[part 19 of 23: packages /Interfaces to /ComponentTypes]
AUTOSAR XML (schema 4-3-0)
package /Interfaces
  2014 x sender receiver interface:
    IF_AB_Abschaltanf_SIH_BF
      data DE_AB_Abschaltanf_SIH_BF: type=boolean
    IF_AB_Belegung_VB
      data DE_AB_Belegung_VB: type=uint8
    IF_AB_Belegung_VF
      data DE_AB_Belegung_VF: type=uint8
    IF_AB_Belegung_VF_ext
      data DE_AB_Belegung_VF_ext: type=uint8
    IF_AB_Crash_Int
      data DE_AB_Crash_Int: type=uint8
    IF_AB_Deaktivierung_HV
      data DE_AB_Deaktivierung_HV: type=uint8
    IF_AB_Gurtschloss_BF
      data DE_AB_Gurtschloss_BF: type=uint8
    IF_AB_Gurtschloss_FA
      data DE_AB_Gurtschloss_FA: type=uint8
    IF_AB_Gurtschloss_MI
      data DE_AB_Gurtschloss_MI: type=uint8
    IF_AB_Gurtschloss_Reihe2_BF
      data DE_AB_Gurtschloss_Reihe2_BF: type=uint8
    IF_AB_Gurtschloss_Reihe2_FA
      data DE_AB_Gurtschloss_Reihe2_FA: type=uint8
    IF_AB_Gurtschloss_Reihe2_MI
      data DE_AB_Gurtschloss_Reihe2_MI: type=uint8
    IF_AB_Gurtschloss_Reihe3_BF
      data DE_AB_Gurtschloss_Reihe3_BF: type=uint8
    IF_AB_Gurtschloss_Reihe3_FA
      data DE_AB_Gurtschloss_Reihe3_FA: type=uint8
    IF_AB_Gurtschloss_Reihe3_MI
      data DE_AB_Gurtschloss_Reihe3_MI: type=uint8
    IF_AB_Gurtwarn_Reihe2_BF
      data DE_AB_Gurtwarn_Reihe2_BF: type=uint8
    IF_AB_Gurtwarn_Reihe2_FA
      data DE_AB_Gurtwarn_Reihe2_FA: type=uint8
    IF_AB_Gurtwarn_Reihe2_MI
      data DE_AB_Gurtwarn_Reihe2_MI: type=uint8
    IF_AB_Gurtwarn_Reihe3_BF
      data DE_AB_Gurtwarn_Reihe3_BF: type=uint8
    IF_AB_Gurtwarn_Reihe3_FA
      data DE_AB_Gurtwarn_Reihe3_FA: type=uint8
    IF_AB_Gurtwarn_Reihe3_MI
      data DE_AB_Gurtwarn_Reihe3_MI: type=uint8
    IF_AB_Gurtwarn_VM
      data DE_AB_Gurtwarn_VM: type=boolean
    IF_AB_SBR_hinten_verbau
      data DE_AB_SBR_hinten_verbau: type=uint8
    IF_AB_Stellgliedtest
      data DE_AB_Stellgliedtest: type=boolean
    IF_ACT401_Adresse_Aktuator
      data DE_ACT401_Adresse_Aktuator: type=uint8
    IF_ACT401_Blockierung_aufgetreten
      data DE_ACT401_Blockierung_aufgetreten: type=uint8
    IF_ACT401_Drehrichtung
      data DE_ACT401_Drehrichtung: type=uint8
    IF_ACT401_Elektr_Defekt
      data DE_ACT401_Elektr_Defekt: type=uint8
    IF_ACT401_Freigabe_Blockiererkennung
      data DE_ACT401_Freigabe_Blockiererkennung: type=uint8
    IF_ACT401_Geschwindigkeitsstatus
      data DE_ACT401_Geschwindigkeitsstatus: type=uint8
    IF_ACT401_Ist_Position_Aktuator
      data DE_ACT401_Ist_Position_Aktuator: type=uint16
    IF_ACT401_Notlauf_aufgetreten
      data DE_ACT401_Notlauf_aufgetreten: type=uint8
    IF_ACT401_Notlauffreigabe
      data DE_ACT401_Notlauffreigabe: type=uint8
    IF_ACT401_Notlaufposition
      data DE_ACT401_Notlaufposition: type=uint8
    IF_ACT401_Positionsvorgabe_Status
      data DE_ACT401_Positionsvorgabe_Status: type=uint8
    IF_ACT401_Reset
      data DE_ACT401_Reset: type=uint8
    IF_ACT401_ResponseError
      data DE_ACT401_ResponseError: type=boolean
    IF_ACT401_Selbsthaltemoment
      data DE_ACT401_Selbsthaltemoment: type=uint8
    IF_ACT401_Sonderfunktionen
      data DE_ACT401_Sonderfunktionen: type=uint8
    IF_ACT401_Spulenbestromung
      data DE_ACT401_Spulenbestromung: type=uint8
    IF_ACT401_Stopmodus
      data DE_ACT401_Stopmodus: type=uint8
    IF_ACT401_Uebertemperatur
      data DE_ACT401_Uebertemperatur: type=uint8
    IF_ACT401_Variante
      data DE_ACT401_Variante: type=uint8
    IF_ACT401_Verfahrrichtung
      data DE_ACT401_Verfahrrichtung: type=uint8
    IF_ACT401_Versorgungsspannung
      data DE_ACT401_Versorgungsspannung: type=uint8
    IF_ACT402_Adresse_Aktuator
      data DE_ACT402_Adresse_Aktuator: type=uint8
    IF_ACT402_Blockierung_aufgetreten
      data DE_ACT402_Blockierung_aufgetreten: type=uint8
    IF_ACT402_Drehrichtung
      data DE_ACT402_Drehrichtung: type=uint8
    IF_ACT402_Elektr_Defekt
      data DE_ACT402_Elektr_Defekt: type=uint8
    IF_ACT402_Freigabe_Blockiererkennung
      data DE_ACT402_Freigabe_Blockiererkennung: type=uint8
    IF_ACT402_Geschwindigkeitsstatus
      data DE_ACT402_Geschwindigkeitsstatus: type=uint8
    IF_ACT402_Ist_Position_Aktuator
      data DE_ACT402_Ist_Position_Aktuator: type=uint16
    IF_ACT402_Notlauf_aufgetreten
      data DE_ACT402_Notlauf_aufgetreten: type=uint8
    IF_ACT402_Notlauffreigabe
      data DE_ACT402_Notlauffreigabe: type=uint8
    IF_ACT402_Notlaufposition
      data DE_ACT402_Notlaufposition: type=uint8
    IF_ACT402_Positionsvorgabe_Status
      data DE_ACT402_Positionsvorgabe_Status: type=uint8
    IF_ACT402_Reset
      data DE_ACT402_Reset: type=uint8
    IF_ACT402_ResponseError
      data DE_ACT402_ResponseError: type=boolean
    IF_ACT402_Selbsthaltemoment
      data DE_ACT402_Selbsthaltemoment: type=uint8
    IF_ACT402_Sonderfunktionen
      data DE_ACT402_Sonderfunktionen: type=uint8
    IF_ACT402_Spulenbestromung
      data DE_ACT402_Spulenbestromung: type=uint8
    IF_ACT402_Stopmodus
      data DE_ACT402_Stopmodus: type=uint8
    IF_ACT402_Uebertemperatur
      data DE_ACT402_Uebertemperatur: type=uint8
    IF_ACT402_Variante
      data DE_ACT402_Variante: type=uint8
    IF_ACT402_Verfahrrichtung
      data DE_ACT402_Verfahrrichtung: type=uint8
    IF_ACT402_Versorgungsspannung
      data DE_ACT402_Versorgungsspannung: type=uint8
    IF_ACT403_Adresse_Aktuator
      data DE_ACT403_Adresse_Aktuator: type=uint8
    IF_ACT403_Blockierung_aufgetreten
      data DE_ACT403_Blockierung_aufgetreten: type=uint8
    IF_ACT403_Drehrichtung
      data DE_ACT403_Drehrichtung: type=uint8
    IF_ACT403_Elektr_Defekt
      data DE_ACT403_Elektr_Defekt: type=uint8
    IF_ACT403_Freigabe_Blockiererkennung
      data DE_ACT403_Freigabe_Blockiererkennung: type=uint8
    IF_ACT403_Geschwindigkeitsstatus
      data DE_ACT403_Geschwindigkeitsstatus: type=uint8
    IF_ACT403_Ist_Position_Aktuator
      data DE_ACT403_Ist_Position_Aktuator: type=uint16
    IF_ACT403_Notlauf_aufgetreten
      data DE_ACT403_Notlauf_aufgetreten: type=uint8
    IF_ACT403_Notlauffreigabe
      data DE_ACT403_Notlauffreigabe: type=uint8
    IF_ACT403_Notlaufposition
      data DE_ACT403_Notlaufposition: type=uint8
    IF_ACT403_Positionsvorgabe_Status
      data DE_ACT403_Positionsvorgabe_Status: type=uint8
    IF_ACT403_Reset
      data DE_ACT403_Reset: type=uint8
    IF_ACT403_ResponseError
      data DE_ACT403_ResponseError: type=boolean
    IF_ACT403_Selbsthaltemoment
      data DE_ACT403_Selbsthaltemoment: type=uint8
    IF_ACT403_Sonderfunktionen
      data DE_ACT403_Sonderfunktionen: type=uint8
    IF_ACT403_Spulenbestromung
      data DE_ACT403_Spulenbestromung: type=uint8
    IF_ACT403_Stopmodus
      data DE_ACT403_Stopmodus: type=uint8
    IF_ACT403_Uebertemperatur
      data DE_ACT403_Uebertemperatur: type=uint8
    IF_ACT403_Variante
      data DE_ACT403_Variante: type=uint8
    IF_ACT403_Verfahrrichtung
      data DE_ACT403_Verfahrrichtung: type=uint8
    IF_ACT403_Versorgungsspannung
      data DE_ACT403_Versorgungsspannung: type=uint8
    IF_ACT404_Adresse_Aktuator
      data DE_ACT404_Adresse_Aktuator: type=uint8
    IF_ACT404_Blockierung_aufgetreten
      data DE_ACT404_Blockierung_aufgetreten: type=uint8
    IF_ACT404_Drehrichtung
      data DE_ACT404_Drehrichtung: type=uint8
    IF_ACT404_Elektr_Defekt
      data DE_ACT404_Elektr_Defekt: type=uint8
    IF_ACT404_Freigabe_Blockiererkennung
      data DE_ACT404_Freigabe_Blockiererkennung: type=uint8
    IF_ACT404_Geschwindigkeitsstatus
      data DE_ACT404_Geschwindigkeitsstatus: type=uint8
    IF_ACT404_Ist_Position_Aktuator
      data DE_ACT404_Ist_Position_Aktuator: type=uint16
    IF_ACT404_Notlauf_aufgetreten
      data DE_ACT404_Notlauf_aufgetreten: type=uint8
    IF_ACT404_Notlauffreigabe
      data DE_ACT404_Notlauffreigabe: type=uint8
    IF_ACT404_Notlaufposition
      data DE_ACT404_Notlaufposition: type=uint8
    IF_ACT404_Positionsvorgabe_Status
      data DE_ACT404_Positionsvorgabe_Status: type=uint8
    IF_ACT404_Reset
      data DE_ACT404_Reset: type=uint8
    IF_ACT404_ResponseError
      data DE_ACT404_ResponseError: type=boolean
    IF_ACT404_Selbsthaltemoment
      data DE_ACT404_Selbsthaltemoment: type=uint8
    IF_ACT404_Sonderfunktionen
      data DE_ACT404_Sonderfunktionen: type=uint8
    IF_ACT404_Spulenbestromung
      data DE_ACT404_Spulenbestromung: type=uint8
    IF_ACT404_Stopmodus
      data DE_ACT404_Stopmodus: type=uint8
    IF_ACT404_Uebertemperatur
      data DE_ACT404_Uebertemperatur: type=uint8
    IF_ACT404_Variante
      data DE_ACT404_Variante: type=uint8
    IF_ACT404_Verfahrrichtung
      data DE_ACT404_Verfahrrichtung: type=uint8
    IF_ACT404_Versorgungsspannung
      data DE_ACT404_Versorgungsspannung: type=uint8
    IF_ACT405_Adresse_Aktuator
      data DE_ACT405_Adresse_Aktuator: type=uint8
    IF_ACT405_Blockierung_aufgetreten
      data DE_ACT405_Blockierung_aufgetreten: type=uint8
    IF_ACT405_Drehrichtung
      data DE_ACT405_Drehrichtung: type=uint8
    IF_ACT405_Elektr_Defekt
      data DE_ACT405_Elektr_Defekt: type=uint8
    IF_ACT405_Freigabe_Blockiererkennung
      data DE_ACT405_Freigabe_Blockiererkennung: type=uint8
    IF_ACT405_Geschwindigkeitsstatus
      data DE_ACT405_Geschwindigkeitsstatus: type=uint8
    IF_ACT405_Ist_Position_Aktuator
      data DE_ACT405_Ist_Position_Aktuator: type=uint16
    IF_ACT405_Notlauf_aufgetreten
      data DE_ACT405_Notlauf_aufgetreten: type=uint8
    IF_ACT405_Notlauffreigabe
      data DE_ACT405_Notlauffreigabe: type=uint8
    IF_ACT405_Notlaufposition
      data DE_ACT405_Notlaufposition: type=uint8
    IF_ACT405_Positionsvorgabe_Status
      data DE_ACT405_Positionsvorgabe_Status: type=uint8
    IF_ACT405_Reset
      data DE_ACT405_Reset: type=uint8
    IF_ACT405_ResponseError
      data DE_ACT405_ResponseError: type=boolean
    IF_ACT405_Selbsthaltemoment
      data DE_ACT405_Selbsthaltemoment: type=uint8
    IF_ACT405_Sonderfunktionen
      data DE_ACT405_Sonderfunktionen: type=uint8
    IF_ACT405_Spulenbestromung
      data DE_ACT405_Spulenbestromung: type=uint8
    IF_ACT405_Stopmodus
      data DE_ACT405_Stopmodus: type=uint8
    IF_ACT405_Uebertemperatur
      data DE_ACT405_Uebertemperatur: type=uint8
    IF_ACT405_Variante
      data DE_ACT405_Variante: type=uint8
    IF_ACT405_Verfahrrichtung
      data DE_ACT405_Verfahrrichtung: type=uint8
    IF_ACT405_Versorgungsspannung
      data DE_ACT405_Versorgungsspannung: type=uint8
    IF_ACT406_Adresse_Aktuator
      data DE_ACT406_Adresse_Aktuator: type=uint8
    IF_ACT406_Blockierung_aufgetreten
      data DE_ACT406_Blockierung_aufgetreten: type=uint8
    IF_ACT406_Drehrichtung
      data DE_ACT406_Drehrichtung: type=uint8
    IF_ACT406_Elektr_Defekt
      data DE_ACT406_Elektr_Defekt: type=uint8
    IF_ACT406_Freigabe_Blockiererkennung
      data DE_ACT406_Freigabe_Blockiererkennung: type=uint8
    IF_ACT406_Geschwindigkeitsstatus
      data DE_ACT406_Geschwindigkeitsstatus: type=uint8
    IF_ACT406_Ist_Position_Aktuator
      data DE_ACT406_Ist_Position_Aktuator: type=uint16
    IF_ACT406_Notlauf_aufgetreten
      data DE_ACT406_Notlauf_aufgetreten: type=uint8
    IF_ACT406_Notlauffreigabe
      data DE_ACT406_Notlauffreigabe: type=uint8
    IF_ACT406_Notlaufposition
      data DE_ACT406_Notlaufposition: type=uint8
    IF_ACT406_Positionsvorgabe_Status
      data DE_ACT406_Positionsvorgabe_Status: type=uint8
    IF_ACT406_Reset
      data DE_ACT406_Reset: type=uint8
    IF_ACT406_ResponseError
      data DE_ACT406_ResponseError: type=boolean
    IF_ACT406_Selbsthaltemoment
      data DE_ACT406_Selbsthaltemoment: type=uint8
    IF_ACT406_Sonderfunktionen
      data DE_ACT406_Sonderfunktionen: type=uint8
    IF_ACT406_Spulenbestromung
      data DE_ACT406_Spulenbestromung: type=uint8
    IF_ACT406_Stopmodus
      data DE_ACT406_Stopmodus: type=uint8
    IF_ACT406_Uebertemperatur
      data DE_ACT406_Uebertemperatur: type=uint8
    IF_ACT406_Variante
      data DE_ACT406_Variante: type=uint8
    IF_ACT406_Verfahrrichtung
      data DE_ACT406_Verfahrrichtung: type=uint8
    IF_ACT406_Versorgungsspannung
      data DE_ACT406_Versorgungsspannung: type=uint8
    IF_ACT407_Adresse_Aktuator
      data DE_ACT407_Adresse_Aktuator: type=uint8
    IF_ACT407_Blockierung_aufgetreten
      data DE_ACT407_Blockierung_aufgetreten: type=uint8
    IF_ACT407_Drehrichtung
      data DE_ACT407_Drehrichtung: type=uint8
    IF_ACT407_Elektr_Defekt
      data DE_ACT407_Elektr_Defekt: type=uint8
    IF_ACT407_Freigabe_Blockiererkennung
      data DE_ACT407_Freigabe_Blockiererkennung: type=uint8
    IF_ACT407_Geschwindigkeitsstatus
      data DE_ACT407_Geschwindigkeitsstatus: type=uint8
    IF_ACT407_Ist_Position_Aktuator
      data DE_ACT407_Ist_Position_Aktuator: type=uint16
    IF_ACT407_Notlauf_aufgetreten
      data DE_ACT407_Notlauf_aufgetreten: type=uint8
    IF_ACT407_Notlauffreigabe
      data DE_ACT407_Notlauffreigabe: type=uint8
    IF_ACT407_Notlaufposition
      data DE_ACT407_Notlaufposition: type=uint8
    IF_ACT407_Positionsvorgabe_Status
      data DE_ACT407_Positionsvorgabe_Status: type=uint8
    IF_ACT407_Reset
      data DE_ACT407_Reset: type=uint8
    IF_ACT407_ResponseError
      data DE_ACT407_ResponseError: type=boolean
    IF_ACT407_Selbsthaltemoment
      data DE_ACT407_Selbsthaltemoment: type=uint8
    IF_ACT407_Sonderfunktionen
      data DE_ACT407_Sonderfunktionen: type=uint8
    IF_ACT407_Spulenbestromung
      data DE_ACT407_Spulenbestromung: type=uint8
    IF_ACT407_Stopmodus
      data DE_ACT407_Stopmodus: type=uint8
    IF_ACT407_Uebertemperatur
      data DE_ACT407_Uebertemperatur: type=uint8
    IF_ACT407_Variante
      data DE_ACT407_Variante: type=uint8
    IF_ACT407_Verfahrrichtung
      data DE_ACT407_Verfahrrichtung: type=uint8
    IF_ACT407_Versorgungsspannung
      data DE_ACT407_Versorgungsspannung: type=uint8
    IF_ACT408_Adresse_Aktuator
      data DE_ACT408_Adresse_Aktuator: type=uint8
    IF_ACT408_Blockierung_aufgetreten
      data DE_ACT408_Blockierung_aufgetreten: type=uint8
    IF_ACT408_Drehrichtung
      data DE_ACT408_Drehrichtung: type=uint8
    IF_ACT408_Elektr_Defekt
      data DE_ACT408_Elektr_Defekt: type=uint8
    IF_ACT408_Freigabe_Blockiererkennung
      data DE_ACT408_Freigabe_Blockiererkennung: type=uint8
    IF_ACT408_Geschwindigkeitsstatus
      data DE_ACT408_Geschwindigkeitsstatus: type=uint8
    IF_ACT408_Ist_Position_Aktuator
      data DE_ACT408_Ist_Position_Aktuator: type=uint16
    IF_ACT408_Notlauf_aufgetreten
      data DE_ACT408_Notlauf_aufgetreten: type=uint8
    IF_ACT408_Notlauffreigabe
      data DE_ACT408_Notlauffreigabe: type=uint8
    IF_ACT408_Notlaufposition
      data DE_ACT408_Notlaufposition: type=uint8
    IF_ACT408_Positionsvorgabe_Status
      data DE_ACT408_Positionsvorgabe_Status: type=uint8
    IF_ACT408_Reset
      data DE_ACT408_Reset: type=uint8
    IF_ACT408_ResponseError
      data DE_ACT408_ResponseError: type=boolean
    IF_ACT408_Selbsthaltemoment
      data DE_ACT408_Selbsthaltemoment: type=uint8
    IF_ACT408_Sonderfunktionen
      data DE_ACT408_Sonderfunktionen: type=uint8
    IF_ACT408_Spulenbestromung
      data DE_ACT408_Spulenbestromung: type=uint8
    IF_ACT408_Stopmodus
      data DE_ACT408_Stopmodus: type=uint8
    IF_ACT408_Uebertemperatur
      data DE_ACT408_Uebertemperatur: type=uint8
    IF_ACT408_Variante
      data DE_ACT408_Variante: type=uint8
    IF_ACT408_Verfahrrichtung
      data DE_ACT408_Verfahrrichtung: type=uint8
    IF_ACT408_Versorgungsspannung
      data DE_ACT408_Versorgungsspannung: type=uint8
    IF_ACT409_Adresse_Aktuator
      data DE_ACT409_Adresse_Aktuator: type=uint8
    IF_ACT409_Blockierung_aufgetreten
      data DE_ACT409_Blockierung_aufgetreten: type=uint8
    IF_ACT409_Drehrichtung
      data DE_ACT409_Drehrichtung: type=uint8
    IF_ACT409_Elektr_Defekt
      data DE_ACT409_Elektr_Defekt: type=uint8
    IF_ACT409_Freigabe_Blockiererkennung
      data DE_ACT409_Freigabe_Blockiererkennung: type=uint8
    IF_ACT409_Geschwindigkeitsstatus
      data DE_ACT409_Geschwindigkeitsstatus: type=uint8
    IF_ACT409_Ist_Position_Aktuator
      data DE_ACT409_Ist_Position_Aktuator: type=uint16
    IF_ACT409_Notlauf_aufgetreten
      data DE_ACT409_Notlauf_aufgetreten: type=uint8
    IF_ACT409_Notlauffreigabe
      data DE_ACT409_Notlauffreigabe: type=uint8
    IF_ACT409_Notlaufposition
      data DE_ACT409_Notlaufposition: type=uint8
    IF_ACT409_Positionsvorgabe_Status
      data DE_ACT409_Positionsvorgabe_Status: type=uint8
    IF_ACT409_Reset
      data DE_ACT409_Reset: type=uint8
    IF_ACT409_ResponseError
      data DE_ACT409_ResponseError: type=boolean
    IF_ACT409_Selbsthaltemoment
      data DE_ACT409_Selbsthaltemoment: type=uint8
    IF_ACT409_Sonderfunktionen
      data DE_ACT409_Sonderfunktionen: type=uint8
    IF_ACT409_Spulenbestromung
      data DE_ACT409_Spulenbestromung: type=uint8
    IF_ACT409_Stopmodus
      data DE_ACT409_Stopmodus: type=uint8
    IF_ACT409_Uebertemperatur
      data DE_ACT409_Uebertemperatur: type=uint8
    IF_ACT409_Variante
      data DE_ACT409_Variante: type=uint8
    IF_ACT409_Verfahrrichtung
      data DE_ACT409_Verfahrrichtung: type=uint8
    IF_ACT409_Versorgungsspannung
      data DE_ACT409_Versorgungsspannung: type=uint8
    IF_ACT410_Adresse_Aktuator
      data DE_ACT410_Adresse_Aktuator: type=uint8
    IF_ACT410_Blockierung_aufgetreten
      data DE_ACT410_Blockierung_aufgetreten: type=uint8
    IF_ACT410_Drehrichtung
      data DE_ACT410_Drehrichtung: type=uint8
    IF_ACT410_Elektr_Defekt
      data DE_ACT410_Elektr_Defekt: type=uint8
    IF_ACT410_Freigabe_Blockiererkennung
      data DE_ACT410_Freigabe_Blockiererkennung: type=uint8
    IF_ACT410_Geschwindigkeitsstatus
      data DE_ACT410_Geschwindigkeitsstatus: type=uint8
    IF_ACT410_Ist_Position_Aktuator
      data DE_ACT410_Ist_Position_Aktuator: type=uint16
    IF_ACT410_Notlauf_aufgetreten
      data DE_ACT410_Notlauf_aufgetreten: type=uint8
    IF_ACT410_Notlauffreigabe
      data DE_ACT410_Notlauffreigabe: type=uint8
    IF_ACT410_Notlaufposition
      data DE_ACT410_Notlaufposition: type=uint8
    IF_ACT410_Positionsvorgabe_Status
      data DE_ACT410_Positionsvorgabe_Status: type=uint8
    IF_ACT410_Reset
      data DE_ACT410_Reset: type=uint8
    IF_ACT410_ResponseError
      data DE_ACT410_ResponseError: type=boolean
    IF_ACT410_Selbsthaltemoment
      data DE_ACT410_Selbsthaltemoment: type=uint8
    IF_ACT410_Sonderfunktionen
      data DE_ACT410_Sonderfunktionen: type=uint8
    IF_ACT410_Spulenbestromung
      data DE_ACT410_Spulenbestromung: type=uint8
    IF_ACT410_Stopmodus
      data DE_ACT410_Stopmodus: type=uint8
    IF_ACT410_Uebertemperatur
      data DE_ACT410_Uebertemperatur: type=uint8
    IF_ACT410_Variante
      data DE_ACT410_Variante: type=uint8
    IF_ACT410_Verfahrrichtung
      data DE_ACT410_Verfahrrichtung: type=uint8
    IF_ACT410_Versorgungsspannung
      data DE_ACT410_Versorgungsspannung: type=uint8
    IF_ACT411_Adresse_Aktuator
      data DE_ACT411_Adresse_Aktuator: type=uint8
    IF_ACT411_Blockierung_aufgetreten
      data DE_ACT411_Blockierung_aufgetreten: type=uint8
    IF_ACT411_Drehrichtung
      data DE_ACT411_Drehrichtung: type=uint8
    IF_ACT411_Elektr_Defekt
      data DE_ACT411_Elektr_Defekt: type=uint8
    IF_ACT411_Freigabe_Blockiererkennung
      data DE_ACT411_Freigabe_Blockiererkennung: type=uint8
    IF_ACT411_Geschwindigkeitsstatus
      data DE_ACT411_Geschwindigkeitsstatus: type=uint8
    IF_ACT411_Ist_Position_Aktuator
      data DE_ACT411_Ist_Position_Aktuator: type=uint16
    IF_ACT411_Notlauf_aufgetreten
      data DE_ACT411_Notlauf_aufgetreten: type=uint8
    IF_ACT411_Notlauffreigabe
      data DE_ACT411_Notlauffreigabe: type=uint8
    IF_ACT411_Notlaufposition
      data DE_ACT411_Notlaufposition: type=uint8
    IF_ACT411_Positionsvorgabe_Status
      data DE_ACT411_Positionsvorgabe_Status: type=uint8
    IF_ACT411_Reset
      data DE_ACT411_Reset: type=uint8
    IF_ACT411_ResponseError
      data DE_ACT411_ResponseError: type=boolean
    IF_ACT411_Selbsthaltemoment
      data DE_ACT411_Selbsthaltemoment: type=uint8
    IF_ACT411_Sonderfunktionen
      data DE_ACT411_Sonderfunktionen: type=uint8
    IF_ACT411_Spulenbestromung
      data DE_ACT411_Spulenbestromung: type=uint8
    IF_ACT411_Stopmodus
      data DE_ACT411_Stopmodus: type=uint8
    IF_ACT411_Uebertemperatur
      data DE_ACT411_Uebertemperatur: type=uint8
    IF_ACT411_Variante
      data DE_ACT411_Variante: type=uint8
    IF_ACT411_Verfahrrichtung
      data DE_ACT411_Verfahrrichtung: type=uint8
    IF_ACT411_Versorgungsspannung
      data DE_ACT411_Versorgungsspannung: type=uint8
    IF_ACT412_Adresse_Aktuator
      data DE_ACT412_Adresse_Aktuator: type=uint8
    IF_ACT412_Blockierung_aufgetreten
      data DE_ACT412_Blockierung_aufgetreten: type=uint8
    IF_ACT412_Drehrichtung
      data DE_ACT412_Drehrichtung: type=uint8
    IF_ACT412_Elektr_Defekt
      data DE_ACT412_Elektr_Defekt: type=uint8
    IF_ACT412_Freigabe_Blockiererkennung
      data DE_ACT412_Freigabe_Blockiererkennung: type=uint8
    IF_ACT412_Geschwindigkeitsstatus
      data DE_ACT412_Geschwindigkeitsstatus: type=uint8
    IF_ACT412_Ist_Position_Aktuator
      data DE_ACT412_Ist_Position_Aktuator: type=uint16
    IF_ACT412_Notlauf_aufgetreten
      data DE_ACT412_Notlauf_aufgetreten: type=uint8
    IF_ACT412_Notlauffreigabe
      data DE_ACT412_Notlauffreigabe: type=uint8
    IF_ACT412_Notlaufposition
      data DE_ACT412_Notlaufposition: type=uint8
    IF_ACT412_Positionsvorgabe_Status
      data DE_ACT412_Positionsvorgabe_Status: type=uint8
    IF_ACT412_Reset
      data DE_ACT412_Reset: type=uint8
    IF_ACT412_ResponseError
      data DE_ACT412_ResponseError: type=boolean
    IF_ACT412_Selbsthaltemoment
      data DE_ACT412_Selbsthaltemoment: type=uint8
    IF_ACT412_Sonderfunktionen
      data DE_ACT412_Sonderfunktionen: type=uint8
    IF_ACT412_Spulenbestromung
      data DE_ACT412_Spulenbestromung: type=uint8
    IF_ACT412_Stopmodus
      data DE_ACT412_Stopmodus: type=uint8
    IF_ACT412_Uebertemperatur
      data DE_ACT412_Uebertemperatur: type=uint8
    IF_ACT412_Variante
      data DE_ACT412_Variante: type=uint8
    IF_ACT412_Verfahrrichtung
      data DE_ACT412_Verfahrrichtung: type=uint8
    IF_ACT412_Versorgungsspannung
      data DE_ACT412_Versorgungsspannung: type=uint8
    IF_Adresse_ION
      data DE_Adresse_ION: type=uint8
    IF_Adresse_PCU
      data DE_Adresse_PCU: type=uint8
    IF_Adressegment_ION
      data DE_Adressegment_ION: type=uint8
    IF_Anlernen_LLR_li
      data DE_Anlernen_LLR_li: type=boolean
    IF_Anlernen_LLR_re
      data DE_Anlernen_LLR_re: type=boolean
    IF_AQS_COBereich
      data DE_AQS_COBereich: type=uint8
    IF_AQS_COStatus
      data DE_AQS_COStatus: type=uint8
    IF_AQS_COWert
      data DE_AQS_COWert: type=uint16
    IF_AQS_HW
      data DE_AQS_HW: type=uint8
    IF_AQS_Luftguete
      data DE_AQS_Luftguete: type=uint8
    IF_AQS_NoxBereich
      data DE_AQS_NoxBereich: type=uint8
    IF_AQS_NoxStatus
      data DE_AQS_NoxStatus: type=uint8
    IF_AQS_NoxWert
      data DE_AQS_NoxWert: type=uint16
    IF_AQS_Parameter
      data DE_AQS_Parameter: type=uint16
    IF_AQS_ResponseError
      data DE_AQS_ResponseError: type=boolean
    IF_AQS_Sensorheizung
      data DE_AQS_Sensorheizung: type=boolean
    IF_AQS_Sensorheizung_Status
      data DE_AQS_Sensorheizung_Status: type=boolean
    IF_AQS_SW
      data DE_AQS_SW: type=uint8
    IF_AQS_Toggle
      data DE_AQS_Toggle: type=uint8
    IF_AQS_Traffic
      data DE_AQS_Traffic: type=uint8
    IF_Aussentemp_ungef
      data DE_Aussentemp_ungef: type=uint8
    IF_BCM1_Aussen_Temp_ungef
      data DE_BCM1_Aussen_Temp_ungef: type=uint8
    IF_BCM1_FStatus_Aussentemp_ungef
      data DE_BCM1_FStatus_Aussentemp_ungef: type=boolean
    IF_BCM1_OBD_FStatus_ATemp
      data DE_BCM1_OBD_FStatus_ATemp: type=uint8
    IF_BCM1_Rueckfahrlicht_Schalter
      data DE_BCM1_Rueckfahrlicht_Schalter: type=boolean
    IF_BCM_Remotestart_Betrieb
      data DE_BCM_Remotestart_Betrieb: type=boolean
    IF_BEM_Red_Innengeblaese
      data DE_BEM_Red_Innengeblaese: type=uint8
    IF_BLOWER1_HW
      data DE_BLOWER1_HW: type=uint8
    IF_BLOWER1_IBATT
      data DE_BLOWER1_IBATT: type=uint8
    IF_BLOWER1_IMAX_MAX
      data DE_BLOWER1_IMAX_MAX: type=uint8
    IF_BLOWER1_IMAX_MIN
      data DE_BLOWER1_IMAX_MIN: type=uint8
    IF_BLOWER1_RAMP
      data DE_BLOWER1_RAMP: type=uint8
    IF_BLOWER1_ResponseError
      data DE_BLOWER1_ResponseError: type=boolean
    IF_BLOWER1_RX_FREQUENCY
      data DE_BLOWER1_RX_FREQUENCY: type=uint16
    IF_BLOWER1_SAFETY_SPEED
      data DE_BLOWER1_SAFETY_SPEED: type=uint8
    IF_BLOWER1_SAFETYRUN_THRESHOLD
      data DE_BLOWER1_SAFETYRUN_THRESHOLD: type=uint8
    IF_BLOWER1_SELECT
      data DE_BLOWER1_SELECT: type=uint8
    IF_BLOWER1_SPEED
      data DE_BLOWER1_SPEED: type=uint8
    IF_BLOWER1_STATUS1
      data DE_BLOWER1_STATUS1: type=uint8
    IF_BLOWER1_STATUS2
      data DE_BLOWER1_STATUS2: type=uint8
    IF_BLOWER1_SUPPLIER
      data DE_BLOWER1_SUPPLIER: type=uint8
    IF_BLOWER1_SW
      data DE_BLOWER1_SW: type=uint8
    IF_BLOWER1_TEMPERATURE
      data DE_BLOWER1_TEMPERATURE: type=uint8
    IF_BLOWER1_U_KNEE
      data DE_BLOWER1_U_KNEE: type=uint8
    IF_BLOWER1_UBATT
      data DE_BLOWER1_UBATT: type=uint8
    IF_BLOWER1_UMOTOR
      data DE_BLOWER1_UMOTOR: type=uint8
    IF_BLOWER1b_HW
      data DE_BLOWER1b_HW: type=uint8
    IF_BLOWER1b_IBATT
      data DE_BLOWER1b_IBATT: type=uint8
    IF_BLOWER1b_IMAX_MAX
      data DE_BLOWER1b_IMAX_MAX: type=uint8
    IF_BLOWER1b_IMAX_MIN
      data DE_BLOWER1b_IMAX_MIN: type=uint8
    IF_BLOWER1b_RAMP
      data DE_BLOWER1b_RAMP: type=uint8
    IF_BLOWER1b_ResponseError
      data DE_BLOWER1b_ResponseError: type=boolean
    IF_BLOWER1b_RX_FREQUENCY
      data DE_BLOWER1b_RX_FREQUENCY: type=uint16
    IF_BLOWER1b_SAFETY_SPEED
      data DE_BLOWER1b_SAFETY_SPEED: type=uint8
    IF_BLOWER1b_SAFETYRUN_THRESHOLD
      data DE_BLOWER1b_SAFETYRUN_THRESHOLD: type=uint8
    IF_BLOWER1b_SELECT
      data DE_BLOWER1b_SELECT: type=uint8
    IF_BLOWER1b_SPEED
      data DE_BLOWER1b_SPEED: type=uint8
    IF_BLOWER1b_STATUS1
      data DE_BLOWER1b_STATUS1: type=uint8
    IF_BLOWER1b_STATUS2
      data DE_BLOWER1b_STATUS2: type=uint8
    IF_BLOWER1b_SUPPLIER
      data DE_BLOWER1b_SUPPLIER: type=uint8
    IF_BLOWER1b_SW
      data DE_BLOWER1b_SW: type=uint8
    IF_BLOWER1b_TEMPERATURE
      data DE_BLOWER1b_TEMPERATURE: type=uint8
    IF_BLOWER1b_U_KNEE
      data DE_BLOWER1b_U_KNEE: type=uint8
    IF_BLOWER1b_UBATT
      data DE_BLOWER1b_UBATT: type=uint8
    IF_BLOWER1b_UMOTOR
      data DE_BLOWER1b_UMOTOR: type=uint8
    IF_BLOWER1c_HW
      data DE_BLOWER1c_HW: type=uint8
    IF_BLOWER1c_IBATT
      data DE_BLOWER1c_IBATT: type=uint8
    IF_BLOWER1c_IMAX_MAX
      data DE_BLOWER1c_IMAX_MAX: type=uint8
    IF_BLOWER1c_IMAX_MIN
      data DE_BLOWER1c_IMAX_MIN: type=uint8
    IF_BLOWER1c_RAMP
      data DE_BLOWER1c_RAMP: type=uint8
    IF_BLOWER1c_ResponseError
      data DE_BLOWER1c_ResponseError: type=boolean
    IF_BLOWER1c_RX_FREQUENCY
      data DE_BLOWER1c_RX_FREQUENCY: type=uint16
    IF_BLOWER1c_SAFETY_SPEED
      data DE_BLOWER1c_SAFETY_SPEED: type=uint8
    IF_BLOWER1c_SAFETYRUN_THRESHOLD
      data DE_BLOWER1c_SAFETYRUN_THRESHOLD: type=uint8
    IF_BLOWER1c_SELECT
      data DE_BLOWER1c_SELECT: type=uint8
    IF_BLOWER1c_SPEED
      data DE_BLOWER1c_SPEED: type=uint8
    IF_BLOWER1c_STATUS1
      data DE_BLOWER1c_STATUS1: type=uint8
    IF_BLOWER1c_STATUS2
      data DE_BLOWER1c_STATUS2: type=uint8
    IF_BLOWER1c_SUPPLIER
      data DE_BLOWER1c_SUPPLIER: type=uint8
    IF_BLOWER1c_SW
      data DE_BLOWER1c_SW: type=uint8
    IF_BLOWER1c_TEMPERATURE
      data DE_BLOWER1c_TEMPERATURE: type=uint8
    IF_BLOWER1c_U_KNEE
      data DE_BLOWER1c_U_KNEE: type=uint8
    IF_BLOWER1c_UBATT
      data DE_BLOWER1c_UBATT: type=uint8
    IF_BLOWER1c_UMOTOR
      data DE_BLOWER1c_UMOTOR: type=uint8
    IF_BLOWER2_HW
      data DE_BLOWER2_HW: type=uint8
    IF_BLOWER2_IBATT
      data DE_BLOWER2_IBATT: type=uint8
    IF_BLOWER2_ResponseError
      data DE_BLOWER2_ResponseError: type=boolean
    IF_BLOWER2_STATUS1
      data DE_BLOWER2_STATUS1: type=uint8
    IF_BLOWER2_STATUS1_INVALID
      data DE_BLOWER2_STATUS1_INVALID: type=boolean
    IF_BLOWER2_STATUS2
      data DE_BLOWER2_STATUS2: type=uint8
    IF_BLOWER2_SUPPLIER
      data DE_BLOWER2_SUPPLIER: type=uint8
    IF_BLOWER2_SW
      data DE_BLOWER2_SW: type=uint8
    IF_BLOWER2_TEMPERATURE
      data DE_BLOWER2_TEMPERATURE: type=uint8
    IF_BLOWER2_UBATT
      data DE_BLOWER2_UBATT: type=uint8
    IF_BLOWER2_UMOTOR
      data DE_BLOWER2_UMOTOR: type=uint8
    IF_BLOWER2b_HW
      data DE_BLOWER2b_HW: type=uint8
    IF_BLOWER2b_IBATT
      data DE_BLOWER2b_IBATT: type=uint8
    IF_BLOWER2b_ResponseError
      data DE_BLOWER2b_ResponseError: type=boolean
    IF_BLOWER2b_STATUS1
      data DE_BLOWER2b_STATUS1: type=uint8
    IF_BLOWER2b_STATUS1_INVALID
      data DE_BLOWER2b_STATUS1_INVALID: type=boolean
    IF_BLOWER2b_STATUS2
      data DE_BLOWER2b_STATUS2: type=uint8
    IF_BLOWER2b_SUPPLIER
      data DE_BLOWER2b_SUPPLIER: type=uint8
    IF_BLOWER2b_SW
      data DE_BLOWER2b_SW: type=uint8
    IF_BLOWER2b_TEMPERATURE
      data DE_BLOWER2b_TEMPERATURE: type=uint8
    IF_BLOWER2b_UBATT
      data DE_BLOWER2b_UBATT: type=uint8
    IF_BLOWER2b_UMOTOR
      data DE_BLOWER2b_UMOTOR: type=uint8
    IF_BLOWER2be_IMAX_MAX
      data DE_BLOWER2be_IMAX_MAX: type=uint8
    IF_BLOWER2be_IMAX_MIN
      data DE_BLOWER2be_IMAX_MIN: type=uint8
    IF_BLOWER2be_RAMP
      data DE_BLOWER2be_RAMP: type=uint8
    IF_BLOWER2be_RX_FREQUENCY
      data DE_BLOWER2be_RX_FREQUENCY: type=uint16
    IF_BLOWER2be_SAFETY_SPEED
      data DE_BLOWER2be_SAFETY_SPEED: type=uint8
    IF_BLOWER2be_SAFETYRUN_THRESHOLD
      data DE_BLOWER2be_SAFETYRUN_THRESHOLD: type=uint8
    IF_BLOWER2be_SELECT
      data DE_BLOWER2be_SELECT: type=uint8
    IF_BLOWER2be_SPEED
      data DE_BLOWER2be_SPEED: type=uint8
    IF_BLOWER2be_U_KNEE
      data DE_BLOWER2be_U_KNEE: type=uint8
    IF_BLOWER2e_IMAX_MAX
      data DE_BLOWER2e_IMAX_MAX: type=uint8
    IF_BLOWER2e_IMAX_MIN
      data DE_BLOWER2e_IMAX_MIN: type=uint8
    IF_BLOWER2e_RAMP
      data DE_BLOWER2e_RAMP: type=uint8
    IF_BLOWER2e_RX_FREQUENCY
      data DE_BLOWER2e_RX_FREQUENCY: type=uint16
    IF_BLOWER2e_SAFETY_SPEED
      data DE_BLOWER2e_SAFETY_SPEED: type=uint8
    IF_BLOWER2e_SAFETYRUN_THRESHOLD
      data DE_BLOWER2e_SAFETYRUN_THRESHOLD: type=uint8
    IF_BLOWER2e_SELECT
      data DE_BLOWER2e_SELECT: type=uint8
    IF_BLOWER2e_SPEED
      data DE_BLOWER2e_SPEED: type=uint8
    IF_BLOWER2e_U_KNEE
      data DE_BLOWER2e_U_KNEE: type=uint8
    IF_BLOWER_DIAG_FLAG1
      data DE_BLOWER_DIAG_FLAG1: type=uint8
    IF_BLOWER_DIAG_FLAG2
      data DE_BLOWER_DIAG_FLAG2: type=uint8
    IF_BLOWER_IBATT
      data DE_BLOWER_IBATT: type=uint8
    IF_BLOWER_ResponseError
      data DE_BLOWER_ResponseError: type=boolean
    IF_BLOWER_ROTATION_SPEED
      data DE_BLOWER_ROTATION_SPEED: type=uint8
    IF_BLOWER_STATUS_MOTOR
      data DE_BLOWER_STATUS_MOTOR: type=uint8
    IF_BLOWER_SUPPLIER
      data DE_BLOWER_SUPPLIER: type=uint8
    IF_BLOWER_TEMPERATURE
      data DE_BLOWER_TEMPERATURE: type=uint8
    IF_BLOWER_TORQUE
      data DE_BLOWER_TORQUE: type=uint16
    IF_BLOWER_UBATT
      data DE_BLOWER_UBATT: type=uint8
    IF_BLOWER_UMOTOR
      data DE_BLOWER_UMOTOR: type=uint8
    IF_BMS_BattHeizung_Anf
      data DE_BMS_BattHeizung_Anf: type=uint8
    IF_BMS_DC_Ladeprofil
      data DE_BMS_DC_Ladeprofil: type=uint8
    IF_BMS_Fehler_NTKreis
      data DE_BMS_Fehler_NTKreis: type=boolean
    IF_BMS_Kuehlung_Anf
      data DE_BMS_Kuehlung_Anf: type=uint8
    IF_BMS_KundenWarnung
      data DE_BMS_KundenWarnung: type=uint8
    IF_BMS_Ladezustand
      data DE_BMS_Ladezustand: type=uint16
    IF_BMS_Pumpe1_Ansteuerung
      data DE_BMS_Pumpe1_Ansteuerung: type=uint8
    IF_BMS_Pumpe2_Ansteuerung
      data DE_BMS_Pumpe2_Ansteuerung: type=uint8
    IF_BMS_RuecklaufTemperatur
      data DE_BMS_RuecklaufTemperatur: type=uint8
    IF_BMS_SollVorlauftemperatur
      data DE_BMS_SollVorlauftemperatur: type=uint8
    IF_BMS_Spannung
      data DE_BMS_Spannung: type=uint16
    IF_BMS_Status_Ventil1
      data DE_BMS_Status_Ventil1: type=uint8
    IF_BMS_Status_Ventil2
      data DE_BMS_Status_Ventil2: type=uint8
    IF_BMS_Strom
      data DE_BMS_Strom: type=uint16
    IF_BMS_Temperatur
      data DE_BMS_Temperatur: type=uint8
    IF_BMS_Temperierung_Anf
      data DE_BMS_Temperierung_Anf: type=uint8
    IF_BMS_TMA_Betriebsart
      data DE_BMS_TMA_Betriebsart: type=uint8
    IF_BMS_TMA_Kuehlkreis_Status
      data DE_BMS_TMA_Kuehlkreis_Status: type=uint8
    IF_BMS_UBE_T
      data DE_BMS_UBE_T: type=uint16
    IF_BMS_VorlaufTemperatur
      data DE_BMS_VorlaufTemperatur: type=uint8
    IF_BT_FH_Oeffnung
      data DE_BT_FH_Oeffnung: type=uint8
    IF_BT_FH_Oeffnung_4Bit
      data DE_BT_FH_Oeffnung_4Bit: type=uint8
    IF_BT_Tuer_geoeffnet
      data DE_BT_Tuer_geoeffnet: type=boolean
    IF_CHA_Fahrer_Umschaltung
      data DE_CHA_Fahrer_Umschaltung: type=boolean
    IF_CHA_Ziel_FahrPr_KL
      data DE_CHA_Ziel_FahrPr_KL: type=uint8
    IF_DGN_Verlernzaehler
      data DE_DGN_Verlernzaehler: type=uint8
    IF_DI_KL_58xd
      data DE_DI_KL_58xd: type=uint8
    IF_DI_KL_58xs
      data DE_DI_KL_58xs: type=uint8
    IF_DiETa_Defrost_Taste
      data DE_DiETa_Defrost_Taste: type=uint8
    IF_DiETa_FSH_Taste
      data DE_DiETa_FSH_Taste: type=uint8
    IF_DiETa_HSH_Taste
      data DE_DiETa_HSH_Taste: type=uint8
    IF_DiETa_Klima
      data DE_DiETa_Klima: type=uint8
    IF_DS_BitError
      data DE_DS_BitError: type=boolean
    IF_DS_ChecksumError
      data DE_DS_ChecksumError: type=boolean
    IF_DS_DruckError
      data DE_DS_DruckError: type=boolean
    IF_DS_HW
      data DE_DS_HW: type=uint8
    IF_DS_Kaeltemittel_P
      data DE_DS_Kaeltemittel_P: type=uint16
    IF_DS_Kaeltemittel_P_WP
      data DE_DS_Kaeltemittel_P_WP: type=uint16
    IF_DS_Status
      data DE_DS_Status: type=uint8
    IF_DS_SW
      data DE_DS_SW: type=uint8
    IF_DS_TempError
      data DE_DS_TempError: type=boolean
    IF_DTS1_Fehler
      data DE_DTS1_Fehler: type=boolean
    IF_DTS1_interne_Sensor_T
      data DE_DTS1_interne_Sensor_T: type=uint16
    IF_DTS1_Kaeltemittel_p
      data DE_DTS1_Kaeltemittel_p: type=uint16
    IF_DTS1_Kaeltemittel_T
      data DE_DTS1_Kaeltemittel_T: type=uint16
    IF_DTS1_Kommunikation
      data DE_DTS1_Kommunikation: type=boolean
    IF_DTS1_R744_Fehler
      data DE_DTS1_R744_Fehler: type=boolean
    IF_DTS1_R744_interne_Sensor_T
      data DE_DTS1_R744_interne_Sensor_T: type=uint16
    IF_DTS1_R744_Kaeltemittel_p
      data DE_DTS1_R744_Kaeltemittel_p: type=uint16
    IF_DTS1_R744_Kaeltemittel_t
      data DE_DTS1_R744_Kaeltemittel_t: type=uint16
    IF_DTS1_R744_Kommunikation
      data DE_DTS1_R744_Kommunikation: type=boolean
    IF_DTS1_R744_ResponseError
      data DE_DTS1_R744_ResponseError: type=boolean
    IF_DTS1_R744_TNCTOC
      data DE_DTS1_R744_TNCTOC: type=boolean
    IF_DTS1_ResponseError
      data DE_DTS1_ResponseError: type=boolean
    IF_DTS1_TNCTOC
      data DE_DTS1_TNCTOC: type=boolean
    IF_DTS2_Fehler
      data DE_DTS2_Fehler: type=boolean
    IF_DTS2_interne_Sensor_T
      data DE_DTS2_interne_Sensor_T: type=uint16
    IF_DTS2_Kaeltemittel_p
      data DE_DTS2_Kaeltemittel_p: type=uint16
    IF_DTS2_Kaeltemittel_T
      data DE_DTS2_Kaeltemittel_T: type=uint16
    IF_DTS2_Kommunikation
      data DE_DTS2_Kommunikation: type=boolean
    IF_DTS2_R744_Fehler
      data DE_DTS2_R744_Fehler: type=boolean
    IF_DTS2_R744_interne_Sensor_T
      data DE_DTS2_R744_interne_Sensor_T: type=uint16
    IF_DTS2_R744_Kaeltemittel_p
      data DE_DTS2_R744_Kaeltemittel_p: type=uint16
    IF_DTS2_R744_Kaeltemittel_t
      data DE_DTS2_R744_Kaeltemittel_t: type=uint16
    IF_DTS2_R744_Kommunikation
      data DE_DTS2_R744_Kommunikation: type=boolean
    IF_DTS2_R744_ResponseError
      data DE_DTS2_R744_ResponseError: type=boolean
    IF_DTS2_R744_TNCTOC
      data DE_DTS2_R744_TNCTOC: type=boolean
    IF_DTS2_ResponseError
      data DE_DTS2_ResponseError: type=boolean
    IF_DTS2_TNCTOC
      data DE_DTS2_TNCTOC: type=boolean
    IF_DTS2b_R744_Fehler
      data DE_DTS2b_R744_Fehler: type=boolean
    IF_DTS2b_R744_interne_Sensor_T
      data DE_DTS2b_R744_interne_Sensor_T: type=uint16
    IF_DTS2b_R744_Kaeltemittel_p
      data DE_DTS2b_R744_Kaeltemittel_p: type=uint16
    IF_DTS2b_R744_Kaeltemittel_t
      data DE_DTS2b_R744_Kaeltemittel_t: type=uint16
    IF_DTS2b_R744_Kommunikation
      data DE_DTS2b_R744_Kommunikation: type=boolean
    IF_DTS2b_R744_ResponseError
      data DE_DTS2b_R744_ResponseError: type=boolean
    IF_DTS2b_R744_TNCTOC
      data DE_DTS2b_R744_TNCTOC: type=boolean
    IF_DTS2c_R744_Fehler
      data DE_DTS2c_R744_Fehler: type=boolean
    IF_DTS2c_R744_interne_Sensor_T
      data DE_DTS2c_R744_interne_Sensor_T: type=uint16
    IF_DTS2c_R744_Kaeltemittel_p
      data DE_DTS2c_R744_Kaeltemittel_p: type=uint16
    IF_DTS2c_R744_Kaeltemittel_t
      data DE_DTS2c_R744_Kaeltemittel_t: type=uint16
    IF_DTS2c_R744_Kommunikation
      data DE_DTS2c_R744_Kommunikation: type=boolean
    IF_DTS2c_R744_ResponseError
      data DE_DTS2c_R744_ResponseError: type=boolean
    IF_DTS2c_R744_TNCTOC
      data DE_DTS2c_R744_TNCTOC: type=boolean
    IF_DTS3_Fehler
      data DE_DTS3_Fehler: type=boolean
    IF_DTS3_interne_Sensor_T
      data DE_DTS3_interne_Sensor_T: type=uint16
    IF_DTS3_Kaeltemittel_p
      data DE_DTS3_Kaeltemittel_p: type=uint16
    IF_DTS3_Kaeltemittel_T
      data DE_DTS3_Kaeltemittel_T: type=uint16
    IF_DTS3_Kommunikation
      data DE_DTS3_Kommunikation: type=boolean
    IF_DTS3_R744_Fehler
      data DE_DTS3_R744_Fehler: type=boolean
    IF_DTS3_R744_interne_Sensor_T
      data DE_DTS3_R744_interne_Sensor_T: type=uint16
    IF_DTS3_R744_Kaeltemittel_p
      data DE_DTS3_R744_Kaeltemittel_p: type=uint16
    IF_DTS3_R744_Kaeltemittel_t
      data DE_DTS3_R744_Kaeltemittel_t: type=uint16
    IF_DTS3_R744_Kommunikation
      data DE_DTS3_R744_Kommunikation: type=boolean
    IF_DTS3_R744_ResponseError
      data DE_DTS3_R744_ResponseError: type=boolean
    IF_DTS3_R744_TNCTOC
      data DE_DTS3_R744_TNCTOC: type=boolean
    IF_DTS3_ResponseError
      data DE_DTS3_ResponseError: type=boolean
    IF_DTS3_TNCTOC
      data DE_DTS3_TNCTOC: type=boolean
    IF_DTS3b_R744_Fehler
      data DE_DTS3b_R744_Fehler: type=boolean
    IF_DTS3b_R744_interne_Sensor_T
      data DE_DTS3b_R744_interne_Sensor_T: type=uint16
    IF_DTS3b_R744_Kaeltemittel_p
      data DE_DTS3b_R744_Kaeltemittel_p: type=uint16
    IF_DTS3b_R744_Kaeltemittel_t
      data DE_DTS3b_R744_Kaeltemittel_t: type=uint16
    IF_DTS3b_R744_Kommunikation
      data DE_DTS3b_R744_Kommunikation: type=boolean
    IF_DTS3b_R744_ResponseError
      data DE_DTS3b_R744_ResponseError: type=boolean
    IF_DTS3b_R744_TNCTOC
      data DE_DTS3b_R744_TNCTOC: type=boolean
    IF_EASV1_Err_Blockierung_TF
      data DE_EASV1_Err_Blockierung_TF: type=boolean
    IF_EASV1_Err_Blockierung_TNCTOC
      data DE_EASV1_Err_Blockierung_TNCTOC: type=boolean
    IF_EASV1_Err_EDefekt_MoKomp_TF
      data DE_EASV1_Err_EDefekt_MoKomp_TF: type=boolean
    IF_EASV1_Err_EDefekt_MoKomp_TNCTOC
      data DE_EASV1_Err_EDefekt_MoKomp_TNCTOC: type=boolean
    IF_EASV1_Err_EDefekt_TSens_TF
      data DE_EASV1_Err_EDefekt_TSens_TF: type=boolean
    IF_EASV1_Err_EDefekt_TSens_TNCTOC
      data DE_EASV1_Err_EDefekt_TSens_TNCTOC: type=boolean
    IF_EASV1_Err_Notlaufpos_TF
      data DE_EASV1_Err_Notlaufpos_TF: type=boolean
    IF_EASV1_Err_Notlaufpos_TNCTOC
      data DE_EASV1_Err_Notlaufpos_TNCTOC: type=boolean
    IF_EASV1_Err_RAMROMNADChange_TF
      data DE_EASV1_Err_RAMROMNADChange_TF: type=boolean
    IF_EASV1_Err_RAMROMNADChange_TNCTOC
      data DE_EASV1_Err_RAMROMNADChange_TNCTOC: type=boolean
    IF_EASV1_Err_Ueberspannung_TF
      data DE_EASV1_Err_Ueberspannung_TF: type=boolean
    IF_EASV1_Err_Ueberspannung_TNCTOC
      data DE_EASV1_Err_Ueberspannung_TNCTOC: type=boolean
    IF_EASV1_Err_Uebertemperatur_TF
      data DE_EASV1_Err_Uebertemperatur_TF: type=boolean
    IF_EASV1_Err_Uebertemperatur_TNCTOC
      data DE_EASV1_Err_Uebertemperatur_TNCTOC: type=boolean
    IF_EASV1_Err_Unterspannung_TF
      data DE_EASV1_Err_Unterspannung_TF: type=boolean
    IF_EASV1_Err_Unterspannung_TNCTOC
      data DE_EASV1_Err_Unterspannung_TNCTOC: type=boolean
    IF_EASV1_ErrMem_State
      data DE_EASV1_ErrMem_State: type=uint8
    IF_EASV1_Geschwindigkeitsstatus
      data DE_EASV1_Geschwindigkeitsstatus: type=uint8
    IF_EASV1_Ist_Position_Aktuator
      data DE_EASV1_Ist_Position_Aktuator: type=uint16
    IF_EASV1_ResponseError
      data DE_EASV1_ResponseError: type=boolean
    IF_EASV1_ResponseError_TNCTOC
      data DE_EASV1_ResponseError_TNCTOC: type=boolean
    IF_EASV1_Spulenbestromung
      data DE_EASV1_Spulenbestromung: type=uint8
    IF_EASV1_Temp
      data DE_EASV1_Temp: type=uint8
    IF_EASV1_Temp_Warning
      data DE_EASV1_Temp_Warning: type=boolean
    IF_EASV2_Err_Blockierung_TF
      data DE_EASV2_Err_Blockierung_TF: type=boolean
    IF_EASV2_Err_Blockierung_TNCTOC
      data DE_EASV2_Err_Blockierung_TNCTOC: type=boolean
    IF_EASV2_Err_EDefekt_MoKomp_TF
      data DE_EASV2_Err_EDefekt_MoKomp_TF: type=boolean
    IF_EASV2_Err_EDefekt_MoKomp_TNCTOC
      data DE_EASV2_Err_EDefekt_MoKomp_TNCTOC: type=boolean
    IF_EASV2_Err_EDefekt_TSens_TF
      data DE_EASV2_Err_EDefekt_TSens_TF: type=boolean
    IF_EASV2_Err_EDefekt_TSens_TNCTOC
      data DE_EASV2_Err_EDefekt_TSens_TNCTOC: type=boolean
    IF_EASV2_Err_Notlaufpos_TF
      data DE_EASV2_Err_Notlaufpos_TF: type=boolean
    IF_EASV2_Err_Notlaufpos_TNCTOC
      data DE_EASV2_Err_Notlaufpos_TNCTOC: type=boolean
    IF_EASV2_Err_RAMROMNADChange_TF
      data DE_EASV2_Err_RAMROMNADChange_TF: type=boolean
    IF_EASV2_Err_RAMROMNADChange_TNCTOC
      data DE_EASV2_Err_RAMROMNADChange_TNCTOC: type=boolean
    IF_EASV2_Err_Ueberspannung_TF
      data DE_EASV2_Err_Ueberspannung_TF: type=boolean
    IF_EASV2_Err_Ueberspannung_TNCTOC
      data DE_EASV2_Err_Ueberspannung_TNCTOC: type=boolean
    IF_EASV2_Err_Uebertemperatur_TF
      data DE_EASV2_Err_Uebertemperatur_TF: type=boolean
    IF_EASV2_Err_Uebertemperatur_TNCTOC
      data DE_EASV2_Err_Uebertemperatur_TNCTOC: type=boolean
    IF_EASV2_Err_Unterspannung_TF
      data DE_EASV2_Err_Unterspannung_TF: type=boolean
    IF_EASV2_Err_Unterspannung_TNCTOC
      data DE_EASV2_Err_Unterspannung_TNCTOC: type=boolean
    IF_EASV2_ErrMem_State
      data DE_EASV2_ErrMem_State: type=uint8
    IF_EASV2_Geschwindigkeitsstatus
      data DE_EASV2_Geschwindigkeitsstatus: type=uint8
    IF_EASV2_Ist_Position_Aktuator
      data DE_EASV2_Ist_Position_Aktuator: type=uint16
    IF_EASV2_ResponseError
      data DE_EASV2_ResponseError: type=boolean
    IF_EASV2_ResponseError_TNCTOC
      data DE_EASV2_ResponseError_TNCTOC: type=boolean
    IF_EASV2_Spulenbestromung
      data DE_EASV2_Spulenbestromung: type=uint8
    IF_EASV2_Temp
      data DE_EASV2_Temp: type=uint8
    IF_EASV2_Temp_Warning
      data DE_EASV2_Temp_Warning: type=boolean
    IF_EASV3_Err_Blockierung_TF
      data DE_EASV3_Err_Blockierung_TF: type=boolean
    IF_EASV3_Err_Blockierung_TNCTOC
      data DE_EASV3_Err_Blockierung_TNCTOC: type=boolean
    IF_EASV3_Err_EDefekt_MoKomp_TF
      data DE_EASV3_Err_EDefekt_MoKomp_TF: type=boolean
    IF_EASV3_Err_EDefekt_MoKomp_TNCTOC
      data DE_EASV3_Err_EDefekt_MoKomp_TNCTOC: type=boolean
    IF_EASV3_Err_EDefekt_TSens_TF
      data DE_EASV3_Err_EDefekt_TSens_TF: type=boolean
    IF_EASV3_Err_EDefekt_TSens_TNCTOC
      data DE_EASV3_Err_EDefekt_TSens_TNCTOC: type=boolean
    IF_EASV3_Err_Notlaufpos_TF
      data DE_EASV3_Err_Notlaufpos_TF: type=boolean
    IF_EASV3_Err_Notlaufpos_TNCTOC
      data DE_EASV3_Err_Notlaufpos_TNCTOC: type=boolean
    IF_EASV3_Err_RAMROMNADChange_TF
      data DE_EASV3_Err_RAMROMNADChange_TF: type=boolean
    IF_EASV3_Err_RAMROMNADChange_TNCTOC
      data DE_EASV3_Err_RAMROMNADChange_TNCTOC: type=boolean
    IF_EASV3_Err_Ueberspannung_TF
      data DE_EASV3_Err_Ueberspannung_TF: type=boolean
    IF_EASV3_Err_Ueberspannung_TNCTOC
      data DE_EASV3_Err_Ueberspannung_TNCTOC: type=boolean
    IF_EASV3_Err_Uebertemperatur_TF
      data DE_EASV3_Err_Uebertemperatur_TF: type=boolean
    IF_EASV3_Err_Uebertemperatur_TNCTOC
      data DE_EASV3_Err_Uebertemperatur_TNCTOC: type=boolean
    IF_EASV3_Err_Unterspannung_TF
      data DE_EASV3_Err_Unterspannung_TF: type=boolean
    IF_EASV3_Err_Unterspannung_TNCTOC
      data DE_EASV3_Err_Unterspannung_TNCTOC: type=boolean
    IF_EASV3_ErrMem_State
      data DE_EASV3_ErrMem_State: type=uint8
    IF_EASV3_Geschwindigkeitsstatus
      data DE_EASV3_Geschwindigkeitsstatus: type=uint8
    IF_EASV3_Ist_Position_Aktuator
      data DE_EASV3_Ist_Position_Aktuator: type=uint16
    IF_EASV3_ResponseError
      data DE_EASV3_ResponseError: type=boolean
    IF_EASV3_ResponseError_TNCTOC
      data DE_EASV3_ResponseError_TNCTOC: type=boolean
    IF_EASV3_Spulenbestromung
      data DE_EASV3_Spulenbestromung: type=uint8
    IF_EASV3_Temp
      data DE_EASV3_Temp: type=uint8
    IF_EASV3_Temp_Warning
      data DE_EASV3_Temp_Warning: type=boolean
    IF_EASV4_Err_Blockierung_TF
      data DE_EASV4_Err_Blockierung_TF: type=boolean
    IF_EASV4_Err_Blockierung_TNCTOC
      data DE_EASV4_Err_Blockierung_TNCTOC: type=boolean
    IF_EASV4_Err_EDefekt_MoKomp_TF
      data DE_EASV4_Err_EDefekt_MoKomp_TF: type=boolean
    IF_EASV4_Err_EDefekt_MoKomp_TNCTOC
      data DE_EASV4_Err_EDefekt_MoKomp_TNCTOC: type=boolean
    IF_EASV4_Err_EDefekt_TSens_TF
      data DE_EASV4_Err_EDefekt_TSens_TF: type=boolean
    IF_EASV4_Err_EDefekt_TSens_TNCTOC
      data DE_EASV4_Err_EDefekt_TSens_TNCTOC: type=boolean
    IF_EASV4_Err_Notlaufpos_TF
      data DE_EASV4_Err_Notlaufpos_TF: type=boolean
    IF_EASV4_Err_Notlaufpos_TNCTOC
      data DE_EASV4_Err_Notlaufpos_TNCTOC: type=boolean
    IF_EASV4_Err_RAMROMNADChange_TF
      data DE_EASV4_Err_RAMROMNADChange_TF: type=boolean
    IF_EASV4_Err_RAMROMNADChange_TNCTOC
      data DE_EASV4_Err_RAMROMNADChange_TNCTOC: type=boolean
    IF_EASV4_Err_Ueberspannung_TF
      data DE_EASV4_Err_Ueberspannung_TF: type=boolean
    IF_EASV4_Err_Ueberspannung_TNCTOC
      data DE_EASV4_Err_Ueberspannung_TNCTOC: type=boolean
    IF_EASV4_Err_Uebertemperatur_TF
      data DE_EASV4_Err_Uebertemperatur_TF: type=boolean
    IF_EASV4_Err_Uebertemperatur_TNCTOC
      data DE_EASV4_Err_Uebertemperatur_TNCTOC: type=boolean
    IF_EASV4_Err_Unterspannung_TF
      data DE_EASV4_Err_Unterspannung_TF: type=boolean
    IF_EASV4_Err_Unterspannung_TNCTOC
      data DE_EASV4_Err_Unterspannung_TNCTOC: type=boolean
    IF_EASV4_ErrMem_State
      data DE_EASV4_ErrMem_State: type=uint8
    IF_EASV4_Geschwindigkeitsstatus
      data DE_EASV4_Geschwindigkeitsstatus: type=uint8
    IF_EASV4_Ist_Position_Aktuator
      data DE_EASV4_Ist_Position_Aktuator: type=uint16
    IF_EASV4_ResponseError
      data DE_EASV4_ResponseError: type=boolean
    IF_EASV4_ResponseError_TNCTOC
      data DE_EASV4_ResponseError_TNCTOC: type=boolean
    IF_EASV4_Spulenbestromung
      data DE_EASV4_Spulenbestromung: type=uint8
    IF_EASV4_Temp
      data DE_EASV4_Temp: type=uint8
    IF_EASV4_Temp_Warning
      data DE_EASV4_Temp_Warning: type=boolean
    IF_EASV5_Err_Blockierung_TF
      data DE_EASV5_Err_Blockierung_TF: type=boolean
    IF_EASV5_Err_Blockierung_TNCTOC
      data DE_EASV5_Err_Blockierung_TNCTOC: type=boolean
    IF_EASV5_Err_EDefekt_MoKomp_TF
      data DE_EASV5_Err_EDefekt_MoKomp_TF: type=boolean
    IF_EASV5_Err_EDefekt_MoKomp_TNCTOC
      data DE_EASV5_Err_EDefekt_MoKomp_TNCTOC: type=boolean
    IF_EASV5_Err_EDefekt_TSens_TF
      data DE_EASV5_Err_EDefekt_TSens_TF: type=boolean
    IF_EASV5_Err_EDefekt_TSens_TNCTOC
      data DE_EASV5_Err_EDefekt_TSens_TNCTOC: type=boolean
    IF_EASV5_Err_Notlaufpos_TF
      data DE_EASV5_Err_Notlaufpos_TF: type=boolean
    IF_EASV5_Err_Notlaufpos_TNCTOC
      data DE_EASV5_Err_Notlaufpos_TNCTOC: type=boolean
    IF_EASV5_Err_RAMROMNADChange_TF
      data DE_EASV5_Err_RAMROMNADChange_TF: type=boolean
    IF_EASV5_Err_RAMROMNADChange_TNCTOC
      data DE_EASV5_Err_RAMROMNADChange_TNCTOC: type=boolean
    IF_EASV5_Err_Ueberspannung_TF
      data DE_EASV5_Err_Ueberspannung_TF: type=boolean
    IF_EASV5_Err_Ueberspannung_TNCTOC
      data DE_EASV5_Err_Ueberspannung_TNCTOC: type=boolean
    IF_EASV5_Err_Uebertemperatur_TF
      data DE_EASV5_Err_Uebertemperatur_TF: type=boolean
    IF_EASV5_Err_Uebertemperatur_TNCTOC
      data DE_EASV5_Err_Uebertemperatur_TNCTOC: type=boolean
    IF_EASV5_Err_Unterspannung_TF
      data DE_EASV5_Err_Unterspannung_TF: type=boolean
    IF_EASV5_Err_Unterspannung_TNCTOC
      data DE_EASV5_Err_Unterspannung_TNCTOC: type=boolean
    IF_EASV5_ErrMem_State
      data DE_EASV5_ErrMem_State: type=uint8
    IF_EASV5_Geschwindigkeitsstatus
      data DE_EASV5_Geschwindigkeitsstatus: type=uint8
    IF_EASV5_Ist_Position_Aktuator
      data DE_EASV5_Ist_Position_Aktuator: type=uint16
    IF_EASV5_ResponseError
      data DE_EASV5_ResponseError: type=boolean
    IF_EASV5_ResponseError_TNCTOC
      data DE_EASV5_ResponseError_TNCTOC: type=boolean
    IF_EASV5_Spulenbestromung
      data DE_EASV5_Spulenbestromung: type=uint8
    IF_EASV5_temp
      data DE_EASV5_temp: type=uint8
    IF_EASV5_Temp_Warning
      data DE_EASV5_Temp_Warning: type=boolean
    IF_eCall_Funktionsstatus_02
      data DE_eCall_Funktionsstatus_02: type=uint8
    IF_EKK4_Comp_Error_Mask_Nr
      data DE_EKK4_Comp_Error_Mask_Nr: type=uint8
    IF_EKK4_COMP_SPEED
      data DE_EKK4_COMP_SPEED: type=uint16
    IF_EKK4_COMP_ST
      data DE_EKK4_COMP_ST: type=uint8
    IF_EKK4_Err_Ind_Nr_1_8_15_22
      data DE_EKK4_Err_Ind_Nr_1_8_15_22: type=uint8
    IF_EKK4_Err_Ind_Nr_2_9_16_23
      data DE_EKK4_Err_Ind_Nr_2_9_16_23: type=uint8
    IF_EKK4_Err_Ind_Nr_3_10_17_24
      data DE_EKK4_Err_Ind_Nr_3_10_17_24: type=uint8
    IF_EKK4_Err_Ind_Nr_4_11_18_25
      data DE_EKK4_Err_Ind_Nr_4_11_18_25: type=uint8
    IF_EKK4_Err_Ind_Nr_5_12_19_26
      data DE_EKK4_Err_Ind_Nr_5_12_19_26: type=uint8
    IF_EKK4_Err_Ind_Nr_6_13_20_27
      data DE_EKK4_Err_Ind_Nr_6_13_20_27: type=uint8
    IF_EKK4_Err_Ind_Nr_7_14_21_28
      data DE_EKK4_Err_Ind_Nr_7_14_21_28: type=uint8
    IF_EKK4_Err_Ind_TF_1_7
      data DE_EKK4_Err_Ind_TF_1_7: type=uint8
    IF_EKK4_Err_Ind_TF_2_8
      data DE_EKK4_Err_Ind_TF_2_8: type=uint8
    IF_EKK4_Err_Ind_TF_3_9
      data DE_EKK4_Err_Ind_TF_3_9: type=uint8
    IF_EKK4_Err_Ind_TF_4_10
      data DE_EKK4_Err_Ind_TF_4_10: type=uint8
    IF_EKK4_Err_Ind_TF_5_11
      data DE_EKK4_Err_Ind_TF_5_11: type=uint8
    IF_EKK4_Err_Ind_TF_6_12
      data DE_EKK4_Err_Ind_TF_6_12: type=uint8
    IF_EKK4_ErrMem_State
      data DE_EKK4_ErrMem_State: type=uint8
    IF_EKK4_Fehler_AE
      data DE_EKK4_Fehler_AE: type=uint8
    IF_EKK4_HIGH_VOLTAGE
      data DE_EKK4_HIGH_VOLTAGE: type=uint16
    IF_EKK4_INPUT_CURRENT
      data DE_EKK4_INPUT_CURRENT: type=uint8
    IF_EKK4_INV_TEMP
      data DE_EKK4_INV_TEMP: type=uint8
    IF_EKK4_Level_Rsp
      data DE_EKK4_Level_Rsp: type=boolean
    IF_EKK4_Match
      data DE_EKK4_Match: type=uint8
    IF_EKK4_MUX_Err_Ind
      data DE_EKK4_MUX_Err_Ind: type=uint8
    IF_EKK4_Number_of_Err_Ind_TF
      data DE_EKK4_Number_of_Err_Ind_TF: type=uint8
    IF_EKK4_ParameterChange
      data DE_EKK4_ParameterChange: type=boolean
    IF_EKK4_Q_High_Voltage
      data DE_EKK4_Q_High_Voltage: type=boolean
    IF_EKK4_Reason_Err_Ind_TF_1_7
      data DE_EKK4_Reason_Err_Ind_TF_1_7: type=uint8
    IF_EKK4_Reason_Err_Ind_TF_2_8
      data DE_EKK4_Reason_Err_Ind_TF_2_8: type=uint8
    IF_EKK4_Reason_Err_Ind_TF_3_9
      data DE_EKK4_Reason_Err_Ind_TF_3_9: type=uint8
    IF_EKK4_Reason_Err_Ind_TF_4_10
      data DE_EKK4_Reason_Err_Ind_TF_4_10: type=uint8
    IF_EKK4_Reason_Err_Ind_TF_5_11
      data DE_EKK4_Reason_Err_Ind_TF_5_11: type=uint8
    IF_EKK4_Reason_Err_Ind_TF_6_12
      data DE_EKK4_Reason_Err_Ind_TF_6_12: type=uint8
    IF_EKK4_ResponseError
      data DE_EKK4_ResponseError: type=boolean
    IF_EKK4_TF_Change
      data DE_EKK4_TF_Change: type=boolean
    IF_EKK_Active_Discharge
      data DE_EKK_Active_Discharge: type=uint8
    IF_EKK_ENB_COMP
      data DE_EKK_ENB_COMP: type=uint8
    IF_EKK_HV_ST
      data DE_EKK_HV_ST: type=uint8
    IF_EKK_KL_15_Status
      data DE_EKK_KL_15_Status: type=uint8
    IF_EKK_REQ_COMP_SPEED
      data DE_EKK_REQ_COMP_SPEED: type=uint8
    IF_EKK_REQ_COMP_SPEED_HiRes
      data DE_EKK_REQ_COMP_SPEED_HiRes: type=uint16
    IF_EKKe_Error_Mask_Nr
      data DE_EKKe_Error_Mask_Nr: type=uint8
    IF_EKKe_Level_REQ
      data DE_EKKe_Level_REQ: type=boolean
    IF_EKKe_Q_Mask
      data DE_EKKe_Q_Mask: type=boolean
    IF_EM1_MinVorlauftemperatur
      data DE_EM1_MinVorlauftemperatur: type=uint8
    IF_Empfindlichkeit_AQS
      data DE_Empfindlichkeit_AQS: type=uint8
    IF_ESC_Anf_KV
      data DE_ESC_Anf_KV: type=boolean
    IF_ESC_Anf_Mindestreku
      data DE_ESC_Anf_Mindestreku: type=boolean
    IF_ESP_QBit_v_Signal
      data DE_ESP_QBit_v_Signal: type=boolean
    IF_ESP_v_Signal
      data DE_ESP_v_Signal: type=uint16
    IF_ESP_v_Signal_8Bit
      data DE_ESP_v_Signal_8Bit: type=uint8
    IF_eTM_Batterieheizen_Anf
      data DE_eTM_Batterieheizen_Anf: type=uint8
    IF_eTM_BMS_Pumpe1_Befuellung
      data DE_eTM_BMS_Pumpe1_Befuellung: type=boolean
    IF_eTM_BMS_Pumpe1_SollAnsteuerung
      data DE_eTM_BMS_Pumpe1_SollAnsteuerung: type=uint8
    IF_eTM_BMS_ThermischeIstLeistung
      data DE_eTM_BMS_ThermischeIstLeistung: type=uint16
    IF_eTM_BMS_Ventil1_Befuellung
      data DE_eTM_BMS_Ventil1_Befuellung: type=boolean
    IF_eTM_BMS_Ventil2_Befuellung
      data DE_eTM_BMS_Ventil2_Befuellung: type=boolean
    IF_eTM_HVBatt_IstVolumenstrom
      data DE_eTM_HVBatt_IstVolumenstrom: type=uint16
    IF_eTM_HWT_IstVolumenstrom
      data DE_eTM_HWT_IstVolumenstrom: type=uint8
    IF_eTM_Ist_rLM
      data DE_eTM_Ist_rLM: type=uint8
    IF_eTM_Kuehlung_Status
      data DE_eTM_Kuehlung_Status: type=uint32
    IF_eTM_Pumpe1_Status
      data DE_eTM_Pumpe1_Status: type=uint8
    IF_eTM_Pumpe1_Volumenstrom
      data DE_eTM_Pumpe1_Volumenstrom: type=uint8
    IF_eTM_Pumpe2_Status
      data DE_eTM_Pumpe2_Status: type=uint8
    IF_eTM_Pumpe2_Volumenstrom
      data DE_eTM_Pumpe2_Volumenstrom: type=uint8
    IF_eTM_PumpeAntrieb_Ansteuerung
      data DE_eTM_PumpeAntrieb_Ansteuerung: type=uint8
    IF_eTM_PumpeBat_Ansteuerung
      data DE_eTM_PumpeBat_Ansteuerung: type=uint8
    IF_eTM_PumpeHWT_Ansteuerung
      data DE_eTM_PumpeHWT_Ansteuerung: type=uint8
    IF_eTM_PV1_Ansteuerung
      data DE_eTM_PV1_Ansteuerung: type=uint8
    IF_eTM_PV2_Ansteuerung
      data DE_eTM_PV2_Ansteuerung: type=uint8
    IF_eTM_PWR_MinVorlaufTemp
      data DE_eTM_PWR_MinVorlaufTemp: type=uint16
    IF_eTM_Temperatur_1
      data DE_eTM_Temperatur_1: type=uint8
    IF_eTM_Temperatur_2
      data DE_eTM_Temperatur_2: type=uint8
    IF_eTM_Ventil1_Status
      data DE_eTM_Ventil1_Status: type=uint8
    IF_eTM_Ventil2_Status
      data DE_eTM_Ventil2_Status: type=uint8
    IF_eTM_Ventil3_Status
      data DE_eTM_Ventil3_Status: type=uint8
    IF_eTM_Wasserheizer_IstVolumenstrom
      data DE_eTM_Wasserheizer_IstVolumenstrom: type=uint16
    IF_eTM_Wasserheizer_SollTemp_Ausgng
      data DE_eTM_Wasserheizer_SollTemp_Ausgng: type=uint16
    IF_EXV1_Err_Blockierung_TF
      data DE_EXV1_Err_Blockierung_TF: type=boolean
    IF_EXV1_Err_Blockierung_TNCTOC
      data DE_EXV1_Err_Blockierung_TNCTOC: type=boolean
    IF_EXV1_Err_EDefekt_MoKomp_TF
      data DE_EXV1_Err_EDefekt_MoKomp_TF: type=boolean
    IF_EXV1_Err_EDefekt_MoKomp_TNCTOC
      data DE_EXV1_Err_EDefekt_MoKomp_TNCTOC: type=boolean
    IF_EXV1_Err_EDefekt_TSens_TF
      data DE_EXV1_Err_EDefekt_TSens_TF: type=boolean
    IF_EXV1_Err_EDefekt_TSens_TNCTOC
      data DE_EXV1_Err_EDefekt_TSens_TNCTOC: type=boolean
    IF_EXV1_Err_Notlaufpos_TF
      data DE_EXV1_Err_Notlaufpos_TF: type=boolean
    IF_EXV1_Err_Notlaufpos_TNCTOC
      data DE_EXV1_Err_Notlaufpos_TNCTOC: type=boolean
    IF_EXV1_Err_RAMROMNADChange_TF
      data DE_EXV1_Err_RAMROMNADChange_TF: type=boolean
    IF_EXV1_Err_RAMROMNADChange_TNCTOC
      data DE_EXV1_Err_RAMROMNADChange_TNCTOC: type=boolean
    IF_EXV1_Err_Ueberspannung_TF
      data DE_EXV1_Err_Ueberspannung_TF: type=boolean
    IF_EXV1_Err_Ueberspannung_TNCTOC
      data DE_EXV1_Err_Ueberspannung_TNCTOC: type=boolean
    IF_EXV1_Err_Uebertemperatur_TF
      data DE_EXV1_Err_Uebertemperatur_TF: type=boolean
    IF_EXV1_Err_Uebertemperatur_TNCTOC
      data DE_EXV1_Err_Uebertemperatur_TNCTOC: type=boolean
    IF_EXV1_Err_Unterspannung_TF
      data DE_EXV1_Err_Unterspannung_TF: type=boolean
    IF_EXV1_Err_Unterspannung_TNCTOC
      data DE_EXV1_Err_Unterspannung_TNCTOC: type=boolean
    IF_EXV1_ErrMem_State
      data DE_EXV1_ErrMem_State: type=uint8
    IF_EXV1_Geschwindigkeitsstatus
      data DE_EXV1_Geschwindigkeitsstatus: type=uint8
    IF_EXV1_Ist_Position_Aktuator
      data DE_EXV1_Ist_Position_Aktuator: type=uint16
    IF_EXV1_ResponseError
      data DE_EXV1_ResponseError: type=boolean
    IF_EXV1_ResponseError_TNCTOC
      data DE_EXV1_ResponseError_TNCTOC: type=boolean
    IF_EXV1_Spulenbestromung
      data DE_EXV1_Spulenbestromung: type=uint8
    IF_EXV1_Temp
      data DE_EXV1_Temp: type=uint8
    IF_EXV1_Temp_Warning
      data DE_EXV1_Temp_Warning: type=boolean
    IF_EXV2_Err_Blockierung_TF
      data DE_EXV2_Err_Blockierung_TF: type=boolean
    IF_EXV2_Err_Blockierung_TNCTOC
      data DE_EXV2_Err_Blockierung_TNCTOC: type=boolean
    IF_EXV2_Err_EDefekt_MoKomp_TF
      data DE_EXV2_Err_EDefekt_MoKomp_TF: type=boolean
    IF_EXV2_Err_EDefekt_MoKomp_TNCTOC
      data DE_EXV2_Err_EDefekt_MoKomp_TNCTOC: type=boolean
    IF_EXV2_Err_EDefekt_TSens_TF
      data DE_EXV2_Err_EDefekt_TSens_TF: type=boolean
    IF_EXV2_Err_EDefekt_TSens_TNCTOC
      data DE_EXV2_Err_EDefekt_TSens_TNCTOC: type=boolean
    IF_EXV2_Err_Notlaufpos_TF
      data DE_EXV2_Err_Notlaufpos_TF: type=boolean
    IF_EXV2_Err_Notlaufpos_TNCTOC
      data DE_EXV2_Err_Notlaufpos_TNCTOC: type=boolean
    IF_EXV2_Err_RAMROMNADChange_TF
      data DE_EXV2_Err_RAMROMNADChange_TF: type=boolean
    IF_EXV2_Err_RAMROMNADChange_TNCTOC
      data DE_EXV2_Err_RAMROMNADChange_TNCTOC: type=boolean
    IF_EXV2_Err_Ueberspannung_TF
      data DE_EXV2_Err_Ueberspannung_TF: type=boolean
    IF_EXV2_Err_Ueberspannung_TNCTOC
      data DE_EXV2_Err_Ueberspannung_TNCTOC: type=boolean
    IF_EXV2_Err_Uebertemperatur_TF
      data DE_EXV2_Err_Uebertemperatur_TF: type=boolean
    IF_EXV2_Err_Uebertemperatur_TNCTOC
      data DE_EXV2_Err_Uebertemperatur_TNCTOC: type=boolean
    IF_EXV2_Err_Unterspannung_TF
      data DE_EXV2_Err_Unterspannung_TF: type=boolean
    IF_EXV2_Err_Unterspannung_TNCTOC
      data DE_EXV2_Err_Unterspannung_TNCTOC: type=boolean
    IF_EXV2_ErrMem_State
      data DE_EXV2_ErrMem_State: type=uint8
    IF_EXV2_Geschwindigkeitsstatus
      data DE_EXV2_Geschwindigkeitsstatus: type=uint8
    IF_EXV2_Ist_Position_Aktuator
      data DE_EXV2_Ist_Position_Aktuator: type=uint16
    IF_EXV2_ResponseError
      data DE_EXV2_ResponseError: type=boolean
    IF_EXV2_ResponseError_TNCTOC
      data DE_EXV2_ResponseError_TNCTOC: type=boolean
    IF_EXV2_Spulenbestromung
      data DE_EXV2_Spulenbestromung: type=uint8
    IF_EXV2_Temp
      data DE_EXV2_Temp: type=uint8
    IF_EXV2_Temp_Warning
      data DE_EXV2_Temp_Warning: type=boolean
    IF_EXV3_Err_Blockierung_TF
      data DE_EXV3_Err_Blockierung_TF: type=boolean
    IF_EXV3_Err_Blockierung_TNCTOC
      data DE_EXV3_Err_Blockierung_TNCTOC: type=boolean
    IF_EXV3_Err_EDefekt_MoKomp_TF
      data DE_EXV3_Err_EDefekt_MoKomp_TF: type=boolean
    IF_EXV3_Err_EDefekt_MoKomp_TNCTOC
      data DE_EXV3_Err_EDefekt_MoKomp_TNCTOC: type=boolean
    IF_EXV3_Err_EDefekt_TSens_TF
      data DE_EXV3_Err_EDefekt_TSens_TF: type=boolean
    IF_EXV3_Err_EDefekt_TSens_TNCTOC
      data DE_EXV3_Err_EDefekt_TSens_TNCTOC: type=boolean
    IF_EXV3_Err_Notlaufpos_TF
      data DE_EXV3_Err_Notlaufpos_TF: type=boolean
    IF_EXV3_Err_Notlaufpos_TNCTOC
      data DE_EXV3_Err_Notlaufpos_TNCTOC: type=boolean
    IF_EXV3_Err_RAMROMNADChange_TF
      data DE_EXV3_Err_RAMROMNADChange_TF: type=boolean
    IF_EXV3_Err_RAMROMNADChange_TNCTOC
      data DE_EXV3_Err_RAMROMNADChange_TNCTOC: type=boolean
    IF_EXV3_Err_Ueberspannung_TF
      data DE_EXV3_Err_Ueberspannung_TF: type=boolean
    IF_EXV3_Err_Ueberspannung_TNCTOC
      data DE_EXV3_Err_Ueberspannung_TNCTOC: type=boolean
    IF_EXV3_Err_Uebertemperatur_TF
      data DE_EXV3_Err_Uebertemperatur_TF: type=boolean
    IF_EXV3_Err_Uebertemperatur_TNCTOC
      data DE_EXV3_Err_Uebertemperatur_TNCTOC: type=boolean
    IF_EXV3_Err_Unterspannung_TF
      data DE_EXV3_Err_Unterspannung_TF: type=boolean
    IF_EXV3_Err_Unterspannung_TNCTOC
      data DE_EXV3_Err_Unterspannung_TNCTOC: type=boolean
    IF_EXV3_ErrMem_State
      data DE_EXV3_ErrMem_State: type=uint8
    IF_EXV3_Geschwindigkeitsstatus
      data DE_EXV3_Geschwindigkeitsstatus: type=uint8
    IF_EXV3_Ist_Position_Aktuator
      data DE_EXV3_Ist_Position_Aktuator: type=uint16
    IF_EXV3_ResponseError
      data DE_EXV3_ResponseError: type=boolean
    IF_EXV3_ResponseError_TNCTOC
      data DE_EXV3_ResponseError_TNCTOC: type=boolean
    IF_EXV3_Spulenbestromung
      data DE_EXV3_Spulenbestromung: type=uint8
    IF_EXV3_Temp
      data DE_EXV3_Temp: type=uint8
    IF_EXV3_Temp_Warning
      data DE_EXV3_Temp_Warning: type=boolean
    IF_EXV4_Err_Blockierung_TF
      data DE_EXV4_Err_Blockierung_TF: type=boolean
    IF_EXV4_Err_Blockierung_TNCTOC
      data DE_EXV4_Err_Blockierung_TNCTOC: type=boolean
    IF_EXV4_Err_EDefekt_MoKomp_TF
      data DE_EXV4_Err_EDefekt_MoKomp_TF: type=boolean
    IF_EXV4_Err_EDefekt_MoKomp_TNCTOC
      data DE_EXV4_Err_EDefekt_MoKomp_TNCTOC: type=boolean
    IF_EXV4_Err_EDefekt_TSens_TF
      data DE_EXV4_Err_EDefekt_TSens_TF: type=boolean
    IF_EXV4_Err_EDefekt_TSens_TNCTOC
      data DE_EXV4_Err_EDefekt_TSens_TNCTOC: type=boolean
    IF_EXV4_Err_Notlaufpos_TF
      data DE_EXV4_Err_Notlaufpos_TF: type=boolean
    IF_EXV4_Err_Notlaufpos_TNCTOC
      data DE_EXV4_Err_Notlaufpos_TNCTOC: type=boolean
    IF_EXV4_Err_RAMROMNADChange_TF
      data DE_EXV4_Err_RAMROMNADChange_TF: type=boolean
    IF_EXV4_Err_RAMROMNADChange_TNCTOC
      data DE_EXV4_Err_RAMROMNADChange_TNCTOC: type=boolean
    IF_EXV4_Err_Ueberspannung_TF
      data DE_EXV4_Err_Ueberspannung_TF: type=boolean
    IF_EXV4_Err_Ueberspannung_TNCTOC
      data DE_EXV4_Err_Ueberspannung_TNCTOC: type=boolean
    IF_EXV4_Err_Uebertemperatur_TF
      data DE_EXV4_Err_Uebertemperatur_TF: type=boolean
    IF_EXV4_Err_Uebertemperatur_TNCTOC
      data DE_EXV4_Err_Uebertemperatur_TNCTOC: type=boolean
    IF_EXV4_Err_Unterspannung_TF
      data DE_EXV4_Err_Unterspannung_TF: type=boolean
    IF_EXV4_Err_Unterspannung_TNCTOC
      data DE_EXV4_Err_Unterspannung_TNCTOC: type=boolean
    IF_EXV4_ErrMem_State
      data DE_EXV4_ErrMem_State: type=uint8
    IF_EXV4_Geschwindigkeitsstatus
      data DE_EXV4_Geschwindigkeitsstatus: type=uint8
    IF_EXV4_Ist_Position_Aktuator
      data DE_EXV4_Ist_Position_Aktuator: type=uint16
    IF_EXV4_ResponseError
      data DE_EXV4_ResponseError: type=boolean
    IF_EXV4_ResponseError_TNCTOC
      data DE_EXV4_ResponseError_TNCTOC: type=boolean
    IF_EXV4_Spulenbestromung
      data DE_EXV4_Spulenbestromung: type=uint8
    IF_EXV4_Temp
      data DE_EXV4_Temp: type=uint8
    IF_EXV4_Temp_Warning
      data DE_EXV4_Temp_Warning: type=boolean
    IF_FCM_01_alt
      data DE_FCM_01_alt: type=boolean
    IF_FoD_Transmission_Info
      data DE_FoD_Transmission_Info: type=uint8
    IF_FRS_active_container
      data DE_FRS_active_container: type=uint8
    IF_FRS_ChannelSelect
      data DE_FRS_ChannelSelect: type=uint8
    IF_FRS_CurrentIntensity
      data DE_FRS_CurrentIntensity: type=uint8
    IF_FRS_Expiry_Container_1
      data DE_FRS_Expiry_Container_1: type=boolean
    IF_FRS_Expiry_Container_2
      data DE_FRS_Expiry_Container_2: type=boolean
    IF_FRS_Expiry_Container_3
      data DE_FRS_Expiry_Container_3: type=boolean
    IF_FRS_Fan_status
      data DE_FRS_Fan_status: type=boolean
    IF_FRS_FragranceID_Container_1
      data DE_FRS_FragranceID_Container_1: type=uint8
    IF_FRS_FragranceID_Container_2
      data DE_FRS_FragranceID_Container_2: type=uint8
    IF_FRS_FragranceID_Container_3
      data DE_FRS_FragranceID_Container_3: type=uint8
    IF_FRS_IntensityReq
      data DE_FRS_IntensityReq: type=uint8
    IF_FRS_Level_Container_1
      data DE_FRS_Level_Container_1: type=uint8
    IF_FRS_Level_Container_2
      data DE_FRS_Level_Container_2: type=uint8
    IF_FRS_Level_Container_3
      data DE_FRS_Level_Container_3: type=uint8
    IF_FRS_ResponseError
      data DE_FRS_ResponseError: type=boolean
    IF_FRS_Status
      data DE_FRS_Status: type=boolean
    IF_FRS_Status_Car
      data DE_FRS_Status_Car: type=uint8
    IF_FRS_Status_UBatt
      data DE_FRS_Status_UBatt: type=uint8
    IF_FRS_Stepper_Status
      data DE_FRS_Stepper_Status: type=boolean
    IF_FS_Luftfeuchte_rel
      data DE_FS_Luftfeuchte_rel: type=uint8
    IF_FS_ResponseError
      data DE_FS_ResponseError: type=boolean
    IF_FS_Taupunkt
      data DE_FS_Taupunkt: type=uint16
    IF_FS_Temp_Scheibe
      data DE_FS_Temp_Scheibe: type=uint16
    IF_FS_Temp_Sensor
      data DE_FS_Temp_Sensor: type=uint8
    IF_FSA_HW
      data DE_FSA_HW: type=uint8
    IF_FSA_Luftfeuchte_rel
      data DE_FSA_Luftfeuchte_rel: type=uint8
    IF_FSA_ResponseError
      data DE_FSA_ResponseError: type=boolean
    IF_FSA_Sensorheizung_Status
      data DE_FSA_Sensorheizung_Status: type=boolean
    IF_FSA_SW
      data DE_FSA_SW: type=uint8
    IF_FSA_Taupunkt
      data DE_FSA_Taupunkt: type=uint16
    IF_FSA_Taupunkt_PMS
      data DE_FSA_Taupunkt_PMS: type=uint16
    IF_FSA_Temp_Luft
      data DE_FSA_Temp_Luft: type=uint16
    IF_FSA_Temp_Sensor
      data DE_FSA_Temp_Sensor: type=uint16
    IF_FSH_Status
      data DE_FSH_Status: type=uint8
    IF_FSH_Taster
      data DE_FSH_Taster: type=boolean
    IF_FT_FH_Oeffnung
      data DE_FT_FH_Oeffnung: type=uint8
    IF_FT_FH_Oeffnung_4Bit
      data DE_FT_FH_Oeffnung_4Bit: type=uint8
    IF_FT_Tuer_geoeffnet
      data DE_FT_Tuer_geoeffnet: type=boolean
    IF_Geblaesestufe
      data DE_Geblaesestufe: type=uint8
    IF_GNSS_Breite_Ortung
      data DE_GNSS_Breite_Ortung: type=uint32
    IF_GNSS_DR_Breite_Ortung
      data DE_GNSS_DR_Breite_Ortung: type=uint32
    IF_GNSS_DR_Laenge_Ortung
      data DE_GNSS_DR_Laenge_Ortung: type=uint32
    IF_GNSS_DR_Ortung_Ausrichtung
      data DE_GNSS_DR_Ortung_Ausrichtung: type=uint16
    IF_GNSS_DR_Ortung_Hoehe
      data DE_GNSS_DR_Ortung_Hoehe: type=uint16
    IF_GNSS_DR_Richtung_Breite_Ortung
      data DE_GNSS_DR_Richtung_Breite_Ortung: type=boolean
    IF_GNSS_DR_Richtung_Laenge_Ortung
      data DE_GNSS_DR_Richtung_Laenge_Ortung: type=boolean
    IF_GNSS_DR_UTC_Zeit
      data DE_GNSS_DR_UTC_Zeit: type=uint32
    IF_GNSS_Laenge_Ortung
      data DE_GNSS_Laenge_Ortung: type=uint32
    IF_GNSS_Ortung_Ausrichtung
      data DE_GNSS_Ortung_Ausrichtung: type=uint16
    IF_GNSS_Ortung_Hoehe
      data DE_GNSS_Ortung_Hoehe: type=uint16
    IF_GNSS_Richtung_Breite_Ortung
      data DE_GNSS_Richtung_Breite_Ortung: type=boolean
    IF_GNSS_Richtung_Laenge_Ortung
      data DE_GNSS_Richtung_Laenge_Ortung: type=boolean
    IF_GNSS_UTC_Zeit
      data DE_GNSS_UTC_Zeit: type=uint32
    IF_HBFS_FH_Oeffnung
      data DE_HBFS_FH_Oeffnung: type=uint8
    IF_HBFS_FH_Oeffnung_4Bit
      data DE_HBFS_FH_Oeffnung_4Bit: type=uint8
    IF_HBFS_Tuer_geoeffnet
      data DE_HBFS_Tuer_geoeffnet: type=boolean
    IF_HDSG_Anf_Umluftklappe
      data DE_HDSG_Anf_Umluftklappe: type=boolean
    IF_HFS_FH_Oeffnung
      data DE_HFS_FH_Oeffnung: type=uint8
    IF_HFS_FH_Oeffnung_4Bit
      data DE_HFS_FH_Oeffnung_4Bit: type=uint8
    IF_HFS_Tuer_geoeffnet
      data DE_HFS_Tuer_geoeffnet: type=boolean
    IF_HLR_FSH_Freigabe
      data DE_HLR_FSH_Freigabe: type=uint8
    IF_HLR_HSH_Freigabe
      data DE_HLR_HSH_Freigabe: type=boolean
    IF_HLR_LRH_Freigabe
      data DE_HLR_LRH_Freigabe: type=boolean
    IF_HLR_SIH_Freigabe_Fond
      data DE_HLR_SIH_Freigabe_Fond: type=boolean
    IF_HLR_SIH_Freigabe_HL
      data DE_HLR_SIH_Freigabe_HL: type=uint8
    IF_HLR_SIH_Freigabe_HR
      data DE_HLR_SIH_Freigabe_HR: type=uint8
    IF_HLR_SIH_Freigabe_VL
      data DE_HLR_SIH_Freigabe_VL: type=uint8
    IF_HLR_SIH_Freigabe_VR
      data DE_HLR_SIH_Freigabe_VR: type=uint8
    IF_HLR_SIL_Freigabe_HL
      data DE_HLR_SIL_Freigabe_HL: type=uint8
    IF_HLR_SIL_Freigabe_HR
      data DE_HLR_SIL_Freigabe_HR: type=uint8
    IF_HLR_SIL_Freigabe_VL
      data DE_HLR_SIL_Freigabe_VL: type=uint8
    IF_HLR_SIL_Freigabe_VR
      data DE_HLR_SIL_Freigabe_VR: type=uint8
    IF_HSH_Relais_Anf
      data DE_HSH_Relais_Anf: type=boolean
    IF_HSH_Status
      data DE_HSH_Status: type=uint8
    IF_HSH_Taster
      data DE_HSH_Taster: type=uint8
    IF_HV_Bordnetz_aktiv
      data DE_HV_Bordnetz_aktiv: type=boolean
    IF_HV_Bordnetz_Fehler
      data DE_HV_Bordnetz_Fehler: type=boolean
    IF_HV_H3_Err_intern
      data DE_HV_H3_Err_intern: type=boolean
    IF_HV_H3_Err_Leckagestrom
      data DE_HV_H3_Err_Leckagestrom: type=boolean
    IF_HV_H3_Err_Temperaturschutz
      data DE_HV_H3_Err_Temperaturschutz: type=boolean
    IF_HV_H3_Err_Ueberstromabschaltung
      data DE_HV_H3_Err_Ueberstromabschaltung: type=boolean
    IF_HV_H3_HIGH_VOLTAGE
      data DE_HV_H3_HIGH_VOLTAGE: type=uint8
    IF_HV_H3_HIGH_VOLTAGE_ERR
      data DE_HV_H3_HIGH_VOLTAGE_ERR: type=uint8
    IF_HV_H3_I_ist
      data DE_HV_H3_I_ist: type=uint8
    IF_HV_H3_ResponseError
      data DE_HV_H3_ResponseError: type=boolean
    IF_HV_H3_Status_Heizer
      data DE_HV_H3_Status_Heizer: type=uint8
    IF_HV_H3_Status_Heizkreis_1
      data DE_HV_H3_Status_Heizkreis_1: type=uint8
    IF_HV_H3_Status_Heizkreis_2
      data DE_HV_H3_Status_Heizkreis_2: type=uint8
    IF_HV_H3_Status_Heizkreis_3
      data DE_HV_H3_Status_Heizkreis_3: type=uint8
    IF_HV_H3_Status_Heizkreis_4
      data DE_HV_H3_Status_Heizkreis_4: type=uint8
    IF_HV_H3_Status_UBatt_NV
      data DE_HV_H3_Status_UBatt_NV: type=uint8
    IF_HV_H3_Temp_PCB
      data DE_HV_H3_Temp_PCB: type=uint8
    IF_HV_H3_TimeOut_Fehler
      data DE_HV_H3_TimeOut_Fehler: type=boolean
    IF_HV_H3_UBatt_NV
      data DE_HV_H3_UBatt_NV: type=uint8
    IF_HV_H3b_Err_intern
      data DE_HV_H3b_Err_intern: type=boolean
    IF_HV_H3b_Err_Leckagestrom
      data DE_HV_H3b_Err_Leckagestrom: type=boolean
    IF_HV_H3b_Err_Temperaturschutz
      data DE_HV_H3b_Err_Temperaturschutz: type=boolean
    IF_HV_H3b_Err_Ueberstromabschaltung
      data DE_HV_H3b_Err_Ueberstromabschaltung: type=boolean
    IF_HV_H3b_HIGH_VOLTAGE
      data DE_HV_H3b_HIGH_VOLTAGE: type=uint8
    IF_HV_H3b_HIGH_VOLTAGE_ERR
      data DE_HV_H3b_HIGH_VOLTAGE_ERR: type=uint8
    IF_HV_H3b_I_ist
      data DE_HV_H3b_I_ist: type=uint8
    IF_HV_H3b_ResponseError
      data DE_HV_H3b_ResponseError: type=boolean
    IF_HV_H3b_Status_Heizer
      data DE_HV_H3b_Status_Heizer: type=uint8
    IF_HV_H3b_Status_Heizkreis_1
      data DE_HV_H3b_Status_Heizkreis_1: type=uint8
    IF_HV_H3b_Status_Heizkreis_2
      data DE_HV_H3b_Status_Heizkreis_2: type=uint8
    IF_HV_H3b_Status_Heizkreis_3
      data DE_HV_H3b_Status_Heizkreis_3: type=uint8
    IF_HV_H3b_Status_Heizkreis_4
      data DE_HV_H3b_Status_Heizkreis_4: type=uint8
    IF_HV_H3b_Status_UBatt_NV
      data DE_HV_H3b_Status_UBatt_NV: type=uint8
    IF_HV_H3b_Temp_PCB
      data DE_HV_H3b_Temp_PCB: type=uint8
    IF_HV_H3b_TimeOut_Fehler
      data DE_HV_H3b_TimeOut_Fehler: type=boolean
    IF_HV_H3b_UBatt_NV
      data DE_HV_H3b_UBatt_NV: type=uint8
    IF_HV_H3be_Geblaesedrehzahl
      data DE_HV_H3be_Geblaesedrehzahl: type=uint8
    IF_HV_H3be_Heizer_ein
      data DE_HV_H3be_Heizer_ein: type=boolean
    IF_HV_H3be_Heizer_links_soll
      data DE_HV_H3be_Heizer_links_soll: type=uint8
    IF_HV_H3be_Heizer_Mitte_soll
      data DE_HV_H3be_Heizer_Mitte_soll: type=uint8
    IF_HV_H3be_Heizer_rechts_soll
      data DE_HV_H3be_Heizer_rechts_soll: type=uint8
    IF_HV_H3be_Heizgaskuehler
      data DE_HV_H3be_Heizgaskuehler: type=boolean
    IF_HV_H3be_Heizsystem
      data DE_HV_H3be_Heizsystem: type=uint8
    IF_HV_H3be_PTC_Zonenanzahl
      data DE_HV_H3be_PTC_Zonenanzahl: type=uint8
    IF_HV_H3be_Tempklappenwinkel_li
      data DE_HV_H3be_Tempklappenwinkel_li: type=uint8
    IF_HV_H3be_Tempklappenwinkel_mi
      data DE_HV_H3be_Tempklappenwinkel_mi: type=uint8
    IF_HV_H3be_Tempklappenwinkel_re
      data DE_HV_H3be_Tempklappenwinkel_re: type=uint8
    IF_HV_H3be_Verdampfertemp_Delta
      data DE_HV_H3be_Verdampfertemp_Delta: type=uint8
    IF_HV_H3be_Verdampfertemp_min
      data DE_HV_H3be_Verdampfertemp_min: type=uint8
    IF_HV_H3e_Geblaesedrehzahl
      data DE_HV_H3e_Geblaesedrehzahl: type=uint8
    IF_HV_H3e_Heizer_ein
      data DE_HV_H3e_Heizer_ein: type=boolean
    IF_HV_H3e_Heizer_links_soll
      data DE_HV_H3e_Heizer_links_soll: type=uint8
    IF_HV_H3e_Heizer_Mitte_soll
      data DE_HV_H3e_Heizer_Mitte_soll: type=uint8
    IF_HV_H3e_Heizer_rechts_soll
      data DE_HV_H3e_Heizer_rechts_soll: type=uint8
    IF_HV_H3e_Heizgaskuehler
      data DE_HV_H3e_Heizgaskuehler: type=boolean
    IF_HV_H3e_Heizsystem
      data DE_HV_H3e_Heizsystem: type=uint8
    IF_HV_H3e_PTC_Zonenanzahl
      data DE_HV_H3e_PTC_Zonenanzahl: type=uint8
    IF_HV_H3e_Tempklappenwinkel_li
      data DE_HV_H3e_Tempklappenwinkel_li: type=uint8
    IF_HV_H3e_Tempklappenwinkel_mi
      data DE_HV_H3e_Tempklappenwinkel_mi: type=uint8
    IF_HV_H3e_Tempklappenwinkel_re
      data DE_HV_H3e_Tempklappenwinkel_re: type=uint8
    IF_HV_H3e_Verdampfertemp_Delta
      data DE_HV_H3e_Verdampfertemp_Delta: type=uint8
    IF_HV_H3e_Verdampfertemp_min
      data DE_HV_H3e_Verdampfertemp_min: type=uint8
    IF_HV_H6_aktive_Entladung_Status
      data DE_HV_H6_aktive_Entladung_Status: type=uint8
    IF_HV_H6_Err_Leckagestrom
      data DE_HV_H6_Err_Leckagestrom: type=boolean
    IF_HV_H6_Error_HVH
      data DE_HV_H6_Error_HVH: type=uint8
    IF_HV_H6_Heizmedium_Sensor_1
      data DE_HV_H6_Heizmedium_Sensor_1: type=uint8
    IF_HV_H6_Heizmedium_Sensor_2
      data DE_HV_H6_Heizmedium_Sensor_2: type=uint8
    IF_HV_H6_High_Voltage
      data DE_HV_H6_High_Voltage: type=uint16
    IF_HV_H6_HV_ERR
      data DE_HV_H6_HV_ERR: type=uint8
    IF_HV_H6_I_ist
      data DE_HV_H6_I_ist: type=uint8
    IF_HV_H6_PTC_ResponseError
      data DE_HV_H6_PTC_ResponseError: type=boolean
    IF_HV_H6_Status_HVH
      data DE_HV_H6_Status_HVH: type=uint8
    IF_HV_H6_Status_UBatt
      data DE_HV_H6_Status_UBatt: type=uint8
    IF_HV_H6_Temp_PCB
      data DE_HV_H6_Temp_PCB: type=uint8
    IF_HV_H6_UBatt
      data DE_HV_H6_UBatt: type=uint8
    IF_HVEM_Energie_Klima_Vorgabe
      data DE_HVEM_Energie_Klima_Vorgabe: type=uint8
    IF_HVEM_Energie_Klima_Vorgabe_HighR
      data DE_HVEM_Energie_Klima_Vorgabe_HighR: type=uint8
    IF_HVEM_FreigabeBattHeizung
      data DE_HVEM_FreigabeBattHeizung: type=uint8
    IF_HVEM_FreigabeKlimatisierung
      data DE_HVEM_FreigabeKlimatisierung: type=uint8
    IF_HVEM_HV_Anf
      data DE_HVEM_HV_Anf: type=boolean
    IF_HVEM_Leistung_Bat_Kond_Vorgabe
      data DE_HVEM_Leistung_Bat_Kond_Vorgabe: type=uint8
    IF_HVEM_Leistung_Klima_Vorgabe
      data DE_HVEM_Leistung_Klima_Vorgabe: type=uint8
    IF_HVEM_Nutzbare_Energie
      data DE_HVEM_Nutzbare_Energie: type=uint16
    IF_HVH2_Err_Heizkreis_1
      data DE_HVH2_Err_Heizkreis_1: type=boolean
    IF_HVH2_Err_Heizkreis_2
      data DE_HVH2_Err_Heizkreis_2: type=boolean
    IF_HVH2_Err_Heizkreis_3
      data DE_HVH2_Err_Heizkreis_3: type=boolean
    IF_HVH2_Err_intern
      data DE_HVH2_Err_intern: type=boolean
    IF_HVH2_Err_Leckagestrom
      data DE_HVH2_Err_Leckagestrom: type=boolean
    IF_HVH2_Err_Temperaturschutz
      data DE_HVH2_Err_Temperaturschutz: type=boolean
    IF_HVH2_Err_Ueberstromabschaltung
      data DE_HVH2_Err_Ueberstromabschaltung: type=boolean
    IF_HVH2_Heizmedium_Sensor_1
      data DE_HVH2_Heizmedium_Sensor_1: type=uint8
    IF_HVH2_Heizmedium_Sensor_2
      data DE_HVH2_Heizmedium_Sensor_2: type=uint8
    IF_HVH2_High_Voltage
      data DE_HVH2_High_Voltage: type=uint8
    IF_HVH2_HV_ERR
      data DE_HVH2_HV_ERR: type=uint8
    IF_HVH2_I_ist
      data DE_HVH2_I_ist: type=uint8
    IF_HVH2_ResponseError
      data DE_HVH2_ResponseError: type=boolean
    IF_HVH2_Status_HVH
      data DE_HVH2_Status_HVH: type=uint8
    IF_HVH2_Status_UBatt
      data DE_HVH2_Status_UBatt: type=uint8
    IF_HVH2_Temp_PCB
      data DE_HVH2_Temp_PCB: type=uint8
    IF_HVH2_Timeout_Fehler
      data DE_HVH2_Timeout_Fehler: type=boolean
    IF_HVH2_UBatt
      data DE_HVH2_UBatt: type=uint8
    IF_HVH_ErrMem_State
      data DE_HVH_ErrMem_State: type=uint8
    IF_HVH_HV_Ilock_Status
      data DE_HVH_HV_Ilock_Status: type=uint8
    IF_HVH_HV_Voltage
      data DE_HVH_HV_Voltage: type=uint16
    IF_HVH_HV_Voltage_Offset
      data DE_HVH_HV_Voltage_Offset: type=uint8
    IF_HVH_HVb_Ilock_Status
      data DE_HVH_HVb_Ilock_Status: type=uint8
    IF_HVH_HVb_Voltage
      data DE_HVH_HVb_Voltage: type=uint16
    IF_HVH_HVb_Voltage_Offset
      data DE_HVH_HVb_Voltage_Offset: type=uint8
    IF_HVH_ParameterChange
      data DE_HVH_ParameterChange: type=boolean
    IF_HVHb_ErrMem_State
      data DE_HVHb_ErrMem_State: type=uint8
    IF_HVHb_ParameterChange
      data DE_HVHb_ParameterChange: type=boolean
    IF_HVK_AktiveEntladung_Anf
      data DE_HVK_AktiveEntladung_Anf: type=boolean
    IF_HVK_HV_Netz_Warnungen
      data DE_HVK_HV_Netz_Warnungen: type=uint8
    IF_HVK_Iso_Messung_Start
      data DE_HVK_Iso_Messung_Start: type=uint8
    IF_HVK_Notabschaltung_Anf
      data DE_HVK_Notabschaltung_Anf: type=uint8
    IF_HVK_Vorladung_aktiv
      data DE_HVK_Vorladung_aktiv: type=boolean
    IF_HVLM_DCBoostLaden_Anf
      data DE_HVLM_DCBoostLaden_Anf: type=uint8
    IF_IAA_Active_User_ID
      data DE_IAA_Active_User_ID: type=uint8
    IF_IAA_Identified_User_ID
      data DE_IAA_Identified_User_ID: type=uint8
    IF_IAA_PSO_wake_up
      data DE_IAA_PSO_wake_up: type=boolean
    IF_ICO2_Alarm
      data DE_ICO2_Alarm: type=uint8
    IF_ICO2_BZ
      data DE_ICO2_BZ: type=uint8
    IF_ICO2_CO2_Wert
      data DE_ICO2_CO2_Wert: type=uint16
    IF_ICO2_defekt
      data DE_ICO2_defekt: type=boolean
    IF_ICO2_Gradient
      data DE_ICO2_Gradient: type=uint16
    IF_ICO2_Laufzeit
      data DE_ICO2_Laufzeit: type=uint16
    IF_ICO2_Luftdruck
      data DE_ICO2_Luftdruck: type=uint16
    IF_ICO2_Luftdruck_2
      data DE_ICO2_Luftdruck_2: type=uint16
    IF_ICO2_Messvorgabe
      data DE_ICO2_Messvorgabe: type=uint8
    IF_ICO2_Messzyklus1
      data DE_ICO2_Messzyklus1: type=uint8
    IF_ICO2_Messzyklus2
      data DE_ICO2_Messzyklus2: type=uint8
    IF_ICO2_ResponseError
      data DE_ICO2_ResponseError: type=boolean
    IF_ICO2_Status_Kabine
      data DE_ICO2_Status_Kabine: type=uint8
    IF_ICO2b_Alarm
      data DE_ICO2b_Alarm: type=uint8
    IF_ICO2b_BZ
      data DE_ICO2b_BZ: type=uint8
    IF_ICO2b_CO2_Wert
      data DE_ICO2b_CO2_Wert: type=uint16
    IF_ICO2b_defekt
      data DE_ICO2b_defekt: type=boolean
    IF_ICO2b_Gradient
      data DE_ICO2b_Gradient: type=uint16
    IF_ICO2b_Laufzeit
      data DE_ICO2b_Laufzeit: type=uint16
    IF_ICO2b_Luftdruck
      data DE_ICO2b_Luftdruck: type=uint16
    IF_ICO2b_Luftdruck_2
      data DE_ICO2b_Luftdruck_2: type=uint16
    IF_ICO2b_Messvorgabe
      data DE_ICO2b_Messvorgabe: type=uint8
    IF_ICO2b_Messzyklus1
      data DE_ICO2b_Messzyklus1: type=uint8
    IF_ICO2b_Messzyklus2
      data DE_ICO2b_Messzyklus2: type=uint8
    IF_ICO2b_ResponseError
      data DE_ICO2b_ResponseError: type=boolean
    IF_ICO2b_Status_Kabine
      data DE_ICO2b_Status_Kabine: type=uint8
    IF_ION_0e_Dummy
      data DE_ION_0e_Dummy: type=uint8
    IF_ION_0s_Dummy
      data DE_ION_0s_Dummy: type=uint8
    IF_ION_Adressegment
      data DE_ION_Adressegment: type=uint8
    IF_ION_Adressinhalt
      data DE_ION_Adressinhalt: type=uint8
    IF_ION_BZ
      data DE_ION_BZ: type=uint8
    IF_ION_Fehler_Emitter
      data DE_ION_Fehler_Emitter: type=uint8
    IF_ION_Fehler_Emitter_2
      data DE_ION_Fehler_Emitter_2: type=uint8
    IF_ION_Fehler_Intern
      data DE_ION_Fehler_Intern: type=uint8
    IF_ION_Fehler_LED
      data DE_ION_Fehler_LED: type=uint8
    IF_ION_Fehler_Taster
      data DE_ION_Fehler_Taster: type=boolean
    IF_ION_FehlerGueltigkeit
      data DE_ION_FehlerGueltigkeit: type=boolean
    IF_ION_HW
      data DE_ION_HW: type=uint8
    IF_ION_ResponseError
      data DE_ION_ResponseError: type=boolean
    IF_ION_Status
      data DE_ION_Status: type=uint8
    IF_ION_Status_LED
      data DE_ION_Status_LED: type=boolean
    IF_ION_Status_Taster
      data DE_ION_Status_Taster: type=boolean
    IF_ION_SW
      data DE_ION_SW: type=uint8
    IF_ISOALLReqB0
      data DE_ISOALLReqB0: type=uint8
    IF_ISOALLReqB1
      data DE_ISOALLReqB1: type=uint8
    IF_ISOALLReqB2
      data DE_ISOALLReqB2: type=uint8
    IF_ISOALLReqB3
      data DE_ISOALLReqB3: type=uint8
    IF_ISOALLReqB4
      data DE_ISOALLReqB4: type=uint8
    IF_ISOALLReqB5
      data DE_ISOALLReqB5: type=uint8
    IF_ISOALLReqB6
      data DE_ISOALLReqB6: type=uint8
    IF_ISOALLReqB7
      data DE_ISOALLReqB7: type=uint8
    IF_KBF_defekt
      data DE_KBF_defekt: type=boolean
    IF_KBF_Einheiten
      data DE_KBF_Einheiten: type=boolean
    IF_KBF_ResponseError
      data DE_KBF_ResponseError: type=boolean
    IF_KBF_SIH_Diag
      data DE_KBF_SIH_Diag: type=uint8
    IF_KBF_SIH_hl_Status
      data DE_KBF_SIH_hl_Status: type=uint8
    IF_KBF_SIH_hr_Status
      data DE_KBF_SIH_hr_Status: type=uint8
    IF_KBF_Strom_SIH_hl
      data DE_KBF_Strom_SIH_hl: type=uint8
    IF_KBF_Strom_SIH_hr
      data DE_KBF_Strom_SIH_hr: type=uint8
    IF_KBF_Tasten_Fehler
      data DE_KBF_Tasten_Fehler: type=boolean
    IF_KBF_Temp_Fuss_Fond
      data DE_KBF_Temp_Fuss_Fond: type=uint8
    IF_KBF_Temp_MA_Fond
      data DE_KBF_Temp_MA_Fond: type=uint8
    IF_KBF_Temp_SIH_hl
      data DE_KBF_Temp_SIH_hl: type=uint8
    IF_KBF_Temp_SIH_hr
      data DE_KBF_Temp_SIH_hr: type=uint8
    IF_KBI_Aussen_Temp_gef
      data DE_KBI_Aussen_Temp_gef: type=uint8
    IF_KBI_Einheit_Temp
      data DE_KBI_Einheit_Temp: type=boolean
    IF_KBI_Kilometerstand
      data DE_KBI_Kilometerstand: type=uint32
    IF_KBI_QBit_Aussen_Temp_gef
      data DE_KBI_QBit_Aussen_Temp_gef: type=boolean
    IF_KBT_CODE_VEHICLE
      data DE_KBT_CODE_VEHICLE: type=uint8
    IF_KBT_Defrost_aktiv
      data DE_KBT_Defrost_aktiv: type=boolean
    IF_KBT_RAMP
      data DE_KBT_RAMP: type=uint8
    IF_KBT_RX_FREQUENCY
      data DE_KBT_RX_FREQUENCY: type=uint16
    IF_KBT_SAFETY_SPEED
      data DE_KBT_SAFETY_SPEED: type=uint8
    IF_KBT_SPEED
      data DE_KBT_SPEED: type=uint8
    IF_KL_AC_Schalter
      data DE_KL_AC_Schalter: type=boolean
    IF_KL_ActiveDischarge
      data DE_KL_ActiveDischarge: type=boolean
    IF_KL_AirCleaner_aktiv
      data DE_KL_AirCleaner_aktiv: type=boolean
    IF_KL_Ak_Verd_hi_li
      data DE_KL_Ak_Verd_hi_li: type=uint8
    IF_KL_Ak_Verd_hi_re
      data DE_KL_Ak_Verd_hi_re: type=uint8
    IF_KL_Ak_Verd_hinten
      data DE_KL_Ak_Verd_hinten: type=uint8
    IF_KL_Ak_Verd_links
      data DE_KL_Ak_Verd_links: type=uint8
    IF_KL_Ak_Verd_rechts
      data DE_KL_Ak_Verd_rechts: type=uint8
    IF_KL_Ak_Verd_vo_li
      data DE_KL_Ak_Verd_vo_li: type=uint8
    IF_KL_Ak_Verd_vo_re
      data DE_KL_Ak_Verd_vo_re: type=uint8
    IF_KL_Ak_Verd_vorne
      data DE_KL_Ak_Verd_vorne: type=uint8
    IF_KL_AL_HL_Anf
      data DE_KL_AL_HL_Anf: type=uint8
    IF_KL_AL_HR_Anf
      data DE_KL_AL_HR_Anf: type=uint8
    IF_KL_AL_VL_Anf
      data DE_KL_AL_VL_Anf: type=uint8
    IF_KL_AL_VR_Anf
      data DE_KL_AL_VR_Anf: type=uint8
    IF_KL_Anf_AussenspiegelHzg
      data DE_KL_Anf_AussenspiegelHzg: type=boolean
    IF_KL_Anf_KL
      data DE_KL_Anf_KL: type=uint8
    IF_KL_Anf_KV
      data DE_KL_Anf_KV: type=uint8
    IF_KL_Anf_rLM
      data DE_KL_Anf_rLM: type=uint8
    IF_KL_Anz_auto_hl
      data DE_KL_Anz_auto_hl: type=boolean
    IF_KL_Anz_Geblaese_hl
      data DE_KL_Anz_Geblaese_hl: type=uint8
    IF_KL_Anz_mitte_hl
      data DE_KL_Anz_mitte_hl: type=boolean
    IF_KL_Anz_oben_hl
      data DE_KL_Anz_oben_hl: type=boolean
    IF_KL_Anz_seite_defog_hl
      data DE_KL_Anz_seite_defog_hl: type=boolean
    IF_KL_Anz_seite_hl
      data DE_KL_Anz_seite_hl: type=boolean
    IF_KL_Anz_Temp_Einheit
      data DE_KL_Anz_Temp_Einheit: type=uint8
    IF_KL_Anz_Temp_hl
      data DE_KL_Anz_Temp_hl: type=uint8
    IF_KL_Anz_Temp_hr
      data DE_KL_Anz_Temp_hr: type=uint8
    IF_KL_Anz_unten_hl
      data DE_KL_Anz_unten_hl: type=boolean
    IF_KL_AQI_Innenraum
      data DE_KL_AQI_Innenraum: type=uint8
    IF_KL_Ausstattung_Klima
      data DE_KL_Ausstattung_Klima: type=uint8
    IF_KL_Batterieheizen_Freigabe
      data DE_KL_Batterieheizen_Freigabe: type=uint8
    IF_KL_BattKond_WaPu_DZMax
      data DE_KL_BattKond_WaPu_DZMax: type=uint8
    IF_KL_BCmE_Livetip_Freigabe
      data DE_KL_BCmE_Livetip_Freigabe: type=boolean
    IF_KL_Beschlagsgefahr
      data DE_KL_Beschlagsgefahr: type=boolean
    IF_KL_Charisma_FahrPr
      data DE_KL_Charisma_FahrPr: type=uint8
    IF_KL_Charisma_Status
      data DE_KL_Charisma_Status: type=uint8
    IF_KL_Defrost_LED
      data DE_KL_Defrost_LED: type=boolean
    IF_KL_Drehz_Anh
      data DE_KL_Drehz_Anh: type=boolean
    IF_KL_Einheiten
      data DE_KL_Einheiten: type=boolean
    IF_KL_EKK_Strom
      data DE_KL_EKK_Strom: type=uint8
    IF_KL_el_Zuheizer_Stufe
      data DE_KL_el_Zuheizer_Stufe: type=uint8
    IF_KL_Enteisung_Anf
      data DE_KL_Enteisung_Anf: type=uint8
    IF_KL_ErwVK_Anf
      data DE_KL_ErwVK_Anf: type=boolean
    IF_KL_ErwVK_Beifahrerzone
      data DE_KL_ErwVK_Beifahrerzone: type=boolean
    IF_KL_ErwVK_Fahrerzone
      data DE_KL_ErwVK_Fahrerzone: type=boolean
    IF_KL_ErwVK_Heckzone_links
      data DE_KL_ErwVK_Heckzone_links: type=boolean
    IF_Kl_ErwVK_Heckzone_rechts
      data DE_Kl_ErwVK_Heckzone_rechts: type=boolean
    IF_KL_ErwVK_Scheibenheizung
      data DE_KL_ErwVK_Scheibenheizung: type=boolean
    IF_KL_ErwVK_Status
      data DE_KL_ErwVK_Status: type=uint8
    IF_KL_eTM_SollVolumenstrom
      data DE_KL_eTM_SollVolumenstrom: type=uint8
    IF_KL_Fehler_HV_EKK
      data DE_KL_Fehler_HV_EKK: type=uint8
    IF_KL_Fehler_HV_Heizer
      data DE_KL_Fehler_HV_Heizer: type=uint8
    IF_KL_Fehler_NTKreis
      data DE_KL_Fehler_NTKreis: type=boolean
    IF_KL_Fond_Status
      data DE_KL_Fond_Status: type=boolean
    IF_KL_Fondbedienung_aktiv
      data DE_KL_Fondbedienung_aktiv: type=boolean
    IF_KL_Freilauf_Info
      data DE_KL_Freilauf_Info: type=uint8
    IF_KL_FSH_Automatikbetrieb
      data DE_KL_FSH_Automatikbetrieb: type=boolean
    IF_KL_FSH_LED
      data DE_KL_FSH_LED: type=boolean
    IF_KL_FSH_Soll
      data DE_KL_FSH_Soll: type=boolean
    IF_KL_Geblaese_Fond_Status
      data DE_KL_Geblaese_Fond_Status: type=uint8
    IF_KL_Geblaese_Status
      data DE_KL_Geblaese_Status: type=uint8
    IF_KL_Geblspng_Fond_Soll
      data DE_KL_Geblspng_Fond_Soll: type=uint8
    IF_KL_Geblspng_Soll
      data DE_KL_Geblspng_Soll: type=uint8
    IF_KL_HBT_Geblaesestufe_anzeigen
      data DE_KL_HBT_Geblaesestufe_anzeigen: type=uint8
    IF_KL_HBT_Verbausituation
      data DE_KL_HBT_Verbausituation: type=uint8
    IF_KL_Heizbedarf
      data DE_KL_Heizbedarf: type=uint16
    IF_KL_Heizbedarf_Anf
      data DE_KL_Heizbedarf_Anf: type=uint8
    IF_KL_Heizen_Status
      data DE_KL_Heizen_Status: type=uint8
    IF_KL_Heizkreisventilstellung
      data DE_KL_Heizkreisventilstellung: type=uint8
    IF_KL_Heizstufe_LSH
      data DE_KL_Heizstufe_LSH: type=uint8
    IF_KL_Hinweis_Kuehlmodus
      data DE_KL_Hinweis_Kuehlmodus: type=uint8
    IF_KL_HSH_LED
      data DE_KL_HSH_LED: type=boolean
    IF_KL_HSH_Soll
      data DE_KL_HSH_Soll: type=boolean
    IF_KL_HUP_aktiv
      data DE_KL_HUP_aktiv: type=boolean
    IF_KL_HV_Energie_Anf
      data DE_KL_HV_Energie_Anf: type=uint8
    IF_KL_HV_H6_aktive_Entladung
      data DE_KL_HV_H6_aktive_Entladung: type=boolean
    IF_KL_HV_H6_Durchflussrichtung
      data DE_KL_HV_H6_Durchflussrichtung: type=boolean
    IF_KL_HV_H6_ein
      data DE_KL_HV_H6_ein: type=boolean
    IF_KL_HV_H6_soll
      data DE_KL_HV_H6_soll: type=uint8
    IF_KL_HV_Hb_ein
      data DE_KL_HV_Hb_ein: type=boolean
    IF_KL_HV_Hb_soll
      data DE_KL_HV_Hb_soll: type=uint8
    IF_KL_HV_Heizer_Strom
      data DE_KL_HV_Heizer_Strom: type=uint8
    IF_KL_HV_PTC_ein
      data DE_KL_HV_PTC_ein: type=boolean
    IF_KL_HV_PTC_soll
      data DE_KL_HV_PTC_soll: type=uint8
    IF_KL_HVH_1_VerbautStatus
      data DE_KL_HVH_1_VerbautStatus: type=boolean
    IF_KL_HVH_2_Status_Spgfreiheit
      data DE_KL_HVH_2_Status_Spgfreiheit: type=uint8
    IF_KL_HVH_2_VerbautStatus
      data DE_KL_HVH_2_VerbautStatus: type=boolean
    IF_KL_HVH_3_VerbautStatus
      data DE_KL_HVH_3_VerbautStatus: type=boolean
    IF_KL_HVHeizer2_ein
      data DE_KL_HVHeizer2_ein: type=boolean
    IF_KL_HVHeizer2_soll
      data DE_KL_HVHeizer2_soll: type=uint8
    IF_KL_HWT_Sollvolumenstrom
      data DE_KL_HWT_Sollvolumenstrom: type=uint8
    IF_KL_I_Geblaese
      data DE_KL_I_Geblaese: type=uint8
    IF_KL_I_Geblaese_Fond
      data DE_KL_I_Geblaese_Fond: type=uint8
    IF_KL_Innen_Temp
      data DE_KL_Innen_Temp: type=uint8
    IF_KL_Innentemp_KBT_Sensor
      data DE_KL_Innentemp_KBT_Sensor: type=uint16
    IF_KL_Ionisator
      data DE_KL_Ionisator: type=uint8
    IF_KL_IstLeistung
      data DE_KL_IstLeistung: type=uint8
    IF_KL_K_Status
      data DE_KL_K_Status: type=uint8
    IF_KL_KBF_Sync
      data DE_KL_KBF_Sync: type=uint8
    IF_KL_KD_Fehler
      data DE_KL_KD_Fehler: type=boolean
    IF_KL_Kennlinie
      data DE_KL_Kennlinie: type=uint8
    IF_KL_Klappe_Status
      data DE_KL_Klappe_Status: type=uint8
    IF_KL_KLE_Fehler_Anf
      data DE_KL_KLE_Fehler_Anf: type=boolean
    IF_KL_KLh_aus
      data DE_KL_KLh_aus: type=boolean
    IF_KL_KLh_LastMode
      data DE_KL_KLh_LastMode: type=uint8
    IF_KL_KLh_lock
      data DE_KL_KLh_lock: type=boolean
    IF_Kl_Klima_Aktiv
      data DE_Kl_Klima_Aktiv: type=boolean
    IF_KL_Klimastandzeit
      data DE_KL_Klimastandzeit: type=uint16
    IF_KL_KM_ASV_01_Status
      data DE_KL_KM_ASV_01_Status: type=uint8
    IF_KL_KM_ASV_02_Status
      data DE_KL_KM_ASV_02_Status: type=uint8
    IF_KL_Komp_Moment_alt
      data DE_KL_Komp_Moment_alt: type=boolean
    IF_KL_Kompressorstrom_soll
      data DE_KL_Kompressorstrom_soll: type=uint16
    IF_KL_Kuehlungs_Status
      data DE_KL_Kuehlungs_Status: type=uint8
    IF_KL_Kundenwunsch_Kuehlen
      data DE_KL_Kundenwunsch_Kuehlen: type=boolean
    IF_KL_Last_Kompr
      data DE_KL_Last_Kompr: type=uint8
    IF_KL_Leistung_BattHeizung
      data DE_KL_Leistung_BattHeizung: type=uint8
    IF_KL_Leistung_Klima_Anf
      data DE_KL_Leistung_Klima_Anf: type=uint8
    IF_KL_LRH_FoD_Status
      data DE_KL_LRH_FoD_Status: type=uint8
    IF_KL_LRH_PWM
      data DE_KL_LRH_PWM: type=uint8
    IF_KL_LRH_Soll
      data DE_KL_LRH_Soll: type=boolean
    IF_KL_LRH_Stufe
      data DE_KL_LRH_Stufe: type=uint8
    IF_KL_LRH_Taster
      data DE_KL_LRH_Taster: type=boolean
    IF_KL_LSH_Ansteuerung
      data DE_KL_LSH_Ansteuerung: type=uint8
    IF_KL_LSH_Betriebsdauer
      data DE_KL_LSH_Betriebsdauer: type=uint8
    IF_KL_LSH_DBetr_Bestaet
      data DE_KL_LSH_DBetr_Bestaet: type=boolean
    IF_KL_LSH_DBetr_Ein
      data DE_KL_LSH_DBetr_Ein: type=boolean
    IF_KL_Magnetventil
      data DE_KL_Magnetventil: type=boolean
    IF_KL_Meldung_Status
      data DE_KL_Meldung_Status: type=uint8
    IF_Kl_Meldung_Status2
      data DE_Kl_Meldung_Status2: type=uint8
    IF_KL_nachtr_Stopp_Anf
      data DE_KL_nachtr_Stopp_Anf: type=boolean
    IF_KL_OBD_Status
      data DE_KL_OBD_Status: type=boolean
    IF_KL_OBD_Status_Auth
      data DE_KL_OBD_Status_Auth: type=boolean
    IF_KL_PTC_ein
      data DE_KL_PTC_ein: type=boolean
    IF_KL_PTC_Rampe
      data DE_KL_PTC_Rampe: type=uint8
    IF_KL_PTC_soll
      data DE_KL_PTC_soll: type=uint8
    IF_KL_PTC_Verbauinfo
      data DE_KL_PTC_Verbauinfo: type=uint8
    IF_KL_Pumpe_02_Soll
      data DE_KL_Pumpe_02_Soll: type=uint8
    IF_KL_Reheat_Innenraum
      data DE_KL_Reheat_Innenraum: type=uint8
    IF_KL_Restwaerme_aktiv
      data DE_KL_Restwaerme_aktiv: type=boolean
    IF_KL_Scheibe_Typ
      data DE_KL_Scheibe_Typ: type=uint8
    IF_KL_SDA_AQS_COBereich
      data DE_KL_SDA_AQS_COBereich: type=uint8
    IF_KL_SDA_AQS_COStatus
      data DE_KL_SDA_AQS_COStatus: type=uint8
    IF_KL_SDA_AQS_NoxBereich
      data DE_KL_SDA_AQS_NoxBereich: type=uint8
    IF_KL_SDA_AQS_NoxStatus
      data DE_KL_SDA_AQS_NoxStatus: type=uint8
    IF_KL_SDA_AQS_Traffic
      data DE_KL_SDA_AQS_Traffic: type=uint8
    IF_KL_SDA_AQS_VOZBereich
      data DE_KL_SDA_AQS_VOZBereich: type=uint8
    IF_KL_SDA_AQS_VOZStatus
      data DE_KL_SDA_AQS_VOZStatus: type=uint8
    IF_KL_SDA_Klima_Automatik
      data DE_KL_SDA_Klima_Automatik: type=boolean
    IF_KL_SDA_Luft_Feinstaub
      data DE_KL_SDA_Luft_Feinstaub: type=uint8
    IF_KL_SDA_Luft_Qualitaet
      data DE_KL_SDA_Luft_Qualitaet: type=uint8
    IF_KL_SDA_Luftverteilung_Person
      data DE_KL_SDA_Luftverteilung_Person: type=boolean
    IF_KL_SDA_Luftverteilung_Scheibe
      data DE_KL_SDA_Luftverteilung_Scheibe: type=boolean
    IF_KL_SDA_Luftverteilung_Unten
      data DE_KL_SDA_Luftverteilung_Unten: type=boolean
    IF_KL_SDA_Menutaste
      data DE_KL_SDA_Menutaste: type=boolean
    IF_KL_SDA_Sitzheizung_VL
      data DE_KL_SDA_Sitzheizung_VL: type=uint8
    IF_KL_SDA_Sitzheizung_VR
      data DE_KL_SDA_Sitzheizung_VR: type=uint8
    IF_KL_SDA_Sitzlueftung_VL
      data DE_KL_SDA_Sitzlueftung_VL: type=uint8
    IF_KL_SDA_Sitzlueftung_VR
      data DE_KL_SDA_Sitzlueftung_VR: type=uint8
    IF_KL_SDA_Sonderfkt_AirCare
      data DE_KL_SDA_Sonderfkt_AirCare: type=boolean
    IF_KL_SDA_Sonderfkt_HSH
      data DE_KL_SDA_Sonderfkt_HSH: type=boolean
    IF_KL_SDA_Sonderfkt_MaxAC
      data DE_KL_SDA_Sonderfkt_MaxAC: type=boolean
    IF_KL_SDA_Sonderfkt_MaxDefrost
      data DE_KL_SDA_Sonderfkt_MaxDefrost: type=boolean
    IF_KL_SDA_Sonderfunktionen_Sprache
      data DE_KL_SDA_Sonderfunktionen_Sprache: type=uint8
    IF_KL_SDA_Temp_Kundenwunsch_2
      data DE_KL_SDA_Temp_Kundenwunsch_2: type=uint8
    IF_KL_SDA_Temp_Kundenwunsch_3
      data DE_KL_SDA_Temp_Kundenwunsch_3: type=uint8
    IF_KL_SH_Soll_hl
      data DE_KL_SH_Soll_hl: type=uint8
    IF_KL_SH_Soll_hr
      data DE_KL_SH_Soll_hr: type=uint8
    IF_KL_SIH_Anforderung_hl
      data DE_KL_SIH_Anforderung_hl: type=uint8
    IF_KL_SIH_Anforderung_hr
      data DE_KL_SIH_Anforderung_hr: type=uint8
    IF_KL_SIH_hl_Leistung
      data DE_KL_SIH_hl_Leistung: type=uint8
    IF_KL_SIH_hl_Temp_aus
      data DE_KL_SIH_hl_Temp_aus: type=uint8
    IF_KL_SIH_hl_Temp_ein
      data DE_KL_SIH_hl_Temp_ein: type=uint8
    IF_KL_SIH_hl_Vorgabe
      data DE_KL_SIH_hl_Vorgabe: type=uint8
    IF_KL_SIH_hr_Leistung
      data DE_KL_SIH_hr_Leistung: type=uint8
    IF_KL_SIH_hr_Temp_aus
      data DE_KL_SIH_hr_Temp_aus: type=uint8
    IF_KL_SIH_hr_Temp_ein
      data DE_KL_SIH_hr_Temp_ein: type=uint8
    IF_KL_SIH_hr_Vorgabe
      data DE_KL_SIH_hr_Vorgabe: type=uint8
    IF_KL_SIH_LEL_Verteilung_VL
      data DE_KL_SIH_LEL_Verteilung_VL: type=uint8
    IF_KL_SIH_LEL_Verteilung_VR
      data DE_KL_SIH_LEL_Verteilung_VR: type=uint8
    IF_KL_SIH_Soll_li
      data DE_KL_SIH_Soll_li: type=uint8
    IF_KL_SIH_Soll_re
      data DE_KL_SIH_Soll_re: type=uint8
    IF_KL_SIL_Soll_li
      data DE_KL_SIL_Soll_li: type=uint8
    IF_KL_SIL_Soll_re
      data DE_KL_SIL_Soll_re: type=uint8
    IF_KL_Sitzkennlinie_Heck
      data DE_KL_Sitzkennlinie_Heck: type=uint8
    IF_KL_SL_Soll_hl
      data DE_KL_SL_Soll_hl: type=uint8
    IF_KL_SL_Soll_hr
      data DE_KL_SL_Soll_hr: type=uint8
    IF_KL_SMod_SIH_Stufe_LED_hl
      data DE_KL_SMod_SIH_Stufe_LED_hl: type=uint8
    IF_KL_SMod_SIH_Stufe_LED_hr
      data DE_KL_SMod_SIH_Stufe_LED_hr: type=uint8
    IF_KL_SMod_SIL_Stufe_LED_hl
      data DE_KL_SMod_SIL_Stufe_LED_hl: type=uint8
    IF_KL_SMod_SIL_Stufe_LED_hr
      data DE_KL_SMod_SIL_Stufe_LED_hr: type=uint8
    IF_KL_SoSe_Intensitaet_BFS
      data DE_KL_SoSe_Intensitaet_BFS: type=uint8
    IF_KL_SoSe_Intensitaet_FS
      data DE_KL_SoSe_Intensitaet_FS: type=uint8
    IF_KL_Spannungs_Anf
      data DE_KL_Spannungs_Anf: type=uint8
    IF_KL_Standklima_RemoteModus
      data DE_KL_Standklima_RemoteModus: type=uint8
    IF_KL_Standklima_Status_02
      data DE_KL_Standklima_Status_02: type=uint8
    IF_KL_Standklima_Status_03
      data DE_KL_Standklima_Status_03: type=uint8
    IF_KL_StartStopp_Info
      data DE_KL_StartStopp_Info: type=uint8
    IF_KL_Status_Battkuehlung
      data DE_KL_Status_Battkuehlung: type=uint8
    IF_KL_Status_EoHVL_EKK
      data DE_KL_Status_EoHVL_EKK: type=uint8
    IF_KL_Status_EoHVL_Heizer
      data DE_KL_Status_EoHVL_Heizer: type=uint8
    IF_KL_Status_EoHVL_Heizer_2
      data DE_KL_Status_EoHVL_Heizer_2: type=uint8
    IF_KL_Status_EoHVL_Heizer_3
      data DE_KL_Status_EoHVL_Heizer_3: type=uint8
    IF_KL_Status_Soll
      data DE_KL_Status_Soll: type=boolean
    IF_KL_StellgliedtestINV_Heck
      data DE_KL_StellgliedtestINV_Heck: type=boolean
    IF_KL_STH_aktiv
      data DE_KL_STH_aktiv: type=boolean
    IF_KL_STH_Ansteuerung
      data DE_KL_STH_Ansteuerung: type=uint8
    IF_KL_STH_Betriebsdauer
      data DE_KL_STH_Betriebsdauer: type=uint8
    IF_KL_STH_Betriebsdauer_lang
      data DE_KL_STH_Betriebsdauer_lang: type=uint8
    IF_KL_STL_aktiv
      data DE_KL_STL_aktiv: type=boolean
    IF_KL_Stopp_Wiederstart_Anz_01
      data DE_KL_Stopp_Wiederstart_Anz_01: type=boolean
    IF_KL_Stopp_Wiederstart_Anz_02
      data DE_KL_Stopp_Wiederstart_Anz_02: type=boolean
    IF_KL_Stopp_Wiederstart_Anz_03
      data DE_KL_Stopp_Wiederstart_Anz_03: type=boolean
    IF_KL_Stopp_Wiederstart_Anz_04
      data DE_KL_Stopp_Wiederstart_Anz_04: type=boolean
    IF_KL_Stopp_Wiederstart_Anz_05
      data DE_KL_Stopp_Wiederstart_Anz_05: type=boolean
    IF_KL_Stopp_Wiederstart_Anz_06
      data DE_KL_Stopp_Wiederstart_Anz_06: type=boolean
    IF_KL_Stopp_Wiederstart_Anz_07
      data DE_KL_Stopp_Wiederstart_Anz_07: type=boolean
    IF_KL_Stopp_Wiederstart_Anz_08
      data DE_KL_Stopp_Wiederstart_Anz_08: type=boolean
    IF_KL_Stopp_Wiederstart_Anz_09
      data DE_KL_Stopp_Wiederstart_Anz_09: type=boolean
    IF_KL_Stopp_Wiederstart_Anz_Std1
      data DE_KL_Stopp_Wiederstart_Anz_Std1: type=boolean
    IF_KL_Stopp_Wiederstart_Anz_Std2
      data DE_KL_Stopp_Wiederstart_Anz_Std2: type=boolean
    IF_KL_T_Charge
      data DE_KL_T_Charge: type=boolean
    IF_KL_Temp_hl
      data DE_KL_Temp_hl: type=uint8
    IF_KL_Temp_HL_Soll
      data DE_KL_Temp_HL_Soll: type=uint8
    IF_KL_Temp_Kundenwunsch
      data DE_KL_Temp_Kundenwunsch: type=uint8
    IF_KL_Temp_Status_hl
      data DE_KL_Temp_Status_hl: type=uint8
    IF_KL_Temp_vor_NTK
      data DE_KL_Temp_vor_NTK: type=uint8
    IF_KL_Temp_ZH_Soll
      data DE_KL_Temp_ZH_Soll: type=uint8
    IF_KL_Thermomanagement
      data DE_KL_Thermomanagement: type=uint8
    IF_KL_UIF_Parametersatz
      data DE_KL_UIF_Parametersatz: type=uint8
    IF_KL_Umluft_Taste
      data DE_KL_Umluft_Taste: type=boolean
    IF_KL_Umluftklappe_Status
      data DE_KL_Umluftklappe_Status: type=uint8
    IF_KL_Variante_Standheizung
      data DE_KL_Variante_Standheizung: type=uint8
    IF_KL_Ventil_03_Soll
      data DE_KL_Ventil_03_Soll: type=boolean
    IF_KL_Verdeckstatus
      data DE_KL_Verdeckstatus: type=boolean
    IF_KL_VK_Anf
      data DE_KL_VK_Anf: type=uint8
    IF_KL_VK_Betriebsdauer
      data DE_KL_VK_Betriebsdauer: type=uint8
    IF_KL_VoKo_LED
      data DE_KL_VoKo_LED: type=boolean
    IF_KL_Voko_Status
      data DE_KL_Voko_Status: type=uint8
    IF_KL_Vorkond_Strategie
      data DE_KL_Vorkond_Strategie: type=uint8
    IF_KL_Vorwarn_HVHeizer_Leistung
      data DE_KL_Vorwarn_HVHeizer_Leistung: type=uint8
    IF_KL_Vorwarn_Komp_ein
      data DE_KL_Vorwarn_Komp_ein: type=boolean
    IF_KL_Vorwarn_Zuheizer_ein
      data DE_KL_Vorwarn_Zuheizer_ein: type=boolean
    IF_KL_WaPu
      data DE_KL_WaPu: type=boolean
    IF_KL_Wasserheizer_Ansteuerung
      data DE_KL_Wasserheizer_Ansteuerung: type=uint8
    IF_KL_Wasserheizer_IstTemp_Ausgang
      data DE_KL_Wasserheizer_IstTemp_Ausgang: type=uint8
    IF_KL_Wasserheizer_IstTemp_Eingang
      data DE_KL_Wasserheizer_IstTemp_Eingang: type=uint8
    IF_KL_Wasserheizer_SollTemp_Ausgang
      data DE_KL_Wasserheizer_SollTemp_Ausgang: type=uint8
    IF_KL_Wasserheizer_Status
      data DE_KL_Wasserheizer_Status: type=uint8
    IF_KL_ZR_Anforderung
      data DE_KL_ZR_Anforderung: type=uint8
    IF_KL_Zuheizer_Freigabe
      data DE_KL_Zuheizer_Freigabe: type=boolean
    IF_KL_Zustand
      data DE_KL_Zustand: type=boolean
    IF_KL_ZZ_Betriebsmodus
      data DE_KL_ZZ_Betriebsmodus: type=uint8
    IF_KL_ZZ_Minute
      data DE_KL_ZZ_Minute: type=uint8
    IF_KL_ZZ_Monat
      data DE_KL_ZZ_Monat: type=uint8
    IF_KL_ZZ_Status_Timer
      data DE_KL_ZZ_Status_Timer: type=uint8
    IF_KL_ZZ_Stunde
      data DE_KL_ZZ_Stunde: type=uint8
    IF_KL_ZZ_Tag
      data DE_KL_ZZ_Tag: type=uint8
    IF_Klemme_15
      data DE_Klemme_15: type=boolean
    IF_KLh_aus
      data DE_KLh_aus: type=boolean
    IF_KLh_Ausstattung_KlimaHeck
      data DE_KLh_Ausstattung_KlimaHeck: type=uint8
    IF_KLh_Fehler1
      data DE_KLh_Fehler1: type=boolean
    IF_KLh_Fehler2
      data DE_KLh_Fehler2: type=boolean
    IF_KLh_Fehler3
      data DE_KLh_Fehler3: type=boolean
    IF_KLh_Fehler4
      data DE_KLh_Fehler4: type=boolean
    IF_KLh_Fehler5
      data DE_KLh_Fehler5: type=boolean
    IF_KLh_Fehler6
      data DE_KLh_Fehler6: type=boolean
    IF_KLh_Fehler7
      data DE_KLh_Fehler7: type=boolean
    IF_KLh_Fehler8
      data DE_KLh_Fehler8: type=boolean
    IF_KLh_Seite_defog_hl
      data DE_KLh_Seite_defog_hl: type=boolean
    IF_KLh_SIH_Last_defekt_hl
      data DE_KLh_SIH_Last_defekt_hl: type=uint8
    IF_KLh_SIH_Last_defekt_hr
      data DE_KLh_SIH_Last_defekt_hr: type=uint8
    IF_KLh_SIH_NTC_defekt_hl
      data DE_KLh_SIH_NTC_defekt_hl: type=uint8
    IF_KLh_SIH_NTC_defekt_hr
      data DE_KLh_SIH_NTC_defekt_hr: type=uint8
    IF_KLh_SIH_Stufe_hl
      data DE_KLh_SIH_Stufe_hl: type=uint8
    IF_KLh_SIH_Stufe_hr
      data DE_KLh_SIH_Stufe_hr: type=uint8
    IF_KLh_toggle_LVT
      data DE_KLh_toggle_LVT: type=uint8
    IF_KLhl_GeblaeseSoll
      data DE_KLhl_GeblaeseSoll: type=uint8
    IF_KLhl_Luft_auto
      data DE_KLhl_Luft_auto: type=boolean
    IF_KLhl_Luft_mitte
      data DE_KLhl_Luft_mitte: type=boolean
    IF_KLhl_Luft_oben
      data DE_KLhl_Luft_oben: type=boolean
    IF_KLhl_Luft_seite
      data DE_KLhl_Luft_seite: type=boolean
    IF_KLhl_Luft_unten
      data DE_KLhl_Luft_unten: type=boolean
    IF_KLhl_ResponseError
      data DE_KLhl_ResponseError: type=boolean
    IF_KLhl_TempSoll
      data DE_KLhl_TempSoll: type=uint8
    IF_KLhr_TempSoll
      data DE_KLhr_TempSoll: type=uint8
    IF_KLhs_02_alt
      data DE_KLhs_02_alt: type=boolean
    IF_Klima_Abschaltstufe
      data DE_Klima_Abschaltstufe: type=boolean
    IF_Klima_Nachlauftyp
      data DE_Klima_Nachlauftyp: type=uint8
    IF_Klima_Transport_Mode
      data DE_Klima_Transport_Mode: type=boolean
    IF_KN_KL_DiagPfad
      data DE_KN_KL_DiagPfad: type=boolean
    IF_KompressorModus
      data DE_KompressorModus: type=boolean
    IF_KPV_AC
      data DE_KPV_AC: type=boolean
    IF_KPV_AC_max
      data DE_KPV_AC_max: type=boolean
    IF_KPV_AC_Taste
      data DE_KPV_AC_Taste: type=uint8
    IF_KPV_Auto_li
      data DE_KPV_Auto_li: type=boolean
    IF_KPV_Auto_Taste
      data DE_KPV_Auto_Taste: type=uint8
    IF_KPV_AutoSiKli_li
      data DE_KPV_AutoSiKli_li: type=boolean
    IF_KPV_AutoSiKli_re
      data DE_KPV_AutoSiKli_re: type=boolean
    IF_KPV_AutoUmluft
      data DE_KPV_AutoUmluft: type=boolean
    IF_KPV_Beduftung
      data DE_KPV_Beduftung: type=boolean
    IF_KPV_Defrost
      data DE_KPV_Defrost: type=boolean
    IF_KPV_DefrostMAX_Taste
      data DE_KPV_DefrostMAX_Taste: type=uint8
    IF_KPV_ECO
      data DE_KPV_ECO: type=boolean
    IF_KPV_FSH
      data DE_KPV_FSH: type=boolean
    IF_KPV_Geblaese_Auto_li
      data DE_KPV_Geblaese_Auto_li: type=boolean
    IF_KPV_Geblaese_Stufe_li
      data DE_KPV_Geblaese_Stufe_li: type=uint8
    IF_KPV_HSH
      data DE_KPV_HSH: type=boolean
    IF_KPV_HSH_Taste
      data DE_KPV_HSH_Taste: type=uint8
    IF_KPV_Init
      data DE_KPV_Init: type=boolean
    IF_KPV_Init_2
      data DE_KPV_Init_2: type=boolean
    IF_KPV_Ionisator
      data DE_KPV_Ionisator: type=boolean
    IF_KPV_Joker_Taste
      data DE_KPV_Joker_Taste: type=boolean
    IF_KPV_Klima_Menue_MMI
      data DE_KPV_Klima_Menue_MMI: type=boolean
    IF_KPV_Konditionierung_Taste
      data DE_KPV_Konditionierung_Taste: type=boolean
    IF_KPV_Kopfraumheizung_li
      data DE_KPV_Kopfraumheizung_li: type=boolean
    IF_KPV_Kopfraumheizung_re
      data DE_KPV_Kopfraumheizung_re: type=boolean
    IF_KPV_Lokalaktiv
      data DE_KPV_Lokalaktiv: type=boolean
    IF_KPV_Luftverteilung_Auto_li
      data DE_KPV_Luftverteilung_Auto_li: type=boolean
    IF_KPV_Luftverteilung_Mitte_li
      data DE_KPV_Luftverteilung_Mitte_li: type=boolean
    IF_KPV_Luftverteilung_Oben_li
      data DE_KPV_Luftverteilung_Oben_li: type=boolean
    IF_KPV_Luftverteilung_Unten_li
      data DE_KPV_Luftverteilung_Unten_li: type=boolean
    IF_KPV_OBD
      data DE_KPV_OBD: type=uint8
    IF_KPV_OBD_Gruppe
      data DE_KPV_OBD_Gruppe: type=uint8
    IF_KPV_Off
      data DE_KPV_Off: type=boolean
    IF_KPV_Panel_Error
      data DE_KPV_Panel_Error: type=uint8
    IF_KPV_Popup_Content_ZL1R
      data DE_KPV_Popup_Content_ZL1R: type=uint8
    IF_KPV_Popup_Content_ZR1R
      data DE_KPV_Popup_Content_ZR1R: type=uint8
    IF_KPV_PureAir
      data DE_KPV_PureAir: type=boolean
    IF_KPV_Rear
      data DE_KPV_Rear: type=boolean
    IF_KPV_ResponseError
      data DE_KPV_ResponseError: type=boolean
    IF_KPV_Restwaerme
      data DE_KPV_Restwaerme: type=boolean
    IF_KPV_Sitzheizung_li
      data DE_KPV_Sitzheizung_li: type=uint8
    IF_KPV_Sitzheizung_re
      data DE_KPV_Sitzheizung_re: type=uint8
    IF_KPV_Sitzlueftung_li
      data DE_KPV_Sitzlueftung_li: type=uint8
    IF_KPV_Sitzlueftung_re
      data DE_KPV_Sitzlueftung_re: type=uint8
    IF_KPV_Status_Spannung
      data DE_KPV_Status_Spannung: type=uint8
    IF_KPV_Sync
      data DE_KPV_Sync: type=boolean
    IF_KPV_Tasten_Fehler
      data DE_KPV_Tasten_Fehler: type=boolean
    IF_KPV_Temp_li
      data DE_KPV_Temp_li: type=uint8
    IF_KPV_Temp_Platine
      data DE_KPV_Temp_Platine: type=uint8
    IF_KPV_Temp_re
      data DE_KPV_Temp_re: type=uint8
    IF_KPV_Umluft
      data DE_KPV_Umluft: type=boolean
    IF_KPV_Zustand_Off
      data DE_KPV_Zustand_Off: type=boolean
    IF_KPVe_Auto_Toggle
      data DE_KPVe_Auto_Toggle: type=boolean
    IF_KPVe_Einheit
      data DE_KPVe_Einheit: type=boolean
    IF_KPVe_Funktion_AC
      data DE_KPVe_Funktion_AC: type=boolean
    IF_KPVe_Funktion_AC_max
      data DE_KPVe_Funktion_AC_max: type=boolean
    IF_KPVe_Funktion_Auto_li
      data DE_KPVe_Funktion_Auto_li: type=boolean
    IF_KPVe_Funktion_AutoSiKli_li
      data DE_KPVe_Funktion_AutoSiKli_li: type=boolean
    IF_KPVe_Funktion_AutoSiKli_re
      data DE_KPVe_Funktion_AutoSiKli_re: type=boolean
    IF_KPVe_Funktion_AutoUmluft
      data DE_KPVe_Funktion_AutoUmluft: type=boolean
    IF_KPVe_Funktion_Beduftung
      data DE_KPVe_Funktion_Beduftung: type=boolean
    IF_KPVe_Funktion_Defrost
      data DE_KPVe_Funktion_Defrost: type=boolean
    IF_KPVe_Funktion_ECO
      data DE_KPVe_Funktion_ECO: type=boolean
    IF_KPVe_Funktion_ECO_Zone
      data DE_KPVe_Funktion_ECO_Zone: type=boolean
    IF_KPVe_Funktion_FSH
      data DE_KPVe_Funktion_FSH: type=boolean
    IF_KPVe_Funktion_HSH
      data DE_KPVe_Funktion_HSH: type=boolean
    IF_KPVe_Funktion_Ionisator
      data DE_KPVe_Funktion_Ionisator: type=boolean
    IF_KPVe_Funktion_Joker_Taste
      data DE_KPVe_Funktion_Joker_Taste: type=boolean
    IF_KPVe_Funktion_Klima_Menue_MMI
      data DE_KPVe_Funktion_Klima_Menue_MMI: type=boolean
    IF_KPVe_Funktion_Konditionierung
      data DE_KPVe_Funktion_Konditionierung: type=uint8
    IF_KPVe_Funktion_Locked
      data DE_KPVe_Funktion_Locked: type=boolean
    IF_KPVe_Funktion_OBD
      data DE_KPVe_Funktion_OBD: type=uint8
    IF_KPVe_Funktion_Off
      data DE_KPVe_Funktion_Off: type=boolean
    IF_KPVe_Funktion_PureAir
      data DE_KPVe_Funktion_PureAir: type=boolean
    IF_KPVe_Funktion_Rear
      data DE_KPVe_Funktion_Rear: type=boolean
    IF_KPVe_Funktion_Restwaerme
      data DE_KPVe_Funktion_Restwaerme: type=boolean
    IF_KPVe_Funktion_Sync
      data DE_KPVe_Funktion_Sync: type=boolean
    IF_KPVe_Funktion_Umluft
      data DE_KPVe_Funktion_Umluft: type=boolean
    IF_KPVe_Funktionsbeleuchtung
      data DE_KPVe_Funktionsbeleuchtung: type=boolean
    IF_KPVe_Geblaese_Auto_li
      data DE_KPVe_Geblaese_Auto_li: type=boolean
    IF_KPVe_Geblaese_Begrenzung
      data DE_KPVe_Geblaese_Begrenzung: type=boolean
    IF_KPVe_Geblaese_Stufe_li
      data DE_KPVe_Geblaese_Stufe_li: type=uint8
    IF_KPVe_Kopfraumheizung_li
      data DE_KPVe_Kopfraumheizung_li: type=uint8
    IF_KPVe_Kopfraumheizung_re
      data DE_KPVe_Kopfraumheizung_re: type=uint8
    IF_KPVe_LCD
      data DE_KPVe_LCD: type=boolean
    IF_KPVe_Lenker_Position
      data DE_KPVe_Lenker_Position: type=boolean
    IF_KPVe_Luftverteilung_Auto_li
      data DE_KPVe_Luftverteilung_Auto_li: type=boolean
    IF_KPVe_Luftverteilung_Mitte_li
      data DE_KPVe_Luftverteilung_Mitte_li: type=boolean
    IF_KPVe_Luftverteilung_Oben_li
      data DE_KPVe_Luftverteilung_Oben_li: type=boolean
    IF_KPVe_Luftverteilung_Unten_li
      data DE_KPVe_Luftverteilung_Unten_li: type=boolean
    IF_KPVe_OBD_Gruppe
      data DE_KPVe_OBD_Gruppe: type=uint8
    IF_KPVe_Sitzheizung_li
      data DE_KPVe_Sitzheizung_li: type=uint8
    IF_KPVe_Sitzheizung_re
      data DE_KPVe_Sitzheizung_re: type=uint8
    IF_KPVe_Sitzlueftung_li
      data DE_KPVe_Sitzlueftung_li: type=uint8
    IF_KPVe_Sitzlueftung_re
      data DE_KPVe_Sitzlueftung_re: type=uint8
    IF_KPVe_Suchbeleuchtung
      data DE_KPVe_Suchbeleuchtung: type=boolean
    IF_KPVe_Symbol_Luftmenge_li
      data DE_KPVe_Symbol_Luftmenge_li: type=boolean
    IF_KPVe_Symbol_Luftverteilung_li
      data DE_KPVe_Symbol_Luftverteilung_li: type=boolean
    IF_KPVe_Temp_li
      data DE_KPVe_Temp_li: type=uint8
    IF_KPVe_Temp_re
      data DE_KPVe_Temp_re: type=uint8
    IF_KPVe_Verbau_AutoSikli
      data DE_KPVe_Verbau_AutoSikli: type=boolean
    IF_KRH_Soll_li
      data DE_KRH_Soll_li: type=uint8
    IF_KRH_Soll_re
      data DE_KRH_Soll_re: type=uint8
    IF_KST_Sonderzustand_Status
      data DE_KST_Sonderzustand_Status: type=uint8
    IF_KVA_Ist_Pos
      data DE_KVA_Ist_Pos: type=uint8
    IF_Ladezustand_02
      data DE_Ladezustand_02: type=uint8
    IF_LHR_01_FnAbbruch_Heizkreis_A
      data DE_LHR_01_FnAbbruch_Heizkreis_A: type=boolean
    IF_LHR_01_FnAbbruch_Heizkreis_B
      data DE_LHR_01_FnAbbruch_Heizkreis_B: type=boolean
    IF_LHR_01_NTC_Temperatur_A
      data DE_LHR_01_NTC_Temperatur_A: type=uint8
    IF_LHR_01_NTC_Temperatur_B
      data DE_LHR_01_NTC_Temperatur_B: type=uint8
    IF_LHR_01_ResponseError
      data DE_LHR_01_ResponseError: type=boolean
    IF_LHR_01_SG_defekt
      data DE_LHR_01_SG_defekt: type=boolean
    IF_LHR_01_Status_Ausgang_A_02
      data DE_LHR_01_Status_Ausgang_A_02: type=uint8
    IF_LHR_01_Status_Ausgang_B_02
      data DE_LHR_01_Status_Ausgang_B_02: type=uint8
    IF_LHR_01_Status_CodierPins
      data DE_LHR_01_Status_CodierPins: type=boolean
    IF_LHR_01_Status_PCB_Uebertemp
      data DE_LHR_01_Status_PCB_Uebertemp: type=boolean
    IF_LHR_01_Status_Taster_A
      data DE_LHR_01_Status_Taster_A: type=uint8
    IF_LHR_01_Status_Taster_B
      data DE_LHR_01_Status_Taster_B: type=uint8
    IF_LHRe_01_AnsteuerVorgabe_A
      data DE_LHRe_01_AnsteuerVorgabe_A: type=uint8
    IF_LHRe_01_AnsteuerVorgabe_B
      data DE_LHRe_01_AnsteuerVorgabe_B: type=uint8
    IF_LHRe_01_Config_NTC_A
      data DE_LHRe_01_Config_NTC_A: type=boolean
    IF_LHRe_01_Config_NTC_B
      data DE_LHRe_01_Config_NTC_B: type=boolean
    IF_LHRe_Global_Unterbrechen_Inv
      data DE_LHRe_Global_Unterbrechen_Inv: type=boolean
    IF_LiSi_Defrost_Taste
      data DE_LiSi_Defrost_Taste: type=uint8
    IF_LiSi_FSH_Taste
      data DE_LiSi_FSH_Taste: type=uint8
    IF_LiSi_HSH_Taste
      data DE_LiSi_HSH_Taste: type=uint8
    IF_LLR_LL1_Blockierung
      data DE_LLR_LL1_Blockierung: type=boolean
    IF_LLR_LL1_CodierPinError
      data DE_LLR_LL1_CodierPinError: type=boolean
    IF_LLR_LL1_Feuchte01
      data DE_LLR_LL1_Feuchte01: type=uint16
    IF_LLR_LL1_Feuchte02
      data DE_LLR_LL1_Feuchte02: type=uint16
    IF_LLR_LL1_Feuchtesensor_01_defekt
      data DE_LLR_LL1_Feuchtesensor_01_defekt: type=boolean
    IF_LLR_LL1_Feuchtesensor_02_defekt
      data DE_LLR_LL1_Feuchtesensor_02_defekt: type=boolean
    IF_LLR_LL1_Ist_Drehzahl
      data DE_LLR_LL1_Ist_Drehzahl: type=uint8
    IF_LLR_LL1_Lokalaktiv
      data DE_LLR_LL1_Lokalaktiv: type=boolean
    IF_LLR_LL1_Luefter_defekt
      data DE_LLR_LL1_Luefter_defekt: type=boolean
    IF_LLR_LL1_ResponseError
      data DE_LLR_LL1_ResponseError: type=boolean
    IF_LLR_LL1_Temperatur_01
      data DE_LLR_LL1_Temperatur_01: type=uint16
    IF_LLR_LL1_Temperatur_02
      data DE_LLR_LL1_Temperatur_02: type=uint16
    IF_LLR_LL1_Ueberspannung
      data DE_LLR_LL1_Ueberspannung: type=boolean
    IF_LLR_LL1_Uebertemperatur
      data DE_LLR_LL1_Uebertemperatur: type=boolean
    IF_LLR_LL1_Unterspannung
      data DE_LLR_LL1_Unterspannung: type=boolean
    IF_LLR_LS1_Blockierung
      data DE_LLR_LS1_Blockierung: type=boolean
    IF_LLR_LS1_CodierPinError
      data DE_LLR_LS1_CodierPinError: type=boolean
    IF_LLR_LS1_Feuchte01
      data DE_LLR_LS1_Feuchte01: type=uint16
    IF_LLR_LS1_Feuchte02
      data DE_LLR_LS1_Feuchte02: type=uint16
    IF_LLR_LS1_Feuchtesensor_01_defekt
      data DE_LLR_LS1_Feuchtesensor_01_defekt: type=boolean
    IF_LLR_LS1_Feuchtesensor_02_defekt
      data DE_LLR_LS1_Feuchtesensor_02_defekt: type=boolean
    IF_LLR_LS1_Ist_Drehzahl
      data DE_LLR_LS1_Ist_Drehzahl: type=uint8
    IF_LLR_LS1_Lokalaktiv
      data DE_LLR_LS1_Lokalaktiv: type=boolean
    IF_LLR_LS1_Luefter_defekt
      data DE_LLR_LS1_Luefter_defekt: type=boolean
    IF_LLR_LS1_ResponseError
      data DE_LLR_LS1_ResponseError: type=boolean
    IF_LLR_LS1_Temperatur_01
      data DE_LLR_LS1_Temperatur_01: type=uint16
    IF_LLR_LS1_Temperatur_02
      data DE_LLR_LS1_Temperatur_02: type=uint16
    IF_LLR_LS1_Ueberspannung
      data DE_LLR_LS1_Ueberspannung: type=boolean
    IF_LLR_LS1_Uebertemperatur
      data DE_LLR_LS1_Uebertemperatur: type=boolean
    IF_LLR_LS1_Unterspannung
      data DE_LLR_LS1_Unterspannung: type=boolean
    IF_LLR_LS2_Blockierung
      data DE_LLR_LS2_Blockierung: type=boolean
    IF_LLR_LS2_CodierPinError
      data DE_LLR_LS2_CodierPinError: type=boolean
    IF_LLR_LS2_Ist_Drehzahl
      data DE_LLR_LS2_Ist_Drehzahl: type=uint8
    IF_LLR_LS2_Lokalaktiv
      data DE_LLR_LS2_Lokalaktiv: type=boolean
    IF_LLR_LS2_Luefter_defekt
      data DE_LLR_LS2_Luefter_defekt: type=boolean
    IF_LLR_LS2_ResponseError
      data DE_LLR_LS2_ResponseError: type=boolean
    IF_LLR_LS2_Ueberspannung
      data DE_LLR_LS2_Ueberspannung: type=boolean
    IF_LLR_LS2_Uebertemperatur
      data DE_LLR_LS2_Uebertemperatur: type=boolean
    IF_LLR_LS2_Unterspannung
      data DE_LLR_LS2_Unterspannung: type=boolean
    IF_LLR_RL1_Blockierung
      data DE_LLR_RL1_Blockierung: type=boolean
    IF_LLR_RL1_CodierPinError
      data DE_LLR_RL1_CodierPinError: type=boolean
    IF_LLR_RL1_Feuchte01
      data DE_LLR_RL1_Feuchte01: type=uint16
    IF_LLR_RL1_Feuchte02
      data DE_LLR_RL1_Feuchte02: type=uint16
    IF_LLR_RL1_Feuchtesensor_01_defekt
      data DE_LLR_RL1_Feuchtesensor_01_defekt: type=boolean
    IF_LLR_RL1_Feuchtesensor_02_defekt
      data DE_LLR_RL1_Feuchtesensor_02_defekt: type=boolean
    IF_LLR_RL1_Ist_Drehzahl
      data DE_LLR_RL1_Ist_Drehzahl: type=uint8
    IF_LLR_RL1_Lokalaktiv
      data DE_LLR_RL1_Lokalaktiv: type=boolean
    IF_LLR_RL1_Luefter_defekt
      data DE_LLR_RL1_Luefter_defekt: type=boolean
    IF_LLR_RL1_ResponseError
      data DE_LLR_RL1_ResponseError: type=boolean
    IF_LLR_RL1_Temperatur_01
      data DE_LLR_RL1_Temperatur_01: type=uint16
    IF_LLR_RL1_Temperatur_02
      data DE_LLR_RL1_Temperatur_02: type=uint16
    IF_LLR_RL1_Ueberspannung
      data DE_LLR_RL1_Ueberspannung: type=boolean
    IF_LLR_RL1_Uebertemperatur
      data DE_LLR_RL1_Uebertemperatur: type=boolean
    IF_LLR_RL1_Unterspannung
      data DE_LLR_RL1_Unterspannung: type=boolean
    IF_LLR_RS1_Blockierung
      data DE_LLR_RS1_Blockierung: type=boolean
    IF_LLR_RS1_CodierPinError
      data DE_LLR_RS1_CodierPinError: type=boolean
    IF_LLR_RS1_Feuchte01
      data DE_LLR_RS1_Feuchte01: type=uint16
    IF_LLR_RS1_Feuchte02
      data DE_LLR_RS1_Feuchte02: type=uint16
    IF_LLR_RS1_Feuchtesensor_01_defekt
      data DE_LLR_RS1_Feuchtesensor_01_defekt: type=boolean
    IF_LLR_RS1_Feuchtesensor_02_defekt
      data DE_LLR_RS1_Feuchtesensor_02_defekt: type=boolean
    IF_LLR_RS1_Ist_Drehzahl
      data DE_LLR_RS1_Ist_Drehzahl: type=uint8
    IF_LLR_RS1_Lokalaktiv
      data DE_LLR_RS1_Lokalaktiv: type=boolean
    IF_LLR_RS1_Luefter_defekt
      data DE_LLR_RS1_Luefter_defekt: type=boolean
    IF_LLR_RS1_ResponseError
      data DE_LLR_RS1_ResponseError: type=boolean
    IF_LLR_RS1_Temperatur_01
      data DE_LLR_RS1_Temperatur_01: type=uint16
    IF_LLR_RS1_Temperatur_02
      data DE_LLR_RS1_Temperatur_02: type=uint16
    IF_LLR_RS1_Ueberspannung
      data DE_LLR_RS1_Ueberspannung: type=boolean
    IF_LLR_RS1_Uebertemperatur
      data DE_LLR_RS1_Uebertemperatur: type=boolean
    IF_LLR_RS1_Unterspannung
      data DE_LLR_RS1_Unterspannung: type=boolean
    IF_LLR_RS2_Blockierung
      data DE_LLR_RS2_Blockierung: type=boolean
    IF_LLR_RS2_CodierPinError
      data DE_LLR_RS2_CodierPinError: type=boolean
    IF_LLR_RS2_Ist_Drehzahl
      data DE_LLR_RS2_Ist_Drehzahl: type=uint8
    IF_LLR_RS2_Lokalaktiv
      data DE_LLR_RS2_Lokalaktiv: type=boolean
    IF_LLR_RS2_Luefter_defekt
      data DE_LLR_RS2_Luefter_defekt: type=boolean
    IF_LLR_RS2_ResponseError
      data DE_LLR_RS2_ResponseError: type=boolean
    IF_LLR_RS2_Ueberspannung
      data DE_LLR_RS2_Ueberspannung: type=boolean
    IF_LLR_RS2_Uebertemperatur
      data DE_LLR_RS2_Uebertemperatur: type=boolean
    IF_LLR_RS2_Unterspannung
      data DE_LLR_RS2_Unterspannung: type=boolean
    IF_LR_HZG_Konfiguration
      data DE_LR_HZG_Konfiguration: type=uint8
    IF_LR_HZG_Temp_Sensor
      data DE_LR_HZG_Temp_Sensor: type=uint8
    IF_LRH_On_Off
      data DE_LRH_On_Off: type=uint8
    IF_LS_Helligkeit_IR
      data DE_LS_Helligkeit_IR: type=uint8
    IF_Luftmenge_Innenraum_PMS
      data DE_Luftmenge_Innenraum_PMS: type=uint8
    IF_MD1_Lage
      data DE_MD1_Lage: type=boolean
    IF_MD1_Position
      data DE_MD1_Position: type=uint8
    IF_MD1_Position_4Bit
      data DE_MD1_Position_4Bit: type=uint8
    IF_MD3_Lage
      data DE_MD3_Lage: type=boolean
    IF_Messung_Enable_PMS
      data DE_Messung_Enable_PMS: type=boolean
    IF_MFL_Eventcode_1
      data DE_MFL_Eventcode_1: type=uint8
    IF_MFL_Eventcode_2
      data DE_MFL_Eventcode_2: type=uint8
    IF_MFL_Tastencode_1
      data DE_MFL_Tastencode_1: type=uint8
    IF_MFL_Tastencode_2
      data DE_MFL_Tastencode_2: type=uint8
    IF_MFL_Variante
      data DE_MFL_Variante: type=uint8
    IF_MIK_PetsMode_state
      data DE_MIK_PetsMode_state: type=boolean
    IF_MO_FSA_Sensorheizung
      data DE_MO_FSA_Sensorheizung: type=boolean
    IF_MO_HVEM_MaxLeistung
      data DE_MO_HVEM_MaxLeistung: type=uint16
    IF_MO_HYB_Fahrbereitschaft
      data DE_MO_HYB_Fahrbereitschaft: type=boolean
    IF_MO_Hybridfahrzeug
      data DE_MO_Hybridfahrzeug: type=uint8
    IF_MO_Klima_Regelmodus
      data DE_MO_Klima_Regelmodus: type=uint8
    IF_MO_Kuehlerluefter_1
      data DE_MO_Kuehlerluefter_1: type=uint8
    IF_MO_Kuehlerluefter_2
      data DE_MO_Kuehlerluefter_2: type=uint8
    IF_MO_Kuehlerluefter_MUX
      data DE_MO_Kuehlerluefter_MUX: type=boolean
    IF_MO_OBD_Typ
      data DE_MO_OBD_Typ: type=uint8
    IF_MO_QBit_Aussen_Temp
      data DE_MO_QBit_Aussen_Temp: type=boolean
    IF_MO_RedFahrleistung_Lampe
      data DE_MO_RedFahrleistung_Lampe: type=boolean
    IF_MRollo_Lage
      data DE_MRollo_Lage: type=boolean
    IF_MRollo_Position
      data DE_MRollo_Position: type=uint8
    IF_MRollo_Position_4Bit
      data DE_MRollo_Position_4Bit: type=uint8
    IF_Navigationsattribute
      data DE_Navigationsattribute: type=uint8
    IF_ND_PSD_Tunnel_Status
      data DE_ND_PSD_Tunnel_Status: type=uint8
    IF_NM_DCDC_NV_NM_State
      data DE_NM_DCDC_NV_NM_State: type=uint8
    IF_NM_Gateway_NM_State
      data DE_NM_Gateway_NM_State: type=uint8
    IF_NM_Hybrid_01_NM_State
      data DE_NM_Hybrid_01_NM_State: type=uint8
    IF_NM_Klima_CBV_AWB
      data DE_NM_Klima_CBV_AWB: type=boolean
    IF_NM_Klima_CBV_CRI
      data DE_NM_Klima_CBV_CRI: type=boolean
    IF_NM_Klima_NM_aktiv_Diagnose
      data DE_NM_Klima_NM_aktiv_Diagnose: type=boolean
    IF_NM_Klima_NM_aktiv_KL15
      data DE_NM_Klima_NM_aktiv_KL15: type=boolean
    IF_NM_Klima_NM_aktiv_Tmin
      data DE_NM_Klima_NM_aktiv_Tmin: type=boolean
    IF_NM_Klima_NM_State
      data DE_NM_Klima_NM_State: type=uint8
    IF_NM_Klima_UDS_CC
      data DE_NM_Klima_UDS_CC: type=boolean
    IF_NM_Klima_Wakeup
      data DE_NM_Klima_Wakeup: type=uint8
    IF_NM_Ladegeraet_NM_State
      data DE_NM_Ladegeraet_NM_State: type=uint8
    IF_NVEM_Abschaltstufe
      data DE_NVEM_Abschaltstufe: type=uint8
    IF_NVEM_Last_Anf
      data DE_NVEM_Last_Anf: type=uint8
    IF_OBD_Abs_Load_Val
      data DE_OBD_Abs_Load_Val: type=uint16
    IF_OBD_Abs_Pedal_Pos
      data DE_OBD_Abs_Pedal_Pos: type=uint8
    IF_OBD_Abs_Throttle_Pos
      data DE_OBD_Abs_Throttle_Pos: type=uint8
    IF_OBD_Calc_Load_Val
      data DE_OBD_Calc_Load_Val: type=uint8
    IF_OBD_Driving_Cycle
      data DE_OBD_Driving_Cycle: type=boolean
    IF_OBD_Eng_Cool_Temp
      data DE_OBD_Eng_Cool_Temp: type=uint8
    IF_OBD_Kaltstart_Denominator
      data DE_OBD_Kaltstart_Denominator: type=boolean
    IF_OBD_Minimum_Trip
      data DE_OBD_Minimum_Trip: type=boolean
    IF_OBD_Normed_Trip
      data DE_OBD_Normed_Trip: type=boolean
    IF_OBD_Sperrung_IUMPR
      data DE_OBD_Sperrung_IUMPR: type=boolean
    IF_OBD_Warm_Up_Cycle
      data DE_OBD_Warm_Up_Cycle: type=boolean
    IF_OBDProtocol_Klima
      data DE_OBDProtocol_Klima: type=uint8
    IF_OBDProtocol_req
      data DE_OBDProtocol_req: type=uint8
    IF_OPS_ComfortReadyStatus
      data DE_OPS_ComfortReadyStatus: type=uint8
    IF_OPS_DriverPresenceStatus
      data DE_OPS_DriverPresenceStatus: type=uint8
    IF_OPS_OccupantPresenceStatus
      data DE_OPS_OccupantPresenceStatus: type=uint8
    IF_OPS_QBit_DriverPresence
      data DE_OPS_QBit_DriverPresence: type=boolean
    IF_ORU_AP_Mode
      data DE_ORU_AP_Mode: type=uint8
    IF_ORU_EM_Anfrage_Flashdauer
      data DE_ORU_EM_Anfrage_Flashdauer: type=uint16
    IF_ORU_EM_Anfrage_freigegebeneNetze
      data DE_ORU_EM_Anfrage_freigegebeneNetze: type=uint8
    IF_ORU_EM_Anfrage_Stromaufnahme
      data DE_ORU_EM_Anfrage_Stromaufnahme: type=uint16
    IF_ORU_Status
      data DE_ORU_Status: type=uint8
    IF_PCU_Adressinhalt
      data DE_PCU_Adressinhalt: type=uint8
    IF_PCU_Aussentemp_gef
      data DE_PCU_Aussentemp_gef: type=uint8
    IF_PCU_Betriebsstunden
      data DE_PCU_Betriebsstunden: type=uint16
    IF_PCU_Defekt
      data DE_PCU_Defekt: type=boolean
    IF_PCU_Ein
      data DE_PCU_Ein: type=uint8
    IF_PCU_Fehler_Emitter
      data DE_PCU_Fehler_Emitter: type=uint8
    IF_PCU_Fehler_Intern
      data DE_PCU_Fehler_Intern: type=uint8
    IF_PCU_FS_Luftfeuchte_rel
      data DE_PCU_FS_Luftfeuchte_rel: type=uint8
    IF_PCU_FSA_Luftfeuchte_rel
      data DE_PCU_FSA_Luftfeuchte_rel: type=uint8
    IF_PCU_Funktionstest
      data DE_PCU_Funktionstest: type=uint8
    IF_PCU_Geblaese_Status
      data DE_PCU_Geblaese_Status: type=uint8
    IF_PCU_I_Sec
      data DE_PCU_I_Sec: type=uint8
    IF_PCU_Innen_Temp
      data DE_PCU_Innen_Temp: type=uint8
    IF_PCU_Kennlinie
      data DE_PCU_Kennlinie: type=uint8
    IF_PCU_Polarisation
      data DE_PCU_Polarisation: type=boolean
    IF_PCU_ResponseError
      data DE_PCU_ResponseError: type=boolean
    IF_PCU_State_Polarisation
      data DE_PCU_State_Polarisation: type=boolean
    IF_PCU_Status
      data DE_PCU_Status: type=uint8
    IF_PCU_Status_LED
      data DE_PCU_Status_LED: type=boolean
    IF_PCU_Temp_PCB
      data DE_PCU_Temp_PCB: type=uint8
    IF_PCU_U_Sec
      data DE_PCU_U_Sec: type=uint16
    IF_PCU_Umluftklappe_Status
      data DE_PCU_Umluftklappe_Status: type=uint8
    IF_Perso_Aktiv
      data DE_Perso_Aktiv: type=boolean
    IF_Perso_Bedienstelle
      data DE_Perso_Bedienstelle: type=uint8
    IF_Perso_Fahrernummer
      data DE_Perso_Fahrernummer: type=uint8
    IF_Perso_Freigabe_Verstellung
      data DE_Perso_Freigabe_Verstellung: type=uint8
    IF_Perso_Kontonummer
      data DE_Perso_Kontonummer: type=uint8
    IF_Perso_Schreibschutz
      data DE_Perso_Schreibschutz: type=uint8
    IF_Perso_Status
      data DE_Perso_Status: type=uint8
    IF_Perso_Steuerung
      data DE_Perso_Steuerung: type=uint8
    IF_Perso_Steuerungsparameter
      data DE_Perso_Steuerungsparameter: type=uint8
    IF_PMS1_Partikel
      data DE_PMS1_Partikel: type=uint16
    IF_PMS1_ResponseError
      data DE_PMS1_ResponseError: type=boolean
    IF_PMS1_Status
      data DE_PMS1_Status: type=uint8
    IF_PSD_06_Mux
      data DE_PSD_06_Mux: type=uint8
    IF_PSD_Abzweigerichtung
      data DE_PSD_Abzweigerichtung: type=boolean
    IF_PSD_Abzweigewinkel
      data DE_PSD_Abzweigewinkel: type=uint8
    IF_PSD_ADAS_Qualitaet
      data DE_PSD_ADAS_Qualitaet: type=boolean
    IF_PSD_Anfangskruemmung
      data DE_PSD_Anfangskruemmung: type=uint8
    IF_PSD_Anfangskruemmung_Vorz
      data DE_PSD_Anfangskruemmung_Vorz: type=boolean
    IF_PSD_Attribut_1_ID
      data DE_PSD_Attribut_1_ID: type=uint8
    IF_PSD_Attribut_1_Offset
      data DE_PSD_Attribut_1_Offset: type=uint8
    IF_PSD_Attribut_1_Wert
      data DE_PSD_Attribut_1_Wert: type=uint8
    IF_PSD_Attribut_2_ID
      data DE_PSD_Attribut_2_ID: type=uint8
    IF_PSD_Attribut_2_Offset
      data DE_PSD_Attribut_2_Offset: type=uint8
    IF_PSD_Attribut_2_Wert
      data DE_PSD_Attribut_2_Wert: type=uint8
    IF_PSD_Attribut_3_ID
      data DE_PSD_Attribut_3_ID: type=uint8
    IF_PSD_Attribut_3_Offset
      data DE_PSD_Attribut_3_Offset: type=uint8
    IF_PSD_Attribut_3_Wert
      data DE_PSD_Attribut_3_Wert: type=uint8
    IF_PSD_Attribut_4_ID
      data DE_PSD_Attribut_4_ID: type=uint8
    IF_PSD_Attribut_4_Offset
      data DE_PSD_Attribut_4_Offset: type=uint8
    IF_PSD_Attribut_4_Wert
      data DE_PSD_Attribut_4_Wert: type=uint8
    IF_PSD_Attribut_5_ID
      data DE_PSD_Attribut_5_ID: type=uint8
    IF_PSD_Attribut_5_Offset
      data DE_PSD_Attribut_5_Offset: type=uint8
    IF_PSD_Attribut_5_Wert
      data DE_PSD_Attribut_5_Wert: type=uint8
    IF_PSD_Attribut_Segment_ID
      data DE_PSD_Attribut_Segment_ID: type=uint8
    IF_PSD_Attribut_Segment_ID_05
      data DE_PSD_Attribut_Segment_ID_05: type=uint8
    IF_PSD_Attribute_Komplett_05
      data DE_PSD_Attribute_Komplett_05: type=boolean
    IF_PSD_Attribute_Komplett_06
      data DE_PSD_Attribute_Komplett_06: type=boolean
    IF_PSD_Baum_Ausrichtung
      data DE_PSD_Baum_Ausrichtung: type=uint16
    IF_PSD_Baum_Breite_VZ
      data DE_PSD_Baum_Breite_VZ: type=boolean
    IF_PSD_Baum_Laenge
      data DE_PSD_Baum_Laenge: type=uint32
    IF_PSD_Baum_Laenge_VZ
      data DE_PSD_Baum_Laenge_VZ: type=boolean
    IF_PSD_Bebauung
      data DE_PSD_Bebauung: type=boolean
    IF_PSD_Endkruemmung
      data DE_PSD_Endkruemmung: type=uint8
    IF_PSD_Endkruemmung_Vorz
      data DE_PSD_Endkruemmung_Vorz: type=boolean
    IF_PSD_Fahrspuren_Anzahl
      data DE_PSD_Fahrspuren_Anzahl: type=uint8
    IF_PSD_Geradester_Pfad
      data DE_PSD_Geradester_Pfad: type=boolean
    IF_PSD_Ges_Attribute_Komplett
      data DE_PSD_Ges_Attribute_Komplett: type=boolean
    IF_PSD_Ges_Geschwindigkeit
      data DE_PSD_Ges_Geschwindigkeit: type=uint8
    IF_PSD_Ges_Geschwindigkeit_Gespann
      data DE_PSD_Ges_Geschwindigkeit_Gespann: type=uint8
    IF_PSD_Ges_Geschwindigkeit_Std_Anf
      data DE_PSD_Ges_Geschwindigkeit_Std_Anf: type=uint8
    IF_PSD_Ges_Geschwindigkeit_Std_Ende
      data DE_PSD_Ges_Geschwindigkeit_Std_Ende: type=uint8
    IF_PSD_Ges_Geschwindigkeit_Tag_Anf
      data DE_PSD_Ges_Geschwindigkeit_Tag_Anf: type=uint8
    IF_PSD_Ges_Geschwindigkeit_Tag_Ende
      data DE_PSD_Ges_Geschwindigkeit_Tag_Ende: type=uint8
    IF_PSD_Ges_Geschwindigkeit_Witter
      data DE_PSD_Ges_Geschwindigkeit_Witter: type=uint8
    IF_PSD_Ges_Gesetzlich_Kategorie
      data DE_PSD_Ges_Gesetzlich_Kategorie: type=uint8
    IF_PSD_Ges_Gesetzlich_Zusatz
      data DE_PSD_Ges_Gesetzlich_Zusatz: type=uint8
    IF_PSD_Ges_Offset
      data DE_PSD_Ges_Offset: type=uint8
    IF_PSD_Ges_Segment_ID
      data DE_PSD_Ges_Segment_ID: type=uint8
    IF_PSD_Ges_Spur_Geschw_Begrenzung
      data DE_PSD_Ges_Spur_Geschw_Begrenzung: type=uint8
    IF_PSD_Ges_Typ
      data DE_PSD_Ges_Typ: type=uint8
    IF_PSD_Ges_Ueberholverbot
      data DE_PSD_Ges_Ueberholverbot: type=uint8
    IF_PSD_Ges_Verkehrszeichen_Quelle
      data DE_PSD_Ges_Verkehrszeichen_Quelle: type=uint8
    IF_PSD_Ges_Wechselverkehrszeichen
      data DE_PSD_Ges_Wechselverkehrszeichen: type=uint8
    IF_PSD_Idenditaets_ID
      data DE_PSD_Idenditaets_ID: type=uint8
    IF_PSD_LR_01_MUX
      data DE_PSD_LR_01_MUX: type=uint8
    IF_PSD_LR_Attribut_1_Offset
      data DE_PSD_LR_Attribut_1_Offset: type=uint16
    IF_PSD_LR_Attribut_1_Wert
      data DE_PSD_LR_Attribut_1_Wert: type=uint8
    IF_PSD_LR_Attribut_2_Offset
      data DE_PSD_LR_Attribut_2_Offset: type=uint16
    IF_PSD_LR_Attribut_2_Wert
      data DE_PSD_LR_Attribut_2_Wert: type=uint8
    IF_PSD_LR_Attribut_3_Offset
      data DE_PSD_LR_Attribut_3_Offset: type=uint16
    IF_PSD_LR_Attribut_3_Wert
      data DE_PSD_LR_Attribut_3_Wert: type=uint8
    IF_PSD_LR_Fahrzeug_Pos
      data DE_PSD_LR_Fahrzeug_Pos: type=uint16
    IF_PSD_LR_Globale_Steigung
      data DE_PSD_LR_Globale_Steigung: type=uint32
    IF_PSD_LR_Globale_Steigung_Vorz
      data DE_PSD_LR_Globale_Steigung_Vorz: type=boolean
    IF_PSD_LR_Profil_Laenge
      data DE_PSD_LR_Profil_Laenge: type=uint16
    IF_PSD_LR_Profil_Nummer
      data DE_PSD_LR_Profil_Nummer: type=uint8
    IF_PSD_LR_Reset
      data DE_PSD_LR_Reset: type=boolean
    IF_PSD_LR_Steigung_1_Offset
      data DE_PSD_LR_Steigung_1_Offset: type=uint16
    IF_PSD_LR_Steigung_1_Vorz
      data DE_PSD_LR_Steigung_1_Vorz: type=boolean
    IF_PSD_LR_Steigung_1_Wert
      data DE_PSD_LR_Steigung_1_Wert: type=uint8
    IF_PSD_LR_Steigung_2_Offset
      data DE_PSD_LR_Steigung_2_Offset: type=uint16
    IF_PSD_LR_Steigung_2_Vorz
      data DE_PSD_LR_Steigung_2_Vorz: type=boolean
    IF_PSD_LR_Steigung_2_Wert
      data DE_PSD_LR_Steigung_2_Wert: type=uint8
    IF_PSD_LR_Steigung_3_Offset
      data DE_PSD_LR_Steigung_3_Offset: type=uint16
    IF_PSD_LR_Steigung_3_Vorz
      data DE_PSD_LR_Steigung_3_Vorz: type=boolean
    IF_PSD_LR_Steigung_3_Wert
      data DE_PSD_LR_Steigung_3_Wert: type=uint8
    IF_PSD_Pos_Fahrspur
      data DE_PSD_Pos_Fahrspur: type=uint8
    IF_PSD_Pos_Fehler_Laengsrichtung
      data DE_PSD_Pos_Fehler_Laengsrichtung: type=uint8
    IF_PSD_Pos_Inhibitzeit
      data DE_PSD_Pos_Inhibitzeit: type=uint8
    IF_PSD_Pos_Segment_ID
      data DE_PSD_Pos_Segment_ID: type=uint8
    IF_PSD_Pos_Segmentlaenge
      data DE_PSD_Pos_Segmentlaenge: type=uint8
    IF_PSD_Pos_Standort_Eindeutig
      data DE_PSD_Pos_Standort_Eindeutig: type=boolean
    IF_PSD_Rampe
      data DE_PSD_Rampe: type=uint8
    IF_PSD_Segment_ID
      data DE_PSD_Segment_ID: type=uint8
    IF_PSD_Segment_Komplett
      data DE_PSD_Segment_Komplett: type=boolean
    IF_PSD_Segmentlaenge
      data DE_PSD_Segmentlaenge: type=uint8
    IF_PSD_Steigung_1_A_Offset
      data DE_PSD_Steigung_1_A_Offset: type=uint8
    IF_PSD_Steigung_1_A_Steigung
      data DE_PSD_Steigung_1_A_Steigung: type=uint8
    IF_PSD_Steigung_1_A_Vorz
      data DE_PSD_Steigung_1_A_Vorz: type=boolean
    IF_PSD_Steigung_1_Attribute_kompl
      data DE_PSD_Steigung_1_Attribute_kompl: type=boolean
    IF_PSD_Steigung_1_B_Offset
      data DE_PSD_Steigung_1_B_Offset: type=uint8
    IF_PSD_Steigung_1_B_Steigung
      data DE_PSD_Steigung_1_B_Steigung: type=uint8
    IF_PSD_Steigung_1_B_Vorz
      data DE_PSD_Steigung_1_B_Vorz: type=boolean
    IF_PSD_Steigung_1_Segment_ID
      data DE_PSD_Steigung_1_Segment_ID: type=uint8
    IF_PSD_Steigung_2_Attribute_kompl
      data DE_PSD_Steigung_2_Attribute_kompl: type=boolean
    IF_PSD_Steigung_2_Offset
      data DE_PSD_Steigung_2_Offset: type=uint8
    IF_PSD_Steigung_2_Segment_ID
      data DE_PSD_Steigung_2_Segment_ID: type=uint8
    IF_PSD_Steigung_2_Steigung
      data DE_PSD_Steigung_2_Steigung: type=uint8
    IF_PSD_Steigung_2_Vorz
      data DE_PSD_Steigung_2_Vorz: type=boolean
    IF_PSD_Strassenkategorie
      data DE_PSD_Strassenkategorie: type=uint8
    IF_PSD_Sys_Alter_Karte
      data DE_PSD_Sys_Alter_Karte: type=uint8
    IF_PSD_Sys_Geometrieguete
      data DE_PSD_Sys_Geometrieguete: type=uint8
    IF_PSD_Sys_Geometrieguete_erweitert
      data DE_PSD_Sys_Geometrieguete_erweitert: type=uint8
    IF_PSD_Sys_Geschwindigkeit_Einheit
      data DE_PSD_Sys_Geschwindigkeit_Einheit: type=boolean
    IF_PSD_Sys_Laendercode
      data DE_PSD_Sys_Laendercode: type=uint8
    IF_PSD_Sys_Mapmatchingguete
      data DE_PSD_Sys_Mapmatchingguete: type=uint8
    IF_PSD_Sys_Quali_Geometrien
      data DE_PSD_Sys_Quali_Geometrien: type=uint8
    IF_PSD_Sys_Quali_Ortsinfo
      data DE_PSD_Sys_Quali_Ortsinfo: type=uint8
    IF_PSD_Sys_Quali_sonstige_Attribute
      data DE_PSD_Sys_Quali_sonstige_Attribute: type=uint8
    IF_PSD_Sys_Quali_Steigungen
      data DE_PSD_Sys_Quali_Steigungen: type=uint8
    IF_PSD_Sys_Quali_Strassenkennz
      data DE_PSD_Sys_Quali_Strassenkennz: type=uint8
    IF_PSD_Sys_Quali_Tempolimits
      data DE_PSD_Sys_Quali_Tempolimits: type=uint8
    IF_PSD_Sys_Quali_verfuegbar
      data DE_PSD_Sys_Quali_verfuegbar: type=boolean
    IF_PSD_Sys_Quali_Vorfahrtsregelung
      data DE_PSD_Sys_Quali_Vorfahrtsregelung: type=uint8
    IF_PSD_Sys_Segment_ID
      data DE_PSD_Sys_Segment_ID: type=uint8
    IF_PSD_Sys_US_State
      data DE_PSD_Sys_US_State: type=uint8
    IF_PSD_Sys_Verkehrsrichtung
      data DE_PSD_Sys_Verkehrsrichtung: type=boolean
    IF_PSD_Sys_Zielfuehrung
      data DE_PSD_Sys_Zielfuehrung: type=boolean
    IF_PSD_Sys_Zielfuehrung_geaendert
      data DE_PSD_Sys_Zielfuehrung_geaendert: type=boolean
    IF_PSD_Vorgaenger_Segment_ID
      data DE_PSD_Vorgaenger_Segment_ID: type=uint8
    IF_PSD_wahrscheinlichster_Pfad
      data DE_PSD_wahrscheinlichster_Pfad: type=boolean
    IF_PSD_Wechselverkehrszeichen_Typ
      data DE_PSD_Wechselverkehrszeichen_Typ: type=uint8
    IF_PTC_Aktiv
      data DE_PTC_Aktiv: type=boolean
    IF_PTC_Fehlerstatus
      data DE_PTC_Fehlerstatus: type=uint8
    IF_PTC_HV_ERR
      data DE_PTC_HV_ERR: type=uint8
    IF_PTC_HV_Err_Heizkreis_1
      data DE_PTC_HV_Err_Heizkreis_1: type=boolean
    IF_PTC_HV_Err_Heizkreis_1_TNCTOC
      data DE_PTC_HV_Err_Heizkreis_1_TNCTOC: type=boolean
    IF_PTC_HV_Err_Heizkreis_2
      data DE_PTC_HV_Err_Heizkreis_2: type=boolean
    IF_PTC_HV_Err_Heizkreis_2_TNCTOC
      data DE_PTC_HV_Err_Heizkreis_2_TNCTOC: type=boolean
    IF_PTC_HV_Err_Heizkreis_3
      data DE_PTC_HV_Err_Heizkreis_3: type=boolean
    IF_PTC_HV_Err_Heizkreis_3_TNCTOC
      data DE_PTC_HV_Err_Heizkreis_3_TNCTOC: type=boolean
    IF_PTC_HV_Err_intern
      data DE_PTC_HV_Err_intern: type=boolean
    IF_PTC_HV_Err_Intern_TNCTOC
      data DE_PTC_HV_Err_Intern_TNCTOC: type=boolean
    IF_PTC_HV_Err_Leckagestrom
      data DE_PTC_HV_Err_Leckagestrom: type=boolean
    IF_PTC_HV_Err_Leckagestrom_TNCTOC
      data DE_PTC_HV_Err_Leckagestrom_TNCTOC: type=boolean
    IF_PTC_HV_Err_Temperaturschutz
      data DE_PTC_HV_Err_Temperaturschutz: type=boolean
    IF_PTC_HV_Err_TempSchutz_TNCTOC
      data DE_PTC_HV_Err_TempSchutz_TNCTOC: type=boolean
    IF_PTC_HV_ERR_TNCTOC
      data DE_PTC_HV_ERR_TNCTOC: type=boolean
    IF_PTC_HV_Err_Ueberstromabs_TNCTOC
      data DE_PTC_HV_Err_Ueberstromabs_TNCTOC: type=boolean
    IF_PTC_HV_Err_Ueberstromabschaltung
      data DE_PTC_HV_Err_Ueberstromabschaltung: type=boolean
    IF_PTC_HV_Heizmedium_Sensor_1
      data DE_PTC_HV_Heizmedium_Sensor_1: type=uint8
    IF_PTC_HV_Heizmedium_Sensor_2
      data DE_PTC_HV_Heizmedium_Sensor_2: type=uint8
    IF_PTC_HV_I_ist
      data DE_PTC_HV_I_ist: type=uint8
    IF_PTC_HV_ResponseError
      data DE_PTC_HV_ResponseError: type=boolean
    IF_PTC_HV_Status_PTC
      data DE_PTC_HV_Status_PTC: type=uint8
    IF_PTC_HV_Status_UBatt
      data DE_PTC_HV_Status_UBatt: type=uint8
    IF_PTC_HV_Temp_PCB
      data DE_PTC_HV_Temp_PCB: type=uint8
    IF_PTC_HV_TimeOut_Fehler
      data DE_PTC_HV_TimeOut_Fehler: type=boolean
    IF_PTC_HV_UBatt
      data DE_PTC_HV_UBatt: type=uint8
    IF_PTC_HVb_ERR
      data DE_PTC_HVb_ERR: type=uint8
    IF_PTC_HVb_Err_Heizkreis_1
      data DE_PTC_HVb_Err_Heizkreis_1: type=boolean
    IF_PTC_HVb_Err_Heizkreis_1_TNCTOC
      data DE_PTC_HVb_Err_Heizkreis_1_TNCTOC: type=boolean
    IF_PTC_HVb_Err_Heizkreis_2
      data DE_PTC_HVb_Err_Heizkreis_2: type=boolean
    IF_PTC_HVb_Err_Heizkreis_2_TNCTOC
      data DE_PTC_HVb_Err_Heizkreis_2_TNCTOC: type=boolean
    IF_PTC_HVb_Err_Heizkreis_3
      data DE_PTC_HVb_Err_Heizkreis_3: type=boolean
    IF_PTC_HVb_Err_Heizkreis_3_TNCTOC
      data DE_PTC_HVb_Err_Heizkreis_3_TNCTOC: type=boolean
    IF_PTC_HVb_Err_intern
      data DE_PTC_HVb_Err_intern: type=boolean
    IF_PTC_HVb_Err_Intern_TNCTOC
      data DE_PTC_HVb_Err_Intern_TNCTOC: type=boolean
    IF_PTC_HVb_Err_Leckagestrom
      data DE_PTC_HVb_Err_Leckagestrom: type=boolean
    IF_PTC_HVb_Err_Leckagestrom_TNCTOC
      data DE_PTC_HVb_Err_Leckagestrom_TNCTOC: type=boolean
    IF_PTC_HVb_Err_Temperaturschutz
      data DE_PTC_HVb_Err_Temperaturschutz: type=boolean
    IF_PTC_HVb_Err_TempSchutz_TNCTOC
      data DE_PTC_HVb_Err_TempSchutz_TNCTOC: type=boolean
    IF_PTC_HVb_ERR_TNCTOC
      data DE_PTC_HVb_ERR_TNCTOC: type=boolean
    IF_PTC_HVb_Err_Ueberstromabs_TNCTOC
      data DE_PTC_HVb_Err_Ueberstromabs_TNCTOC: type=boolean
    IF_PTC_HVb_Err_Ueberstromabschaltung
      data DE_PTC_HVb_Err_Ueberstromabschaltung: type=boolean
    IF_PTC_HVb_Heizmedium_Sensor_1
      data DE_PTC_HVb_Heizmedium_Sensor_1: type=uint8
    IF_PTC_HVb_Heizmedium_Sensor_2
      data DE_PTC_HVb_Heizmedium_Sensor_2: type=uint8
    IF_PTC_HVb_I_ist
      data DE_PTC_HVb_I_ist: type=uint8
    IF_PTC_HVb_ResponseError
      data DE_PTC_HVb_ResponseError: type=boolean
    IF_PTC_HVb_Status_PTC
      data DE_PTC_HVb_Status_PTC: type=uint8
    IF_PTC_HVb_Status_UBatt
      data DE_PTC_HVb_Status_UBatt: type=uint8
    IF_PTC_HVb_Temp_PCB
      data DE_PTC_HVb_Temp_PCB: type=uint8
    IF_PTC_HVb_TimeOut_Fehler
      data DE_PTC_HVb_TimeOut_Fehler: type=boolean
    IF_PTC_HVb_UBatt
      data DE_PTC_HVb_UBatt: type=uint8
    IF_PTC_HW
      data DE_PTC_HW: type=uint8
    IF_PTC_I_ist
      data DE_PTC_I_ist: type=uint8
    IF_PTC_Nenn_Strom
      data DE_PTC_Nenn_Strom: type=uint8
    IF_PTC_P_ist
      data DE_PTC_P_ist: type=uint8
    IF_PTC_ResponseError
      data DE_PTC_ResponseError: type=boolean
    IF_PTC_Status
      data DE_PTC_Status: type=boolean
    IF_PTC_Status_PTC
      data DE_PTC_Status_PTC: type=uint8
    IF_PTC_Status_UBatt
      data DE_PTC_Status_UBatt: type=uint8
    IF_PTC_SW
      data DE_PTC_SW: type=uint8
    IF_PTC_Temp_PCB
      data DE_PTC_Temp_PCB: type=uint8
    IF_PTC_TimeOut_Fehler
      data DE_PTC_TimeOut_Fehler: type=boolean
    IF_PTC_UBatt
      data DE_PTC_UBatt: type=uint8
    IF_PTCs_01_alt
      data DE_PTCs_01_alt: type=boolean
    IF_RS_defekt
      data DE_RS_defekt: type=boolean
    IF_RS_Regenmenge
      data DE_RS_Regenmenge: type=uint8
    IF_RS_Wischergeschwindigkeit
      data DE_RS_Wischergeschwindigkeit: type=uint8
    IF_Scheibenreinigung
      data DE_Scheibenreinigung: type=boolean
    IF_SI_BUS_04
      data DE_SI_BUS_04: type=boolean
    IF_SI_CAB_V15
      data DE_SI_CAB_V15: type=uint32
    IF_SI_NWDF
      data DE_SI_NWDF: type=boolean
    IF_SI_NWDF_gueltig
      data DE_SI_NWDF_gueltig: type=boolean
    IF_SI_P_Mode
      data DE_SI_P_Mode: type=boolean
    IF_SI_P_Mode_gueltig
      data DE_SI_P_Mode_gueltig: type=boolean
    IF_SI_QRS_Mode
      data DE_SI_QRS_Mode: type=boolean
    IF_SI_T_Mode
      data DE_SI_T_Mode: type=boolean
    IF_SI_T_Schutz
      data DE_SI_T_Schutz: type=boolean
    IF_SIL_Stufe_LED_HL
      data DE_SIL_Stufe_LED_HL: type=uint8
    IF_SIL_Stufe_LED_HR
      data DE_SIL_Stufe_LED_HR: type=uint8
    IF_SIL_Stufe_LED_li
      data DE_SIL_Stufe_LED_li: type=uint8
    IF_SIL_Stufe_LED_re
      data DE_SIL_Stufe_LED_re: type=uint8
    IF_SMod_SIH_Stufe_hl
      data DE_SMod_SIH_Stufe_hl: type=uint8
    IF_SMod_SIH_Stufe_hr
      data DE_SMod_SIH_Stufe_hr: type=uint8
    IF_SMod_SIL_Stufe_hl
      data DE_SMod_SIL_Stufe_hl: type=uint8
    IF_SMod_SIL_Stufe_hr
      data DE_SMod_SIL_Stufe_hr: type=uint8
    IF_SMod_SRH_Fehler
      data DE_SMod_SRH_Fehler: type=boolean
    IF_SMod_SRH_ResponseError
      data DE_SMod_SRH_ResponseError: type=boolean
    IF_SOK_FoD_Klima_Req_Challenge
      data DE_SOK_FoD_Klima_Req_Challenge: type=uint64
    IF_SOK_FoD_Klima_Resp_Challenge
      data DE_SOK_FoD_Klima_Resp_Challenge: type=uint64
    IF_Soll_Lehne_LLR_li_1
      data DE_Soll_Lehne_LLR_li_1: type=uint8
    IF_Soll_Lehne_LLR_li_2
      data DE_Soll_Lehne_LLR_li_2: type=uint8
    IF_Soll_Lehne_LLR_re_1
      data DE_Soll_Lehne_LLR_re_1: type=uint8
    IF_Soll_Lehne_LLR_re_2
      data DE_Soll_Lehne_LLR_re_2: type=uint8
    IF_Soll_Sitz_LLR_li_1
      data DE_Soll_Sitz_LLR_li_1: type=uint8
    IF_Soll_Sitz_LLR_li_2
      data DE_Soll_Sitz_LLR_li_2: type=uint8
    IF_Soll_Sitz_LLR_re_1
      data DE_Soll_Sitz_LLR_re_1: type=uint8
    IF_Soll_Sitz_LLR_re_2
      data DE_Soll_Sitz_LLR_re_2: type=uint8
    IF_SoSe_SunInt_2D_Li
      data DE_SoSe_SunInt_2D_Li: type=uint8
    IF_SoSe_SunInt_2D_Re
      data DE_SoSe_SunInt_2D_Re: type=uint8
    IF_ST_VLD_BLW_CTRL_1_LIN
      data DE_ST_VLD_BLW_CTRL_1_LIN: type=boolean
    IF_ST_VLD_BLWb_CTRL_1_LIN
      data DE_ST_VLD_BLWb_CTRL_1_LIN: type=boolean
    IF_ST_VLD_BLWc_CTRL_1_LIN
      data DE_ST_VLD_BLWc_CTRL_1_LIN: type=boolean
    IF_STK_AirCLeaner_Anf
      data DE_STK_AirCLeaner_Anf: type=boolean
    IF_STK_Anf_AussenspiegelHZ
      data DE_STK_Anf_AussenspiegelHZ: type=boolean
    IF_STK_Berechnungsphase
      data DE_STK_Berechnungsphase: type=uint8
    IF_STK_Betriebsdauer
      data DE_STK_Betriebsdauer: type=uint8
    IF_STK_ErwVK_Anf
      data DE_STK_ErwVK_Anf: type=boolean
    IF_STK_ErwVK_Beifahrerzone
      data DE_STK_ErwVK_Beifahrerzone: type=boolean
    IF_STK_ErwVK_Fahrerzone
      data DE_STK_ErwVK_Fahrerzone: type=boolean
    IF_STK_ErwVK_Heckzone_links
      data DE_STK_ErwVK_Heckzone_links: type=boolean
    IF_STK_ErwVK_Heckzone_rechts
      data DE_STK_ErwVK_Heckzone_rechts: type=boolean
    IF_STK_ErwVK_Modus
      data DE_STK_ErwVK_Modus: type=uint8
    IF_STK_ErwVK_Scheibenheizung
      data DE_STK_ErwVK_Scheibenheizung: type=boolean
    IF_STK_FSH_Anf
      data DE_STK_FSH_Anf: type=boolean
    IF_STK_HSH_Anf
      data DE_STK_HSH_Anf: type=boolean
    IF_STK_Klima_Temp
      data DE_STK_Klima_Temp: type=uint8
    IF_STK_KurzVK_Anf
      data DE_STK_KurzVK_Anf: type=boolean
    IF_STK_Sofortstart_Sperre_FFB
      data DE_STK_Sofortstart_Sperre_FFB: type=boolean
    IF_STK_Standklima_Anf
      data DE_STK_Standklima_Anf: type=boolean
    IF_STK_Standklima_Timer_Status
      data DE_STK_Standklima_Timer_Status: type=boolean
    IF_STK_VK_Modus
      data DE_STK_VK_Modus: type=uint8
    IF_STRG1_Adresse_Aktuator
      data DE_STRG1_Adresse_Aktuator: type=uint8
    IF_STRG1_Geschwindigkeitsvorgabe
      data DE_STRG1_Geschwindigkeitsvorgabe: type=uint8
    IF_STRG1_Notlauffreigabe
      data DE_STRG1_Notlauffreigabe: type=uint8
    IF_STRG1_Select_Positionsvorgabe
      data DE_STRG1_Select_Positionsvorgabe: type=uint8
    IF_STRG1_Soll_Position_Aktuator
      data DE_STRG1_Soll_Position_Aktuator: type=uint16
    IF_STRG1_Spulenbestromung
      data DE_STRG1_Spulenbestromung: type=uint8
    IF_STRG4_Adresse_Aktuator
      data DE_STRG4_Adresse_Aktuator: type=uint8
    IF_STRG4_Clear_Event_Flags
      data DE_STRG4_Clear_Event_Flags: type=uint8
    IF_STRG4_Drehrichtung
      data DE_STRG4_Drehrichtung: type=uint8
    IF_STRG4_Freigabe_Blockiererkennung
      data DE_STRG4_Freigabe_Blockiererkennung: type=uint8
    IF_STRG4_Geschwindigkeitsvorgabe
      data DE_STRG4_Geschwindigkeitsvorgabe: type=uint8
    IF_STRG4_Notlauffreigabe
      data DE_STRG4_Notlauffreigabe: type=uint8
    IF_STRG4_Notlaufposition
      data DE_STRG4_Notlaufposition: type=uint8
    IF_STRG4_Programmierdaten_speichern
      data DE_STRG4_Programmierdaten_speichern: type=uint8
    IF_STRG4_Select_Positionsvorgabe
      data DE_STRG4_Select_Positionsvorgabe: type=uint8
    IF_STRG4_Soll_Position_Aktuator
      data DE_STRG4_Soll_Position_Aktuator: type=uint16
    IF_STRG4_Spulenbestromung
      data DE_STRG4_Spulenbestromung: type=uint8
    IF_STRG4_Start_Position_Aktuator
      data DE_STRG4_Start_Position_Aktuator: type=uint16
    IF_STRG4_Stopmodus
      data DE_STRG4_Stopmodus: type=uint8
    IF_Thermo_Pred_Innen_Kunde_Anf
      data DE_Thermo_Pred_Innen_Kunde_Anf: type=uint8
    IF_Thermo_Pred_Innen_System_Anf
      data DE_Thermo_Pred_Innen_System_Anf: type=uint8
    IF_Thermo_Pred_P_dyn_In_Efficien1
      data DE_Thermo_Pred_P_dyn_In_Efficien1: type=uint16
    IF_Thermo_Pred_P_dyn_In_Efficien2
      data DE_Thermo_Pred_P_dyn_In_Efficien2: type=uint16
    IF_Thermo_Pred_P_dyn_In_Standard
      data DE_Thermo_Pred_P_dyn_In_Standard: type=uint16
    IF_Thermo_Pred_P_dyn_Innen
      data DE_Thermo_Pred_P_dyn_Innen: type=uint16
    IF_Thermo_Pred_P_stat_In_Efficien1
      data DE_Thermo_Pred_P_stat_In_Efficien1: type=uint16
    IF_Thermo_Pred_P_stat_In_Efficien2
      data DE_Thermo_Pred_P_stat_In_Efficien2: type=uint16
    IF_Thermo_Pred_P_stat_In_Standard
      data DE_Thermo_Pred_P_stat_In_Standard: type=uint16
    IF_Thermo_Pred_P_stat_Innen
      data DE_Thermo_Pred_P_stat_Innen: type=uint16
    IF_Thermo_Pred_T_dyn_In_Efficien1
      data DE_Thermo_Pred_T_dyn_In_Efficien1: type=uint8
    IF_Thermo_Pred_T_dyn_In_Efficien2
      data DE_Thermo_Pred_T_dyn_In_Efficien2: type=uint8
    IF_Thermo_Pred_T_dyn_In_Standard
      data DE_Thermo_Pred_T_dyn_In_Standard: type=uint8
    IF_Thermo_Pred_T_dyn_Innen
      data DE_Thermo_Pred_T_dyn_Innen: type=uint8
    IF_Thermo_Verbrauch_BTL
      data DE_Thermo_Verbrauch_BTL: type=uint16
    IF_Thermo_Verbrauch_BTL_Ueberlauf
      data DE_Thermo_Verbrauch_BTL_Ueberlauf: type=boolean
    IF_Thermo_Verbrauch_Innen
      data DE_Thermo_Verbrauch_Innen: type=uint16
    IF_Thermo_Verbrauch_Innen_Ueberlauf
      data DE_Thermo_Verbrauch_Innen_Ueberlauf: type=boolean
    IF_TSK_QBit_Steigung
      data DE_TSK_QBit_Steigung: type=boolean
    IF_TSK_Steigung_02
      data DE_TSK_Steigung_02: type=uint8
    IF_UH_Jahr
      data DE_UH_Jahr: type=uint8
    IF_UH_Minute
      data DE_UH_Minute: type=uint8
    IF_UH_Monat
      data DE_UH_Monat: type=uint8
    IF_UH_Sekunde
      data DE_UH_Sekunde: type=uint8
    IF_UH_Stunde
      data DE_UH_Stunde: type=uint8
    IF_UH_Tag
      data DE_UH_Tag: type=uint8
    IF_UIF_Itos_roh
      data DE_UIF_Itos_roh: type=uint16
    IF_UIF_Ref_roh
      data DE_UIF_Ref_roh: type=uint16
    IF_UIF_ResponseError
      data DE_UIF_ResponseError: type=boolean
    IF_UIF_Status
      data DE_UIF_Status: type=uint8
    IF_UIF_Sun_roh
      data DE_UIF_Sun_roh: type=uint16
    IF_UIF_SunInt
      data DE_UIF_SunInt: type=uint8
    IF_UIF_Temp_OutOfRange
      data DE_UIF_Temp_OutOfRange: type=uint8
    IF_UIF_Temperatur
      data DE_UIF_Temperatur: type=uint16
    IF_Umluft
      data DE_Umluft: type=uint8
    IF_Vehicle_Driving_Cycle
      data DE_Vehicle_Driving_Cycle: type=boolean
    IF_Verbauposition_LLR_li
      data DE_Verbauposition_LLR_li: type=boolean
    IF_Verbauposition_LLR_re
      data DE_Verbauposition_LLR_re: type=boolean
    IF_VIN_01_MUX
      data DE_VIN_01_MUX: type=uint8
    IF_VIN_1
      data DE_VIN_1: type=uint8
    IF_VIN_10
      data DE_VIN_10: type=uint8
    IF_VIN_11
      data DE_VIN_11: type=uint8
    IF_VIN_12
      data DE_VIN_12: type=uint8
    IF_VIN_13
      data DE_VIN_13: type=uint8
    IF_VIN_14
      data DE_VIN_14: type=uint8
    IF_VIN_15
      data DE_VIN_15: type=uint8
    IF_VIN_16
      data DE_VIN_16: type=uint8
    IF_VIN_17
      data DE_VIN_17: type=uint8
    IF_VIN_2
      data DE_VIN_2: type=uint8
    IF_VIN_3
      data DE_VIN_3: type=uint8
    IF_VIN_4
      data DE_VIN_4: type=uint8
    IF_VIN_5
      data DE_VIN_5: type=uint8
    IF_VIN_6
      data DE_VIN_6: type=uint8
    IF_VIN_7
      data DE_VIN_7: type=uint8
    IF_VIN_8
      data DE_VIN_8: type=uint8
    IF_VIN_9
      data DE_VIN_9: type=uint8
    IF_Waschen_vorne_aktiv
      data DE_Waschen_vorne_aktiv: type=boolean
    IF_Wischer1_Wischgeschwindigkeit
      data DE_Wischer1_Wischgeschwindigkeit: type=uint8
    IF_Wischer_vorne_aktiv
      data DE_Wischer_vorne_aktiv: type=boolean
    IF_Wischer_vorne_defekt
      data DE_Wischer_vorne_defekt: type=boolean
    IF_ZAS_Kl_15
      data DE_ZAS_Kl_15: type=boolean
    IF_ZAS_Kl_S
      data DE_ZAS_Kl_S: type=boolean
    IF_ZM_Standzeit
      data DE_ZM_Standzeit: type=uint32
    IF_ZV_BT_offen
      data DE_ZV_BT_offen: type=boolean
    IF_ZV_FT_offen
      data DE_ZV_FT_offen: type=boolean
    IF_ZV_gesafet_extern_ist
      data DE_ZV_gesafet_extern_ist: type=boolean
    IF_ZV_HBFS_offen
      data DE_ZV_HBFS_offen: type=boolean
    IF_ZV_HD_offen
      data DE_ZV_HD_offen: type=boolean
    IF_ZV_HFS_offen
      data DE_ZV_HFS_offen: type=boolean
    IF_ZV_Schluessel_Zugang
      data DE_ZV_Schluessel_Zugang: type=uint8
    IF_ZV_verriegelt_extern_ist
      data DE_ZV_verriegelt_extern_ist: type=boolean
    IF_ZV_verriegelt_extern_soll
      data DE_ZV_verriegelt_extern_soll: type=boolean
    IF_ZV_verriegelt_intern_ist
      data DE_ZV_verriegelt_intern_ist: type=boolean
    IF_ZV_verriegelt_intern_soll
      data DE_ZV_verriegelt_intern_soll: type=boolean
package /ComponentTypes
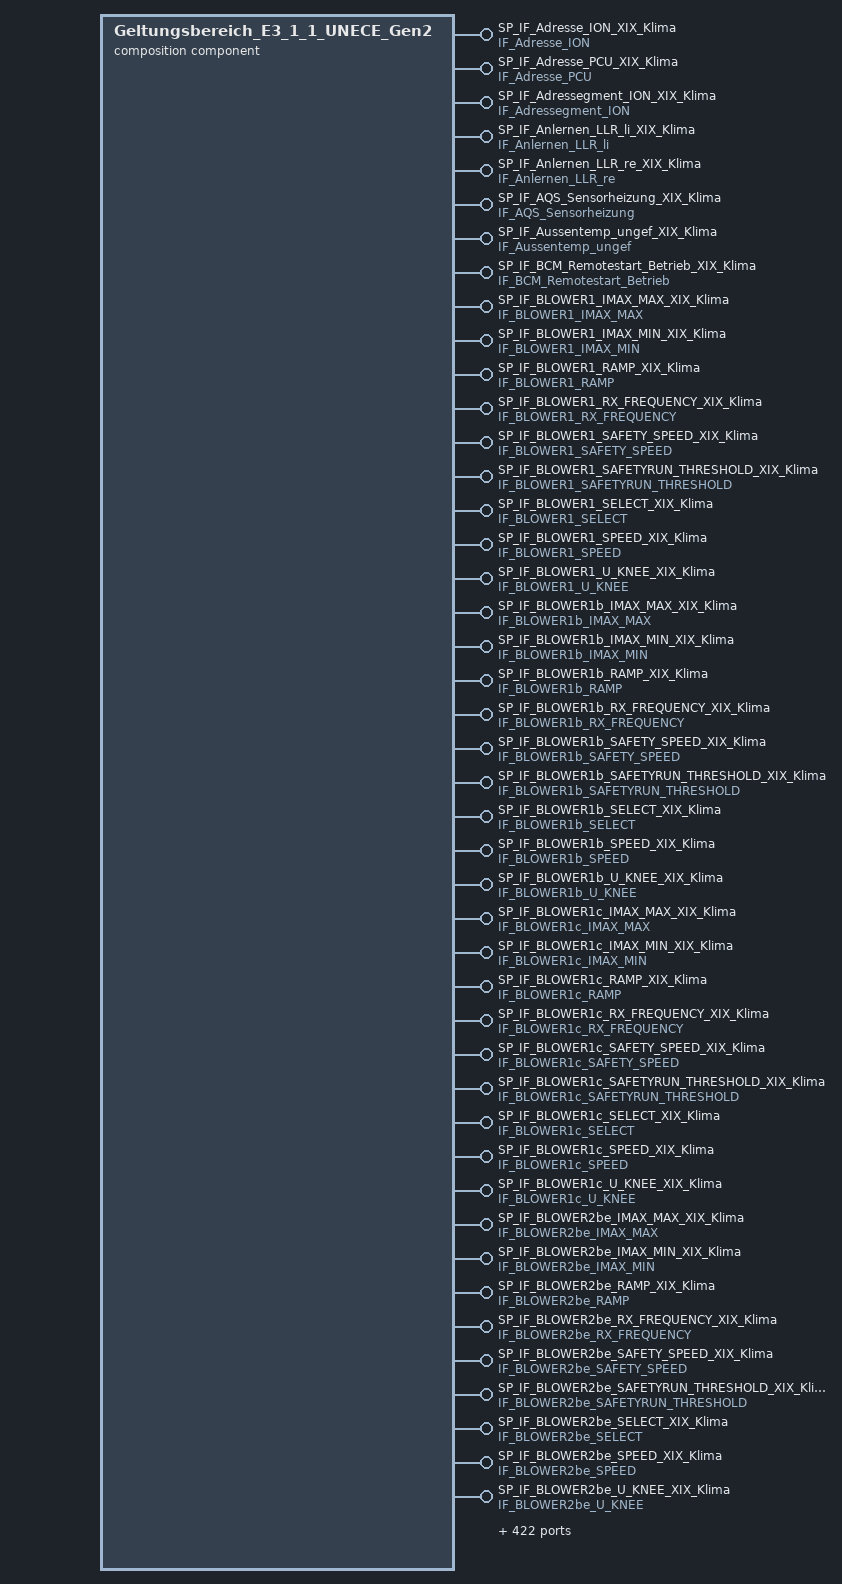
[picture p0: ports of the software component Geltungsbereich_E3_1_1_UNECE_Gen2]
  composition sw component type Geltungsbereich_E3_1_1_UNECE_Gen2
    473 x provide port:
      SP_IF_Adresse_ION_XIX_Klima: provided-interface=IF_Adresse_ION
      SP_IF_Adresse_PCU_XIX_Klima: provided-interface=IF_Adresse_PCU
      SP_IF_Adressegment_ION_XIX_Klima: provided-interface=IF_Adressegment_ION
      SP_IF_Anlernen_LLR_li_XIX_Klima: provided-interface=IF_Anlernen_LLR_li
      SP_IF_Anlernen_LLR_re_XIX_Klima: provided-interface=IF_Anlernen_LLR_re
      SP_IF_AQS_Sensorheizung_XIX_Klima: provided-interface=IF_AQS_Sensorheizung
      SP_IF_Aussentemp_ungef_XIX_Klima: provided-interface=IF_Aussentemp_ungef
      SP_IF_BCM_Remotestart_Betrieb_XIX_Klima: provided-interface=IF_BCM_Remotestart_Betrieb
      SP_IF_BLOWER1_IMAX_MAX_XIX_Klima: provided-interface=IF_BLOWER1_IMAX_MAX
      SP_IF_BLOWER1_IMAX_MIN_XIX_Klima: provided-interface=IF_BLOWER1_IMAX_MIN
      SP_IF_BLOWER1_RAMP_XIX_Klima: provided-interface=IF_BLOWER1_RAMP
      SP_IF_BLOWER1_RX_FREQUENCY_XIX_Klima: provided-interface=IF_BLOWER1_RX_FREQUENCY
      SP_IF_BLOWER1_SAFETY_SPEED_XIX_Klima: provided-interface=IF_BLOWER1_SAFETY_SPEED
      SP_IF_BLOWER1_SAFETYRUN_THRESHOLD_XIX_Klima: provided-interface=IF_BLOWER1_SAFETYRUN_THRESHOLD
      SP_IF_BLOWER1_SELECT_XIX_Klima: provided-interface=IF_BLOWER1_SELECT
      SP_IF_BLOWER1_SPEED_XIX_Klima: provided-interface=IF_BLOWER1_SPEED
      SP_IF_BLOWER1_U_KNEE_XIX_Klima: provided-interface=IF_BLOWER1_U_KNEE
      SP_IF_BLOWER1b_IMAX_MAX_XIX_Klima: provided-interface=IF_BLOWER1b_IMAX_MAX
      SP_IF_BLOWER1b_IMAX_MIN_XIX_Klima: provided-interface=IF_BLOWER1b_IMAX_MIN
      SP_IF_BLOWER1b_RAMP_XIX_Klima: provided-interface=IF_BLOWER1b_RAMP
      SP_IF_BLOWER1b_RX_FREQUENCY_XIX_Klima: provided-interface=IF_BLOWER1b_RX_FREQUENCY
      SP_IF_BLOWER1b_SAFETY_SPEED_XIX_Klima: provided-interface=IF_BLOWER1b_SAFETY_SPEED
      SP_IF_BLOWER1b_SAFETYRUN_THRESHOLD_XIX_Klima: provided-interface=IF_BLOWER1b_SAFETYRUN_THRESHOLD
      SP_IF_BLOWER1b_SELECT_XIX_Klima: provided-interface=IF_BLOWER1b_SELECT
      SP_IF_BLOWER1b_SPEED_XIX_Klima: provided-interface=IF_BLOWER1b_SPEED
      SP_IF_BLOWER1b_U_KNEE_XIX_Klima: provided-interface=IF_BLOWER1b_U_KNEE
      SP_IF_BLOWER1c_IMAX_MAX_XIX_Klima: provided-interface=IF_BLOWER1c_IMAX_MAX
      SP_IF_BLOWER1c_IMAX_MIN_XIX_Klima: provided-interface=IF_BLOWER1c_IMAX_MIN
      SP_IF_BLOWER1c_RAMP_XIX_Klima: provided-interface=IF_BLOWER1c_RAMP
      SP_IF_BLOWER1c_RX_FREQUENCY_XIX_Klima: provided-interface=IF_BLOWER1c_RX_FREQUENCY
      SP_IF_BLOWER1c_SAFETY_SPEED_XIX_Klima: provided-interface=IF_BLOWER1c_SAFETY_SPEED
      SP_IF_BLOWER1c_SAFETYRUN_THRESHOLD_XIX_Klima: provided-interface=IF_BLOWER1c_SAFETYRUN_THRESHOLD
      SP_IF_BLOWER1c_SELECT_XIX_Klima: provided-interface=IF_BLOWER1c_SELECT
      SP_IF_BLOWER1c_SPEED_XIX_Klima: provided-interface=IF_BLOWER1c_SPEED
      SP_IF_BLOWER1c_U_KNEE_XIX_Klima: provided-interface=IF_BLOWER1c_U_KNEE
      SP_IF_BLOWER2be_IMAX_MAX_XIX_Klima: provided-interface=IF_BLOWER2be_IMAX_MAX
      SP_IF_BLOWER2be_IMAX_MIN_XIX_Klima: provided-interface=IF_BLOWER2be_IMAX_MIN
      SP_IF_BLOWER2be_RAMP_XIX_Klima: provided-interface=IF_BLOWER2be_RAMP
      SP_IF_BLOWER2be_RX_FREQUENCY_XIX_Klima: provided-interface=IF_BLOWER2be_RX_FREQUENCY
      SP_IF_BLOWER2be_SAFETY_SPEED_XIX_Klima: provided-interface=IF_BLOWER2be_SAFETY_SPEED
      SP_IF_BLOWER2be_SAFETYRUN_THRESHOLD_XIX_Klima: provided-interface=IF_BLOWER2be_SAFETYRUN_THRESHOLD
      SP_IF_BLOWER2be_SELECT_XIX_Klima: provided-interface=IF_BLOWER2be_SELECT
      SP_IF_BLOWER2be_SPEED_XIX_Klima: provided-interface=IF_BLOWER2be_SPEED
      SP_IF_BLOWER2be_U_KNEE_XIX_Klima: provided-interface=IF_BLOWER2be_U_KNEE
      SP_IF_BLOWER2e_IMAX_MAX_XIX_Klima: provided-interface=IF_BLOWER2e_IMAX_MAX
      SP_IF_BLOWER2e_IMAX_MIN_XIX_Klima: provided-interface=IF_BLOWER2e_IMAX_MIN
      SP_IF_BLOWER2e_RAMP_XIX_Klima: provided-interface=IF_BLOWER2e_RAMP
      SP_IF_BLOWER2e_RX_FREQUENCY_XIX_Klima: provided-interface=IF_BLOWER2e_RX_FREQUENCY
      SP_IF_BLOWER2e_SAFETY_SPEED_XIX_Klima: provided-interface=IF_BLOWER2e_SAFETY_SPEED
      SP_IF_BLOWER2e_SAFETYRUN_THRESHOLD_XIX_Klima: provided-interface=IF_BLOWER2e_SAFETYRUN_THRESHOLD
      SP_IF_BLOWER2e_SELECT_XIX_Klima: provided-interface=IF_BLOWER2e_SELECT
      SP_IF_BLOWER2e_SPEED_XIX_Klima: provided-interface=IF_BLOWER2e_SPEED
      SP_IF_BLOWER2e_U_KNEE_XIX_Klima: provided-interface=IF_BLOWER2e_U_KNEE
      SP_IF_BT_FH_Oeffnung_4Bit_XIX_Klima: provided-interface=IF_BT_FH_Oeffnung_4Bit
      SP_IF_DI_KL_58xd_XIX_Klima: provided-interface=IF_DI_KL_58xd
      SP_IF_DI_KL_58xs_XIX_Klima: provided-interface=IF_DI_KL_58xs
      SP_IF_DS_Kaeltemittel_P_WP_XIX_Klima: provided-interface=IF_DS_Kaeltemittel_P_WP
      SP_IF_EKK_Active_Discharge_XIX_Klima: provided-interface=IF_EKK_Active_Discharge
      SP_IF_EKK_ENB_COMP_XIX_Klima: provided-interface=IF_EKK_ENB_COMP
      SP_IF_EKK_HV_ST_XIX_Klima: provided-interface=IF_EKK_HV_ST
      SP_IF_EKK_KL_15_Status_XIX_Klima: provided-interface=IF_EKK_KL_15_Status
      SP_IF_EKK_REQ_COMP_SPEED_HiRes_XIX_Klima: provided-interface=IF_EKK_REQ_COMP_SPEED_HiRes
      SP_IF_EKK_REQ_COMP_SPEED_XIX_Klima: provided-interface=IF_EKK_REQ_COMP_SPEED
      SP_IF_EKKe_Error_Mask_Nr_XIX_Klima: provided-interface=IF_EKKe_Error_Mask_Nr
      SP_IF_EKKe_Level_REQ_XIX_Klima: provided-interface=IF_EKKe_Level_REQ
      SP_IF_EKKe_Q_Mask_XIX_Klima: provided-interface=IF_EKKe_Q_Mask
      SP_IF_Empfindlichkeit_AQS_XIX_Klima: provided-interface=IF_Empfindlichkeit_AQS
      SP_IF_ESP_v_Signal_8Bit_XIX_Klima: provided-interface=IF_ESP_v_Signal_8Bit
      SP_IF_FCM_01_alt_XIX_Klima: provided-interface=IF_FCM_01_alt
      SP_IF_FRS_ChannelSelect_XIX_Klima: provided-interface=IF_FRS_ChannelSelect
      SP_IF_FRS_IntensityReq_XIX_Klima: provided-interface=IF_FRS_IntensityReq
      SP_IF_FRS_Status_Car_XIX_Klima: provided-interface=IF_FRS_Status_Car
      SP_IF_FSA_Luftfeuchte_rel_XIX_Klima: provided-interface=IF_FSA_Luftfeuchte_rel
      SP_IF_FSA_Taupunkt_PMS_XIX_Klima: provided-interface=IF_FSA_Taupunkt_PMS
      SP_IF_FSH_Status_XIX_Klima: provided-interface=IF_FSH_Status
      SP_IF_FSH_Taster_XIX_Klima: provided-interface=IF_FSH_Taster
      SP_IF_FT_FH_Oeffnung_4Bit_XIX_Klima: provided-interface=IF_FT_FH_Oeffnung_4Bit
      SP_IF_Geblaesestufe_XIX_Klima: provided-interface=IF_Geblaesestufe
      SP_IF_HBFS_FH_Oeffnung_4Bit_XIX_Klima: provided-interface=IF_HBFS_FH_Oeffnung_4Bit
      SP_IF_HFS_FH_Oeffnung_4Bit_XIX_Klima: provided-interface=IF_HFS_FH_Oeffnung_4Bit
      SP_IF_HLR_SIH_Freigabe_Fond_XIX_Klima: provided-interface=IF_HLR_SIH_Freigabe_Fond
      SP_IF_HSH_Relais_Anf_XIX_Klima: provided-interface=IF_HSH_Relais_Anf
      SP_IF_HSH_Taster_XIX_Klima: provided-interface=IF_HSH_Taster
      SP_IF_HV_H3be_Geblaesedrehzahl_XIX_Klima: provided-interface=IF_HV_H3be_Geblaesedrehzahl
      SP_IF_HV_H3be_Heizer_ein_XIX_Klima: provided-interface=IF_HV_H3be_Heizer_ein
      SP_IF_HV_H3be_Heizer_links_soll_XIX_Klima: provided-interface=IF_HV_H3be_Heizer_links_soll
      SP_IF_HV_H3be_Heizer_Mitte_soll_XIX_Klima: provided-interface=IF_HV_H3be_Heizer_Mitte_soll
      SP_IF_HV_H3be_Heizer_rechts_soll_XIX_Klima: provided-interface=IF_HV_H3be_Heizer_rechts_soll
      SP_IF_HV_H3be_Heizgaskuehler_XIX_Klima: provided-interface=IF_HV_H3be_Heizgaskuehler
      SP_IF_HV_H3be_Heizsystem_XIX_Klima: provided-interface=IF_HV_H3be_Heizsystem
      SP_IF_HV_H3be_PTC_Zonenanzahl_XIX_Klima: provided-interface=IF_HV_H3be_PTC_Zonenanzahl
      SP_IF_HV_H3be_Tempklappenwinkel_li_XIX_Klima: provided-interface=IF_HV_H3be_Tempklappenwinkel_li
      SP_IF_HV_H3be_Tempklappenwinkel_mi_XIX_Klima: provided-interface=IF_HV_H3be_Tempklappenwinkel_mi
      SP_IF_HV_H3be_Tempklappenwinkel_re_XIX_Klima: provided-interface=IF_HV_H3be_Tempklappenwinkel_re
      SP_IF_HV_H3be_Verdampfertemp_Delta_XIX_Klima: provided-interface=IF_HV_H3be_Verdampfertemp_Delta
      SP_IF_HV_H3be_Verdampfertemp_min_XIX_Klima: provided-interface=IF_HV_H3be_Verdampfertemp_min
      SP_IF_HV_H3e_Geblaesedrehzahl_XIX_Klima: provided-interface=IF_HV_H3e_Geblaesedrehzahl
      SP_IF_HV_H3e_Heizer_ein_XIX_Klima: provided-interface=IF_HV_H3e_Heizer_ein
      SP_IF_HV_H3e_Heizer_links_soll_XIX_Klima: provided-interface=IF_HV_H3e_Heizer_links_soll
      SP_IF_HV_H3e_Heizer_Mitte_soll_XIX_Klima: provided-interface=IF_HV_H3e_Heizer_Mitte_soll
      SP_IF_HV_H3e_Heizer_rechts_soll_XIX_Klima: provided-interface=IF_HV_H3e_Heizer_rechts_soll
      SP_IF_HV_H3e_Heizgaskuehler_XIX_Klima: provided-interface=IF_HV_H3e_Heizgaskuehler
      SP_IF_HV_H3e_Heizsystem_XIX_Klima: provided-interface=IF_HV_H3e_Heizsystem
      SP_IF_HV_H3e_PTC_Zonenanzahl_XIX_Klima: provided-interface=IF_HV_H3e_PTC_Zonenanzahl
      SP_IF_HV_H3e_Tempklappenwinkel_li_XIX_Klima: provided-interface=IF_HV_H3e_Tempklappenwinkel_li
      SP_IF_HV_H3e_Tempklappenwinkel_mi_XIX_Klima: provided-interface=IF_HV_H3e_Tempklappenwinkel_mi
      SP_IF_HV_H3e_Tempklappenwinkel_re_XIX_Klima: provided-interface=IF_HV_H3e_Tempklappenwinkel_re
      SP_IF_HV_H3e_Verdampfertemp_Delta_XIX_Klima: provided-interface=IF_HV_H3e_Verdampfertemp_Delta
      SP_IF_HV_H3e_Verdampfertemp_min_XIX_Klima: provided-interface=IF_HV_H3e_Verdampfertemp_min
      SP_IF_ICO2_Luftdruck_2_XIX_Klima: provided-interface=IF_ICO2_Luftdruck_2
      SP_IF_ICO2_Messvorgabe_XIX_Klima: provided-interface=IF_ICO2_Messvorgabe
      SP_IF_ICO2_Messzyklus1_XIX_Klima: provided-interface=IF_ICO2_Messzyklus1
      SP_IF_ICO2_Messzyklus2_XIX_Klima: provided-interface=IF_ICO2_Messzyklus2
      SP_IF_ICO2_Status_Kabine_XIX_Klima: provided-interface=IF_ICO2_Status_Kabine
      SP_IF_ICO2b_Luftdruck_2_XIX_Klima: provided-interface=IF_ICO2b_Luftdruck_2
      SP_IF_ICO2b_Messvorgabe_XIX_Klima: provided-interface=IF_ICO2b_Messvorgabe
      SP_IF_ICO2b_Messzyklus1_XIX_Klima: provided-interface=IF_ICO2b_Messzyklus1
      SP_IF_ICO2b_Messzyklus2_XIX_Klima: provided-interface=IF_ICO2b_Messzyklus2
      SP_IF_ICO2b_Status_Kabine_XIX_Klima: provided-interface=IF_ICO2b_Status_Kabine
      SP_IF_ION_0e_Dummy_XIX_Klima: provided-interface=IF_ION_0e_Dummy
      SP_IF_ISOALLReqB{0..7}_XIX_Klima: provided-interface=IF_ISOALLReqB{0..7}
      SP_IF_KBT_CODE_VEHICLE_XIX_Klima: provided-interface=IF_KBT_CODE_VEHICLE
      SP_IF_KBT_Defrost_aktiv_XIX_Klima: provided-interface=IF_KBT_Defrost_aktiv
      SP_IF_KBT_RAMP_XIX_Klima: provided-interface=IF_KBT_RAMP
      SP_IF_KBT_RX_FREQUENCY_XIX_Klima: provided-interface=IF_KBT_RX_FREQUENCY
      SP_IF_KBT_SAFETY_SPEED_XIX_Klima: provided-interface=IF_KBT_SAFETY_SPEED
      SP_IF_KBT_SPEED_XIX_Klima: provided-interface=IF_KBT_SPEED
      SP_IF_KL_AC_Schalter_XIX_Klima: provided-interface=IF_KL_AC_Schalter
      SP_IF_KL_ActiveDischarge_XIX_Klima: provided-interface=IF_KL_ActiveDischarge
      SP_IF_KL_AirCleaner_aktiv_XIX_Klima: provided-interface=IF_KL_AirCleaner_aktiv
      SP_IF_KL_Ak_Verd_hi_li_XIX_Klima: provided-interface=IF_KL_Ak_Verd_hi_li
      SP_IF_KL_Ak_Verd_hi_re_XIX_Klima: provided-interface=IF_KL_Ak_Verd_hi_re
      SP_IF_KL_Ak_Verd_hinten_XIX_Klima: provided-interface=IF_KL_Ak_Verd_hinten
      SP_IF_KL_Ak_Verd_links_XIX_Klima: provided-interface=IF_KL_Ak_Verd_links
      SP_IF_KL_Ak_Verd_rechts_XIX_Klima: provided-interface=IF_KL_Ak_Verd_rechts
      SP_IF_KL_Ak_Verd_vo_li_XIX_Klima: provided-interface=IF_KL_Ak_Verd_vo_li
      SP_IF_KL_Ak_Verd_vo_re_XIX_Klima: provided-interface=IF_KL_Ak_Verd_vo_re
      SP_IF_KL_Ak_Verd_vorne_XIX_Klima: provided-interface=IF_KL_Ak_Verd_vorne
      SP_IF_KL_AL_HL_Anf_XIX_Klima: provided-interface=IF_KL_AL_HL_Anf
      SP_IF_KL_AL_HR_Anf_XIX_Klima: provided-interface=IF_KL_AL_HR_Anf
      SP_IF_KL_AL_VL_Anf_XIX_Klima: provided-interface=IF_KL_AL_VL_Anf
      SP_IF_KL_AL_VR_Anf_XIX_Klima: provided-interface=IF_KL_AL_VR_Anf
      SP_IF_KL_Anf_AussenspiegelHzg_XIX_Klima: provided-interface=IF_KL_Anf_AussenspiegelHzg
      SP_IF_KL_Anf_KL_XIX_Klima: provided-interface=IF_KL_Anf_KL
      SP_IF_KL_Anf_KV_XIX_Klima: provided-interface=IF_KL_Anf_KV
      SP_IF_KL_Anf_rLM_XIX_Klima: provided-interface=IF_KL_Anf_rLM
      SP_IF_KL_Anz_auto_hl_XIX_Klima: provided-interface=IF_KL_Anz_auto_hl
      SP_IF_KL_Anz_Geblaese_hl_XIX_Klima: provided-interface=IF_KL_Anz_Geblaese_hl
      SP_IF_KL_Anz_mitte_hl_XIX_Klima: provided-interface=IF_KL_Anz_mitte_hl
      SP_IF_KL_Anz_oben_hl_XIX_Klima: provided-interface=IF_KL_Anz_oben_hl
      SP_IF_KL_Anz_seite_defog_hl_XIX_Klima: provided-interface=IF_KL_Anz_seite_defog_hl
      SP_IF_KL_Anz_seite_hl_XIX_Klima: provided-interface=IF_KL_Anz_seite_hl
      SP_IF_KL_Anz_Temp_Einheit_XIX_Klima: provided-interface=IF_KL_Anz_Temp_Einheit
      SP_IF_KL_Anz_Temp_hl_XIX_Klima: provided-interface=IF_KL_Anz_Temp_hl
      SP_IF_KL_Anz_Temp_hr_XIX_Klima: provided-interface=IF_KL_Anz_Temp_hr
      SP_IF_KL_Anz_unten_hl_XIX_Klima: provided-interface=IF_KL_Anz_unten_hl
      SP_IF_KL_AQI_Innenraum_XIX_Klima: provided-interface=IF_KL_AQI_Innenraum
      SP_IF_KL_Ausstattung_Klima_XIX_Klima: provided-interface=IF_KL_Ausstattung_Klima
      SP_IF_KL_Batterieheizen_Freigabe_XIX_Klima: provided-interface=IF_KL_Batterieheizen_Freigabe
      SP_IF_KL_BCmE_Livetip_Freigabe_XIX_Klima: provided-interface=IF_KL_BCmE_Livetip_Freigabe
      SP_IF_KL_Beschlagsgefahr_XIX_Klima: provided-interface=IF_KL_Beschlagsgefahr
      SP_IF_KL_Charisma_FahrPr_XIX_Klima: provided-interface=IF_KL_Charisma_FahrPr
      SP_IF_KL_Charisma_Status_XIX_Klima: provided-interface=IF_KL_Charisma_Status
      SP_IF_KL_Defrost_LED_XIX_Klima: provided-interface=IF_KL_Defrost_LED
      SP_IF_KL_Drehz_Anh_XIX_Klima: provided-interface=IF_KL_Drehz_Anh
      SP_IF_KL_Einheiten_XIX_Klima: provided-interface=IF_KL_Einheiten
      SP_IF_KL_EKK_Strom_XIX_Klima: provided-interface=IF_KL_EKK_Strom
      SP_IF_KL_el_Zuheizer_Stufe_XIX_Klima: provided-interface=IF_KL_el_Zuheizer_Stufe
      SP_IF_KL_Enteisung_Anf_XIX_Klima: provided-interface=IF_KL_Enteisung_Anf
      SP_IF_KL_ErwVK_Anf_XIX_Klima: provided-interface=IF_KL_ErwVK_Anf
      SP_IF_KL_ErwVK_Beifahrerzone_XIX_Klima: provided-interface=IF_KL_ErwVK_Beifahrerzone
      SP_IF_KL_ErwVK_Fahrerzone_XIX_Klima: provided-interface=IF_KL_ErwVK_Fahrerzone
      SP_IF_KL_ErwVK_Heckzone_links_XIX_Klima: provided-interface=IF_KL_ErwVK_Heckzone_links
      SP_IF_Kl_ErwVK_Heckzone_rechts_XIX_Klima: provided-interface=IF_Kl_ErwVK_Heckzone_rechts
      SP_IF_KL_ErwVK_Scheibenheizung_XIX_Klima: provided-interface=IF_KL_ErwVK_Scheibenheizung
      SP_IF_KL_ErwVK_Status_XIX_Klima: provided-interface=IF_KL_ErwVK_Status
      SP_IF_KL_eTM_SollVolumenstrom_XIX_Klima: provided-interface=IF_KL_eTM_SollVolumenstrom
      SP_IF_KL_Fehler_HV_EKK_XIX_Klima: provided-interface=IF_KL_Fehler_HV_EKK
      SP_IF_KL_Fehler_HV_Heizer_XIX_Klima: provided-interface=IF_KL_Fehler_HV_Heizer
      SP_IF_KL_Fehler_NTKreis_XIX_Klima: provided-interface=IF_KL_Fehler_NTKreis
      SP_IF_KL_Fondbedienung_aktiv_XIX_Klima: provided-interface=IF_KL_Fondbedienung_aktiv
      SP_IF_KL_Freilauf_Info_XIX_Klima: provided-interface=IF_KL_Freilauf_Info
      SP_IF_KL_FSH_Automatikbetrieb_XIX_Klima: provided-interface=IF_KL_FSH_Automatikbetrieb
      SP_IF_KL_FSH_LED_XIX_Klima: provided-interface=IF_KL_FSH_LED
      SP_IF_KL_FSH_Soll_XIX_Klima: provided-interface=IF_KL_FSH_Soll
      SP_IF_KL_Geblaese_Fond_Status_XIX_Klima: provided-interface=IF_KL_Geblaese_Fond_Status
      SP_IF_KL_Geblaese_Status_XIX_Klima: provided-interface=IF_KL_Geblaese_Status
      SP_IF_KL_Geblspng_Fond_Soll_XIX_Klima: provided-interface=IF_KL_Geblspng_Fond_Soll
      SP_IF_KL_Geblspng_Soll_XIX_Klima: provided-interface=IF_KL_Geblspng_Soll
      SP_IF_KL_HBT_Geblaesestufe_anzeigen_XIX_Klima: provided-interface=IF_KL_HBT_Geblaesestufe_anzeigen
      SP_IF_KL_HBT_Verbausituation_XIX_Klima: provided-interface=IF_KL_HBT_Verbausituation
      SP_IF_KL_Heizbedarf_Anf_XIX_Klima: provided-interface=IF_KL_Heizbedarf_Anf
      SP_IF_KL_Heizbedarf_XIX_Klima: provided-interface=IF_KL_Heizbedarf
      SP_IF_KL_Heizen_Status_XIX_Klima: provided-interface=IF_KL_Heizen_Status
      SP_IF_KL_Heizkreisventilstellung_XIX_Klima: provided-interface=IF_KL_Heizkreisventilstellung
      SP_IF_KL_Heizstufe_LSH_XIX_Klima: provided-interface=IF_KL_Heizstufe_LSH
      SP_IF_KL_HSH_LED_XIX_Klima: provided-interface=IF_KL_HSH_LED
      SP_IF_KL_HSH_Soll_XIX_Klima: provided-interface=IF_KL_HSH_Soll
      SP_IF_KL_HUP_aktiv_XIX_Klima: provided-interface=IF_KL_HUP_aktiv
      SP_IF_KL_HV_Energie_Anf_XIX_Klima: provided-interface=IF_KL_HV_Energie_Anf
      SP_IF_KL_HV_H6_aktive_Entladung_XIX_Klima: provided-interface=IF_KL_HV_H6_aktive_Entladung
      SP_IF_KL_HV_H6_Durchflussrichtung_XIX_Klima: provided-interface=IF_KL_HV_H6_Durchflussrichtung
      SP_IF_KL_HV_H6_ein_XIX_Klima: provided-interface=IF_KL_HV_H6_ein
      SP_IF_KL_HV_H6_soll_XIX_Klima: provided-interface=IF_KL_HV_H6_soll
      SP_IF_KL_HV_Hb_ein_XIX_Klima: provided-interface=IF_KL_HV_Hb_ein
      SP_IF_KL_HV_Hb_soll_XIX_Klima: provided-interface=IF_KL_HV_Hb_soll
      SP_IF_KL_HV_Heizer_Strom_XIX_Klima: provided-interface=IF_KL_HV_Heizer_Strom
      SP_IF_KL_HV_PTC_ein_XIX_Klima: provided-interface=IF_KL_HV_PTC_ein
      SP_IF_KL_HV_PTC_soll_XIX_Klima: provided-interface=IF_KL_HV_PTC_soll
      SP_IF_KL_HVH_1_VerbautStatus_XIX_Klima: provided-interface=IF_KL_HVH_1_VerbautStatus
      SP_IF_KL_HVH_2_Status_Spgfreiheit_XIX_Klima: provided-interface=IF_KL_HVH_2_Status_Spgfreiheit
      SP_IF_KL_HVH_2_VerbautStatus_XIX_Klima: provided-interface=IF_KL_HVH_2_VerbautStatus
      SP_IF_KL_HVH_3_VerbautStatus_XIX_Klima: provided-interface=IF_KL_HVH_3_VerbautStatus
      SP_IF_KL_HVHeizer2_ein_XIX_Klima: provided-interface=IF_KL_HVHeizer2_ein
      SP_IF_KL_HVHeizer2_soll_XIX_Klima: provided-interface=IF_KL_HVHeizer2_soll
      SP_IF_KL_HWT_Sollvolumenstrom_XIX_Klima: provided-interface=IF_KL_HWT_Sollvolumenstrom
      SP_IF_KL_I_Geblaese_Fond_XIX_Klima: provided-interface=IF_KL_I_Geblaese_Fond
      SP_IF_KL_I_Geblaese_XIX_Klima: provided-interface=IF_KL_I_Geblaese
      SP_IF_KL_Innen_Temp_XIX_Klima: provided-interface=IF_KL_Innen_Temp
      SP_IF_KL_Innentemp_KBT_Sensor_XIX_Klima: provided-interface=IF_KL_Innentemp_KBT_Sensor
      SP_IF_KL_Ionisator_XIX_Klima: provided-interface=IF_KL_Ionisator
      SP_IF_KL_IstLeistung_XIX_Klima: provided-interface=IF_KL_IstLeistung
      SP_IF_KL_K_Status_XIX_Klima: provided-interface=IF_KL_K_Status
      SP_IF_KL_KBF_Sync_XIX_Klima: provided-interface=IF_KL_KBF_Sync
      SP_IF_KL_KD_Fehler_XIX_Klima: provided-interface=IF_KL_KD_Fehler
      SP_IF_KL_Kennlinie_XIX_Klima: provided-interface=IF_KL_Kennlinie
      SP_IF_KL_Klappe_Status_XIX_Klima: provided-interface=IF_KL_Klappe_Status
      SP_IF_KL_KLE_Fehler_Anf_XIX_Klima: provided-interface=IF_KL_KLE_Fehler_Anf
      SP_IF_KL_KLh_aus_XIX_Klima: provided-interface=IF_KL_KLh_aus
      SP_IF_KL_KLh_LastMode_XIX_Klima: provided-interface=IF_KL_KLh_LastMode
      SP_IF_KL_KLh_lock_XIX_Klima: provided-interface=IF_KL_KLh_lock
      SP_IF_Kl_Klima_Aktiv_XIX_Klima: provided-interface=IF_Kl_Klima_Aktiv
      SP_IF_KL_Klimastandzeit_XIX_Klima: provided-interface=IF_KL_Klimastandzeit
      SP_IF_KL_Komp_Moment_alt_XIX_Klima: provided-interface=IF_KL_Komp_Moment_alt
      SP_IF_KL_Kompressorstrom_soll_XIX_Klima: provided-interface=IF_KL_Kompressorstrom_soll
      SP_IF_KL_Kuehlungs_Status_XIX_Klima: provided-interface=IF_KL_Kuehlungs_Status
      SP_IF_KL_Kundenwunsch_Kuehlen_XIX_Klima: provided-interface=IF_KL_Kundenwunsch_Kuehlen
      SP_IF_KL_Last_Kompr_XIX_Klima: provided-interface=IF_KL_Last_Kompr
      SP_IF_KL_Leistung_BattHeizung_XIX_Klima: provided-interface=IF_KL_Leistung_BattHeizung
      SP_IF_KL_Leistung_Klima_Anf_XIX_Klima: provided-interface=IF_KL_Leistung_Klima_Anf
      SP_IF_KL_LRH_FoD_Status_XIX_Klima: provided-interface=IF_KL_LRH_FoD_Status
      SP_IF_KL_LRH_PWM_XIX_Klima: provided-interface=IF_KL_LRH_PWM
      SP_IF_KL_LRH_Soll_XIX_Klima: provided-interface=IF_KL_LRH_Soll
      SP_IF_KL_LRH_Stufe_XIX_Klima: provided-interface=IF_KL_LRH_Stufe
      SP_IF_KL_LRH_Taster_XIX_Klima: provided-interface=IF_KL_LRH_Taster
      SP_IF_KL_LSH_Ansteuerung_XIX_Klima: provided-interface=IF_KL_LSH_Ansteuerung
      SP_IF_KL_LSH_Betriebsdauer_XIX_Klima: provided-interface=IF_KL_LSH_Betriebsdauer
      SP_IF_KL_LSH_DBetr_Bestaet_XIX_Klima: provided-interface=IF_KL_LSH_DBetr_Bestaet
      SP_IF_KL_LSH_DBetr_Ein_XIX_Klima: provided-interface=IF_KL_LSH_DBetr_Ein
      SP_IF_KL_Magnetventil_XIX_Klima: provided-interface=IF_KL_Magnetventil
      SP_IF_KL_Meldung_Status_XIX_Klima: provided-interface=IF_KL_Meldung_Status
      SP_IF_KL_nachtr_Stopp_Anf_XIX_Klima: provided-interface=IF_KL_nachtr_Stopp_Anf
      SP_IF_KL_OBD_Status_XIX_Klima: provided-interface=IF_KL_OBD_Status
      SP_IF_KL_PTC_ein_XIX_Klima: provided-interface=IF_KL_PTC_ein
      SP_IF_KL_PTC_Rampe_XIX_Klima: provided-interface=IF_KL_PTC_Rampe
      SP_IF_KL_PTC_soll_XIX_Klima: provided-interface=IF_KL_PTC_soll
      SP_IF_KL_PTC_Verbauinfo_XIX_Klima: provided-interface=IF_KL_PTC_Verbauinfo
      SP_IF_KL_Pumpe_02_Soll_XIX_Klima: provided-interface=IF_KL_Pumpe_02_Soll
      SP_IF_KL_Reheat_Innenraum_XIX_Klima: provided-interface=IF_KL_Reheat_Innenraum
      SP_IF_KL_Restwaerme_aktiv_XIX_Klima: provided-interface=IF_KL_Restwaerme_aktiv
      SP_IF_KL_Scheibe_Typ_XIX_Klima: provided-interface=IF_KL_Scheibe_Typ
      SP_IF_KL_SDA_Luft_Feinstaub_XIX_Klima: provided-interface=IF_KL_SDA_Luft_Feinstaub
      SP_IF_KL_SH_Soll_hl_XIX_Klima: provided-interface=IF_KL_SH_Soll_hl
      SP_IF_KL_SH_Soll_hr_XIX_Klima: provided-interface=IF_KL_SH_Soll_hr
      SP_IF_KL_SIH_Anforderung_hl_XIX_Klima: provided-interface=IF_KL_SIH_Anforderung_hl
      SP_IF_KL_SIH_Anforderung_hr_XIX_Klima: provided-interface=IF_KL_SIH_Anforderung_hr
      SP_IF_KL_SIH_hl_Leistung_XIX_Klima: provided-interface=IF_KL_SIH_hl_Leistung
      SP_IF_KL_SIH_hl_Temp_aus_XIX_Klima: provided-interface=IF_KL_SIH_hl_Temp_aus
      SP_IF_KL_SIH_hl_Temp_ein_XIX_Klima: provided-interface=IF_KL_SIH_hl_Temp_ein
      SP_IF_KL_SIH_hl_Vorgabe_XIX_Klima: provided-interface=IF_KL_SIH_hl_Vorgabe
      SP_IF_KL_SIH_hr_Leistung_XIX_Klima: provided-interface=IF_KL_SIH_hr_Leistung
      SP_IF_KL_SIH_hr_Temp_aus_XIX_Klima: provided-interface=IF_KL_SIH_hr_Temp_aus
      SP_IF_KL_SIH_hr_Temp_ein_XIX_Klima: provided-interface=IF_KL_SIH_hr_Temp_ein
      SP_IF_KL_SIH_hr_Vorgabe_XIX_Klima: provided-interface=IF_KL_SIH_hr_Vorgabe
      SP_IF_KL_SIH_LEL_Verteilung_VL_XIX_Klima: provided-interface=IF_KL_SIH_LEL_Verteilung_VL
      SP_IF_KL_SIH_LEL_Verteilung_VR_XIX_Klima: provided-interface=IF_KL_SIH_LEL_Verteilung_VR
      SP_IF_KL_SIH_Soll_li_XIX_Klima: provided-interface=IF_KL_SIH_Soll_li
      SP_IF_KL_SIH_Soll_re_XIX_Klima: provided-interface=IF_KL_SIH_Soll_re
      SP_IF_KL_SIL_Soll_li_XIX_Klima: provided-interface=IF_KL_SIL_Soll_li
      SP_IF_KL_SIL_Soll_re_XIX_Klima: provided-interface=IF_KL_SIL_Soll_re
      SP_IF_KL_Sitzkennlinie_Heck_XIX_Klima: provided-interface=IF_KL_Sitzkennlinie_Heck
      SP_IF_KL_SMod_SIH_Stufe_LED_hl_XIX_Klima: provided-interface=IF_KL_SMod_SIH_Stufe_LED_hl
      SP_IF_KL_SMod_SIH_Stufe_LED_hr_XIX_Klima: provided-interface=IF_KL_SMod_SIH_Stufe_LED_hr
      SP_IF_KL_SMod_SIL_Stufe_LED_hl_XIX_Klima: provided-interface=IF_KL_SMod_SIL_Stufe_LED_hl
      SP_IF_KL_SMod_SIL_Stufe_LED_hr_XIX_Klima: provided-interface=IF_KL_SMod_SIL_Stufe_LED_hr
      SP_IF_KL_SoSe_Intensitaet_BFS_XIX_Klima: provided-interface=IF_KL_SoSe_Intensitaet_BFS
      SP_IF_KL_SoSe_Intensitaet_FS_XIX_Klima: provided-interface=IF_KL_SoSe_Intensitaet_FS
      SP_IF_KL_Spannungs_Anf_XIX_Klima: provided-interface=IF_KL_Spannungs_Anf
      SP_IF_KL_Standklima_RemoteModus_XIX_Klima: provided-interface=IF_KL_Standklima_RemoteModus
      SP_IF_KL_Standklima_Status_02_XIX_Klima: provided-interface=IF_KL_Standklima_Status_02
      SP_IF_KL_Standklima_Status_03_XIX_Klima: provided-interface=IF_KL_Standklima_Status_03
      SP_IF_KL_StartStopp_Info_XIX_Klima: provided-interface=IF_KL_StartStopp_Info
      SP_IF_KL_Status_EoHVL_EKK_XIX_Klima: provided-interface=IF_KL_Status_EoHVL_EKK
      SP_IF_KL_Status_EoHVL_Heizer_2_XIX_Klima: provided-interface=IF_KL_Status_EoHVL_Heizer_2
      SP_IF_KL_Status_EoHVL_Heizer_3_XIX_Klima: provided-interface=IF_KL_Status_EoHVL_Heizer_3
      SP_IF_KL_Status_EoHVL_Heizer_XIX_Klima: provided-interface=IF_KL_Status_EoHVL_Heizer
      SP_IF_KL_Status_Soll_XIX_Klima: provided-interface=IF_KL_Status_Soll
      SP_IF_KL_StellgliedtestINV_Heck_XIX_Klima: provided-interface=IF_KL_StellgliedtestINV_Heck
      SP_IF_KL_STH_aktiv_XIX_Klima: provided-interface=IF_KL_STH_aktiv
      SP_IF_KL_STH_Ansteuerung_XIX_Klima: provided-interface=IF_KL_STH_Ansteuerung
      SP_IF_KL_STH_Betriebsdauer_XIX_Klima: provided-interface=IF_KL_STH_Betriebsdauer
      SP_IF_KL_STL_aktiv_XIX_Klima: provided-interface=IF_KL_STL_aktiv
      SP_IF_KL_T_Charge_XIX_Klima: provided-interface=IF_KL_T_Charge
      SP_IF_KL_Temp_HL_Soll_XIX_Klima: provided-interface=IF_KL_Temp_HL_Soll
      SP_IF_KL_Temp_vor_NTK_XIX_Klima: provided-interface=IF_KL_Temp_vor_NTK
      SP_IF_KL_Temp_ZH_Soll_XIX_Klima: provided-interface=IF_KL_Temp_ZH_Soll
      SP_IF_KL_Thermomanagement_XIX_Klima: provided-interface=IF_KL_Thermomanagement
      SP_IF_KL_UIF_Parametersatz_XIX_Klima: provided-interface=IF_KL_UIF_Parametersatz
      SP_IF_KL_Umluft_Taste_XIX_Klima: provided-interface=IF_KL_Umluft_Taste
      SP_IF_KL_Umluftklappe_Status_XIX_Klima: provided-interface=IF_KL_Umluftklappe_Status
      SP_IF_KL_Variante_Standheizung_XIX_Klima: provided-interface=IF_KL_Variante_Standheizung
      SP_IF_KL_Verdeckstatus_XIX_Klima: provided-interface=IF_KL_Verdeckstatus
      SP_IF_KL_VK_Anf_XIX_Klima: provided-interface=IF_KL_VK_Anf
      SP_IF_KL_VK_Betriebsdauer_XIX_Klima: provided-interface=IF_KL_VK_Betriebsdauer
      SP_IF_KL_VoKo_LED_XIX_Klima: provided-interface=IF_KL_VoKo_LED
      SP_IF_KL_Voko_Status_XIX_Klima: provided-interface=IF_KL_Voko_Status
      SP_IF_KL_Vorkond_Strategie_XIX_Klima: provided-interface=IF_KL_Vorkond_Strategie
      SP_IF_KL_Vorwarn_Komp_ein_XIX_Klima: provided-interface=IF_KL_Vorwarn_Komp_ein
      SP_IF_KL_Vorwarn_Zuheizer_ein_XIX_Klima: provided-interface=IF_KL_Vorwarn_Zuheizer_ein
      SP_IF_KL_WaPu_XIX_Klima: provided-interface=IF_KL_WaPu
      SP_IF_KL_Wasserheizer_Ansteuerung_XIX_Klima: provided-interface=IF_KL_Wasserheizer_Ansteuerung
      SP_IF_KL_Wasserheizer_IstTemp_Ausgang_XIX_Klima: provided-interface=IF_KL_Wasserheizer_IstTemp_Ausgang
      SP_IF_KL_Wasserheizer_IstTemp_Eingang_XIX_Klima: provided-interface=IF_KL_Wasserheizer_IstTemp_Eingang
      SP_IF_KL_Wasserheizer_SollTemp_Ausgang_XIX_Klima: provided-interface=IF_KL_Wasserheizer_SollTemp_Ausgang
      SP_IF_KL_Wasserheizer_Status_XIX_Klima: provided-interface=IF_KL_Wasserheizer_Status
      SP_IF_KL_ZR_Anforderung_XIX_Klima: provided-interface=IF_KL_ZR_Anforderung
      SP_IF_KL_Zuheizer_Freigabe_XIX_Klima: provided-interface=IF_KL_Zuheizer_Freigabe
      SP_IF_KL_Zustand_XIX_Klima: provided-interface=IF_KL_Zustand
      SP_IF_Klemme_15_XIX_Klima: provided-interface=IF_Klemme_15
      SP_IF_Klima_Nachlauftyp_XIX_Klima: provided-interface=IF_Klima_Nachlauftyp
      SP_IF_KN_KL_DiagPfad_XIX_Klima: provided-interface=IF_KN_KL_DiagPfad
      SP_IF_KompressorModus_XIX_Klima: provided-interface=IF_KompressorModus
      SP_IF_KPVe_Auto_Toggle_XIX_Klima: provided-interface=IF_KPVe_Auto_Toggle
      SP_IF_KPVe_Einheit_XIX_Klima: provided-interface=IF_KPVe_Einheit
      SP_IF_KPVe_Funktion_AC_max_XIX_Klima: provided-interface=IF_KPVe_Funktion_AC_max
      SP_IF_KPVe_Funktion_AC_XIX_Klima: provided-interface=IF_KPVe_Funktion_AC
      SP_IF_KPVe_Funktion_Auto_li_XIX_Klima: provided-interface=IF_KPVe_Funktion_Auto_li
      SP_IF_KPVe_Funktion_AutoSiKli_li_XIX_Klima: provided-interface=IF_KPVe_Funktion_AutoSiKli_li
      SP_IF_KPVe_Funktion_AutoSiKli_re_XIX_Klima: provided-interface=IF_KPVe_Funktion_AutoSiKli_re
      SP_IF_KPVe_Funktion_AutoUmluft_XIX_Klima: provided-interface=IF_KPVe_Funktion_AutoUmluft
      SP_IF_KPVe_Funktion_Beduftung_XIX_Klima: provided-interface=IF_KPVe_Funktion_Beduftung
      SP_IF_KPVe_Funktion_Defrost_XIX_Klima: provided-interface=IF_KPVe_Funktion_Defrost
      SP_IF_KPVe_Funktion_ECO_XIX_Klima: provided-interface=IF_KPVe_Funktion_ECO
      SP_IF_KPVe_Funktion_ECO_Zone_XIX_Klima: provided-interface=IF_KPVe_Funktion_ECO_Zone
      SP_IF_KPVe_Funktion_FSH_XIX_Klima: provided-interface=IF_KPVe_Funktion_FSH
      SP_IF_KPVe_Funktion_HSH_XIX_Klima: provided-interface=IF_KPVe_Funktion_HSH
      SP_IF_KPVe_Funktion_Ionisator_XIX_Klima: provided-interface=IF_KPVe_Funktion_Ionisator
      SP_IF_KPVe_Funktion_Joker_Taste_XIX_Klima: provided-interface=IF_KPVe_Funktion_Joker_Taste
      SP_IF_KPVe_Funktion_Klima_Menue_MMI_XIX_Klima: provided-interface=IF_KPVe_Funktion_Klima_Menue_MMI
      SP_IF_KPVe_Funktion_Konditionierung_XIX_Klima: provided-interface=IF_KPVe_Funktion_Konditionierung
      SP_IF_KPVe_Funktion_Locked_XIX_Klima: provided-interface=IF_KPVe_Funktion_Locked
      SP_IF_KPVe_Funktion_OBD_XIX_Klima: provided-interface=IF_KPVe_Funktion_OBD
      SP_IF_KPVe_Funktion_Off_XIX_Klima: provided-interface=IF_KPVe_Funktion_Off
      SP_IF_KPVe_Funktion_PureAir_XIX_Klima: provided-interface=IF_KPVe_Funktion_PureAir
      SP_IF_KPVe_Funktion_Rear_XIX_Klima: provided-interface=IF_KPVe_Funktion_Rear
      SP_IF_KPVe_Funktion_Restwaerme_XIX_Klima: provided-interface=IF_KPVe_Funktion_Restwaerme
      SP_IF_KPVe_Funktion_Sync_XIX_Klima: provided-interface=IF_KPVe_Funktion_Sync
      SP_IF_KPVe_Funktion_Umluft_XIX_Klima: provided-interface=IF_KPVe_Funktion_Umluft
      SP_IF_KPVe_Funktionsbeleuchtung_XIX_Klima: provided-interface=IF_KPVe_Funktionsbeleuchtung
      SP_IF_KPVe_Geblaese_Auto_li_XIX_Klima: provided-interface=IF_KPVe_Geblaese_Auto_li
      SP_IF_KPVe_Geblaese_Begrenzung_XIX_Klima: provided-interface=IF_KPVe_Geblaese_Begrenzung
      SP_IF_KPVe_Geblaese_Stufe_li_XIX_Klima: provided-interface=IF_KPVe_Geblaese_Stufe_li
      SP_IF_KPVe_Kopfraumheizung_li_XIX_Klima: provided-interface=IF_KPVe_Kopfraumheizung_li
      SP_IF_KPVe_Kopfraumheizung_re_XIX_Klima: provided-interface=IF_KPVe_Kopfraumheizung_re
      SP_IF_KPVe_LCD_XIX_Klima: provided-interface=IF_KPVe_LCD
      SP_IF_KPVe_Lenker_Position_XIX_Klima: provided-interface=IF_KPVe_Lenker_Position
      SP_IF_KPVe_Luftverteilung_Auto_li_XIX_Klima: provided-interface=IF_KPVe_Luftverteilung_Auto_li
      SP_IF_KPVe_Luftverteilung_Mitte_li_XIX_Klima: provided-interface=IF_KPVe_Luftverteilung_Mitte_li
      SP_IF_KPVe_Luftverteilung_Oben_li_XIX_Klima: provided-interface=IF_KPVe_Luftverteilung_Oben_li
      SP_IF_KPVe_Luftverteilung_Unten_li_XIX_Klima: provided-interface=IF_KPVe_Luftverteilung_Unten_li
      SP_IF_KPVe_OBD_Gruppe_XIX_Klima: provided-interface=IF_KPVe_OBD_Gruppe
      SP_IF_KPVe_Sitzheizung_li_XIX_Klima: provided-interface=IF_KPVe_Sitzheizung_li
      SP_IF_KPVe_Sitzheizung_re_XIX_Klima: provided-interface=IF_KPVe_Sitzheizung_re
      SP_IF_KPVe_Sitzlueftung_li_XIX_Klima: provided-interface=IF_KPVe_Sitzlueftung_li
      SP_IF_KPVe_Sitzlueftung_re_XIX_Klima: provided-interface=IF_KPVe_Sitzlueftung_re
      SP_IF_KPVe_Suchbeleuchtung_XIX_Klima: provided-interface=IF_KPVe_Suchbeleuchtung
      SP_IF_KPVe_Symbol_Luftmenge_li_XIX_Klima: provided-interface=IF_KPVe_Symbol_Luftmenge_li
      SP_IF_KPVe_Symbol_Luftverteilung_li_XIX_Klima: provided-interface=IF_KPVe_Symbol_Luftverteilung_li
      SP_IF_KPVe_Temp_li_XIX_Klima: provided-interface=IF_KPVe_Temp_li
      SP_IF_KPVe_Temp_re_XIX_Klima: provided-interface=IF_KPVe_Temp_re
      SP_IF_KPVe_Verbau_AutoSikli_XIX_Klima: provided-interface=IF_KPVe_Verbau_AutoSikli
      SP_IF_KRH_Soll_li_XIX_Klima: provided-interface=IF_KRH_Soll_li
      SP_IF_KRH_Soll_re_XIX_Klima: provided-interface=IF_KRH_Soll_re
      SP_IF_LHRe_01_AnsteuerVorgabe_A_XIX_Klima: provided-interface=IF_LHRe_01_AnsteuerVorgabe_A
      SP_IF_LHRe_01_AnsteuerVorgabe_B_XIX_Klima: provided-interface=IF_LHRe_01_AnsteuerVorgabe_B
      SP_IF_LHRe_01_Config_NTC_A_XIX_Klima: provided-interface=IF_LHRe_01_Config_NTC_A
      SP_IF_LHRe_01_Config_NTC_B_XIX_Klima: provided-interface=IF_LHRe_01_Config_NTC_B
      SP_IF_LHRe_Global_Unterbrechen_Inv_XIX_Klima: provided-interface=IF_LHRe_Global_Unterbrechen_Inv
      SP_IF_Luftmenge_Innenraum_PMS_XIX_Klima: provided-interface=IF_Luftmenge_Innenraum_PMS
      SP_IF_MD1_Position_4Bit_XIX_Klima: provided-interface=IF_MD1_Position_4Bit
      SP_IF_Messung_Enable_PMS_XIX_Klima: provided-interface=IF_Messung_Enable_PMS
      SP_IF_MO_FSA_Sensorheizung_XIX_Klima: provided-interface=IF_MO_FSA_Sensorheizung
      SP_IF_MRollo_Position_4Bit_XIX_Klima: provided-interface=IF_MRollo_Position_4Bit
      SP_IF_Navigationsattribute_XIX_Klima: provided-interface=IF_Navigationsattribute
      SP_IF_NM_Klima_CBV_AWB_XIX_Klima: provided-interface=IF_NM_Klima_CBV_AWB
      SP_IF_NM_Klima_CBV_CRI_XIX_Klima: provided-interface=IF_NM_Klima_CBV_CRI
      SP_IF_NM_Klima_NM_State_XIX_Klima: provided-interface=IF_NM_Klima_NM_State
      SP_IF_OBDProtocol_Klima_XIX_Klima: provided-interface=IF_OBDProtocol_Klima
      SP_IF_PCU_Aussentemp_gef_XIX_Klima: provided-interface=IF_PCU_Aussentemp_gef
      SP_IF_PCU_Ein_XIX_Klima: provided-interface=IF_PCU_Ein
      SP_IF_PCU_FS_Luftfeuchte_rel_XIX_Klima: provided-interface=IF_PCU_FS_Luftfeuchte_rel
      SP_IF_PCU_FSA_Luftfeuchte_rel_XIX_Klima: provided-interface=IF_PCU_FSA_Luftfeuchte_rel
      SP_IF_PCU_Funktionstest_XIX_Klima: provided-interface=IF_PCU_Funktionstest
      SP_IF_PCU_Geblaese_Status_XIX_Klima: provided-interface=IF_PCU_Geblaese_Status
      SP_IF_PCU_Innen_Temp_XIX_Klima: provided-interface=IF_PCU_Innen_Temp
      SP_IF_PCU_Kennlinie_XIX_Klima: provided-interface=IF_PCU_Kennlinie
      SP_IF_PCU_Umluftklappe_Status_XIX_Klima: provided-interface=IF_PCU_Umluftklappe_Status
      SP_IF_Scheibenreinigung_XIX_Klima: provided-interface=IF_Scheibenreinigung
      SP_IF_SI_T_Mode_XIX_Klima: provided-interface=IF_SI_T_Mode
      SP_IF_SI_T_Schutz_XIX_Klima: provided-interface=IF_SI_T_Schutz
      SP_IF_SIL_Stufe_LED_HL_XIX_Klima: provided-interface=IF_SIL_Stufe_LED_HL
      SP_IF_SIL_Stufe_LED_HR_XIX_Klima: provided-interface=IF_SIL_Stufe_LED_HR
      SP_IF_SOK_FoD_Klima_Req_Challenge_XIX_Klima: provided-interface=IF_SOK_FoD_Klima_Req_Challenge
      SP_IF_Soll_Lehne_LLR_li_1_XIX_Klima: provided-interface=IF_Soll_Lehne_LLR_li_1
      SP_IF_Soll_Lehne_LLR_li_2_XIX_Klima: provided-interface=IF_Soll_Lehne_LLR_li_2
      SP_IF_Soll_Lehne_LLR_re_1_XIX_Klima: provided-interface=IF_Soll_Lehne_LLR_re_1
      SP_IF_Soll_Lehne_LLR_re_2_XIX_Klima: provided-interface=IF_Soll_Lehne_LLR_re_2
      SP_IF_Soll_Sitz_LLR_li_1_XIX_Klima: provided-interface=IF_Soll_Sitz_LLR_li_1
      SP_IF_Soll_Sitz_LLR_li_2_XIX_Klima: provided-interface=IF_Soll_Sitz_LLR_li_2
      SP_IF_Soll_Sitz_LLR_re_1_XIX_Klima: provided-interface=IF_Soll_Sitz_LLR_re_1
      SP_IF_Soll_Sitz_LLR_re_2_XIX_Klima: provided-interface=IF_Soll_Sitz_LLR_re_2
      SP_IF_STRG1_Adresse_Aktuator_XIX_Klima: provided-interface=IF_STRG1_Adresse_Aktuator
      SP_IF_STRG1_Geschwindigkeitsvorgabe_XIX_Klima: provided-interface=IF_STRG1_Geschwindigkeitsvorgabe
      SP_IF_STRG1_Notlauffreigabe_XIX_Klima: provided-interface=IF_STRG1_Notlauffreigabe
      SP_IF_STRG1_Select_Positionsvorgabe_XIX_Klima: provided-interface=IF_STRG1_Select_Positionsvorgabe
      SP_IF_STRG1_Soll_Position_Aktuator_XIX_Klima: provided-interface=IF_STRG1_Soll_Position_Aktuator
      SP_IF_STRG1_Spulenbestromung_XIX_Klima: provided-interface=IF_STRG1_Spulenbestromung
      SP_IF_STRG4_Adresse_Aktuator_XIX_Klima: provided-interface=IF_STRG4_Adresse_Aktuator
      SP_IF_STRG4_Clear_Event_Flags_XIX_Klima: provided-interface=IF_STRG4_Clear_Event_Flags
      SP_IF_STRG4_Drehrichtung_XIX_Klima: provided-interface=IF_STRG4_Drehrichtung
      SP_IF_STRG4_Freigabe_Blockiererkennung_XIX_Klima: provided-interface=IF_STRG4_Freigabe_Blockiererkennung
      SP_IF_STRG4_Geschwindigkeitsvorgabe_XIX_Klima: provided-interface=IF_STRG4_Geschwindigkeitsvorgabe
      SP_IF_STRG4_Notlauffreigabe_XIX_Klima: provided-interface=IF_STRG4_Notlauffreigabe
      SP_IF_STRG4_Notlaufposition_XIX_Klima: provided-interface=IF_STRG4_Notlaufposition
      SP_IF_STRG4_Programmierdaten_speichern_XIX_Klima: provided-interface=IF_STRG4_Programmierdaten_speichern
      SP_IF_STRG4_Select_Positionsvorgabe_XIX_Klima: provided-interface=IF_STRG4_Select_Positionsvorgabe
      SP_IF_STRG4_Soll_Position_Aktuator_XIX_Klima: provided-interface=IF_STRG4_Soll_Position_Aktuator
      SP_IF_STRG4_Spulenbestromung_XIX_Klima: provided-interface=IF_STRG4_Spulenbestromung
      SP_IF_STRG4_Start_Position_Aktuator_XIX_Klima: provided-interface=IF_STRG4_Start_Position_Aktuator
      SP_IF_STRG4_Stopmodus_XIX_Klima: provided-interface=IF_STRG4_Stopmodus
      SP_IF_Thermo_Pred_Innen_Kunde_Anf_XIX_Klima: provided-interface=IF_Thermo_Pred_Innen_Kunde_Anf
      SP_IF_Thermo_Pred_Innen_System_Anf_XIX_Klima: provided-interface=IF_Thermo_Pred_Innen_System_Anf
      SP_IF_Thermo_Pred_P_dyn_In_Efficien1_XIX_Klima: provided-interface=IF_Thermo_Pred_P_dyn_In_Efficien1
      SP_IF_Thermo_Pred_P_dyn_In_Efficien2_XIX_Klima: provided-interface=IF_Thermo_Pred_P_dyn_In_Efficien2
      SP_IF_Thermo_Pred_P_dyn_In_Standard_XIX_Klima: provided-interface=IF_Thermo_Pred_P_dyn_In_Standard
      SP_IF_Thermo_Pred_P_dyn_Innen_XIX_Klima: provided-interface=IF_Thermo_Pred_P_dyn_Innen
      SP_IF_Thermo_Pred_P_stat_In_Efficien1_XIX_Klima: provided-interface=IF_Thermo_Pred_P_stat_In_Efficien1
      SP_IF_Thermo_Pred_P_stat_In_Efficien2_XIX_Klima: provided-interface=IF_Thermo_Pred_P_stat_In_Efficien2
      SP_IF_Thermo_Pred_P_stat_In_Standard_XIX_Klima: provided-interface=IF_Thermo_Pred_P_stat_In_Standard
      SP_IF_Thermo_Pred_P_stat_Innen_XIX_Klima: provided-interface=IF_Thermo_Pred_P_stat_Innen
      SP_IF_Thermo_Pred_T_dyn_In_Efficien1_XIX_Klima: provided-interface=IF_Thermo_Pred_T_dyn_In_Efficien1
      SP_IF_Thermo_Pred_T_dyn_In_Efficien2_XIX_Klima: provided-interface=IF_Thermo_Pred_T_dyn_In_Efficien2
      SP_IF_Thermo_Pred_T_dyn_In_Standard_XIX_Klima: provided-interface=IF_Thermo_Pred_T_dyn_In_Standard
      SP_IF_Thermo_Pred_T_dyn_Innen_XIX_Klima: provided-interface=IF_Thermo_Pred_T_dyn_Innen
      SP_IF_Thermo_Verbrauch_BTL_Ueberlauf_XIX_Klima: provided-interface=IF_Thermo_Verbrauch_BTL_Ueberlauf
      SP_IF_Thermo_Verbrauch_BTL_XIX_Klima: provided-interface=IF_Thermo_Verbrauch_BTL
      SP_IF_Thermo_Verbrauch_Innen_Ueberlauf_XIX_Klima: provided-interface=IF_Thermo_Verbrauch_Innen_Ueberlauf
      SP_IF_Thermo_Verbrauch_Innen_XIX_Klima: provided-interface=IF_Thermo_Verbrauch_Innen
      SP_IF_UH_Jahr_XIX_Klima: provided-interface=IF_UH_Jahr
      SP_IF_UH_Monat_XIX_Klima: provided-interface=IF_UH_Monat
      SP_IF_UH_Tag_XIX_Klima: provided-interface=IF_UH_Tag
      SP_IF_Umluft_XIX_Klima: provided-interface=IF_Umluft
      SP_IF_Verbauposition_LLR_li_XIX_Klima: provided-interface=IF_Verbauposition_LLR_li
      SP_IF_Verbauposition_LLR_re_XIX_Klima: provided-interface=IF_Verbauposition_LLR_re
      SP_IF_ZAS_Kl_15_XIX_Klima: provided-interface=IF_ZAS_Kl_15
      SP_IF_ZAS_Kl_S_XIX_Klima: provided-interface=IF_ZAS_Kl_S
